VERSION "dbc-export 1 2025.20.8"

NS_ :

BS_:

BU_: ADSP APB APP APS BB BMS CC CP DAS DI DIF DIR EPAS3P EPAS3S EPBL EPBR GTW HVP ICR IDB PCS PM TCU UI UIS VC VCFRONT VCLEFT VCRIGHT VCSEC

BO_ 522 HVP_contactorState: 6 HVP
 SG_ HVP_packContNegativeState : 0|3@1+ (1,0) [1|7] "" Vector__XXX
 SG_ HVP_packContPositiveState : 3|3@1+ (1,0) [1|7] "" Vector__XXX
 SG_ HVP_fcContPositiveAuxOpen : 6|1@1+ (1,0) [0|1] "" Vector__XXX
 SG_ HVP_fcContNegativeAuxOpen : 7|1@1+ (1,0) [0|1] "" Vector__XXX
 SG_ HVP_packContactorSetState : 8|4@1+ (1,0) [1|15] "" Vector__XXX
 SG_ HVP_fcContNegativeState : 12|3@1+ (1,0) [1|7] "" Vector__XXX
 SG_ HVP_fcContPositiveState : 16|3@1+ (1,0) [1|7] "" Vector__XXX
 SG_ HVP_fcContactorSetState : 19|4@1+ (1,0) [1|15] "" Vector__XXX
 SG_ HVP_fcCtrsRequestStatus : 24|2@1+ (1,0) [0|3] "" Vector__XXX
 SG_ HVP_fcCtrsResetRequestRequired : 26|1@1+ (1,0) [0|1] "" Vector__XXX
 SG_ HVP_fcCtrsOpenNowRequested : 27|1@1+ (1,0) [0|1] "" Vector__XXX
 SG_ HVP_fcCtrsOpenRequested : 28|1@1+ (1,0) [0|1] "" Vector__XXX
 SG_ HVP_fcCtrsClosingAllowed : 29|1@1+ (1,0) [0|1] "" Vector__XXX
 SG_ HVP_packCtrsRequestStatus : 30|2@1+ (1,0) [0|3] "" Vector__XXX
 SG_ HVP_packCtrsResetRequestRequired : 32|1@1+ (1,0) [0|1] "" Vector__XXX
 SG_ HVP_packCtrsOpenNowRequested : 33|1@1+ (1,0) [0|1] "" Vector__XXX
 SG_ HVP_packCtrsOpenRequested : 34|1@1+ (1,0) [0|1] "" Vector__XXX
 SG_ HVP_packCtrsClosingAllowed : 35|1@1+ (1,0) [0|1] "" Vector__XXX
 SG_ HVP_dcLinkAllowedToEnergize : 36|1@1+ (1,0) [0|1] "" Vector__XXX
 SG_ HVP_pyroTestInProgress : 37|1@1+ (1,0) [0|1] "" Vector__XXX
 SG_ HVP_hvilDiag : 40|4@1+ (1,0) [0|15] "" Vector__XXX
 SG_ HVP_fcLinkAllowedToEnergize : 44|2@1+ (1,0) [0|3] "" Vector__XXX

BO_ 1962 HVP_debugMessage: 8 HVP
 SG_ HVP_debugMessageMultiplexer M : 0|4@1+ (1,0) [0|15] "" Vector__XXX
 SG_ HVP_gpioPassivePyroDepl m0 : 4|1@1+ (1,0) [0|1] "" Vector__XXX
 SG_ HVP_gpioPyroIsoEn m0 : 5|1@1+ (1,0) [0|1] "" Vector__XXX
 SG_ HVP_gpioCpFaultIn m0 : 6|1@1+ (1,0) [0|1] "" Vector__XXX
 SG_ HVP_gpioPackContPowerEn m0 : 7|1@1+ (1,0) [0|1] "" Vector__XXX
 SG_ HVP_gpioHvCablesOk m0 : 8|1@1+ (1,0) [0|1] "" Vector__XXX
 SG_ HVP_gpioHvpSelfEnable m0 : 9|1@1+ (1,0) [0|1] "" Vector__XXX
 SG_ HVP_gpioLed m0 : 10|1@1+ (1,0) [0|1] "" Vector__XXX
 SG_ HVP_gpioCrashSignal m0 : 11|1@1+ (1,0) [0|1] "" Vector__XXX
 SG_ HVP_gpioShuntDataReady m0 : 12|1@1+ (1,0) [0|1] "" Vector__XXX
 SG_ HVP_gpioFcContPosAux m0 : 13|1@1+ (1,0) [0|1] "" Vector__XXX
 SG_ HVP_gpioFcContNegAux m0 : 14|1@1+ (1,0) [0|1] "" Vector__XXX
 SG_ HVP_gpioBmsEout m0 : 15|1@1+ (1,0) [0|1] "" Vector__XXX
 SG_ HVP_gpioCpFaultOut m0 : 16|1@1+ (1,0) [0|1] "" Vector__XXX
 SG_ HVP_gpioPyroPor m0 : 17|1@1+ (1,0) [0|1] "" Vector__XXX
 SG_ HVP_gpioShuntEn m0 : 18|1@1+ (1,0) [0|1] "" Vector__XXX
 SG_ HVP_gpioHvpVerEn m0 : 19|1@1+ (1,0) [0|1] "" Vector__XXX
 SG_ HVP_gpioFcContFlywheelEnable m0 : 20|1@1+ (1,0) [0|1] "" Vector__XXX
 SG_ HVP_gpioCpLatchEnable m0 : 21|1@1+ (1,0) [0|1] "" Vector__XXX
 SG_ HVP_gpioFcContPowerEnable m0 : 22|1@1+ (1,0) [0|1] "" Vector__XXX
 SG_ HVP_gpioHvilEnable m0 : 23|1@1+ (1,0) [0|1] "" Vector__XXX
 SG_ HVP_gpioPortSelSpiRdy m0 : 24|1@1+ (1,0) [0|1] "" Vector__XXX
 SG_ HVP_gpioPyroUnlock m0 : 25|1@1+ (1,0) [0|1] "" Vector__XXX
 SG_ HVP_hvp1v5Ref m0 : 26|12@1+ (0.1,0) [0|3] "V" Vector__XXX
 SG_ HVP_packCurrentMia m0 : 38|1@1+ (1,0) [0|1] "" Vector__XXX
 SG_ HVP_auxCurrentMia m0 : 39|1@1+ (1,0) [0|1] "" Vector__XXX
 SG_ HVP_currentSenseMia m0 : 40|1@1+ (1,0) [0|1] "" Vector__XXX
 SG_ HVP_shuntThermistorMissing m0 : 42|1@1+ (1,0) [0|1] "" Vector__XXX
 SG_ HVP_shuntThermistorExpected m0 : 43|1@1+ (1,0) [0|1] "" Vector__XXX
 SG_ HVP_shuntThermistorMia m0 : 44|1@1+ (1,0) [0|1] "" Vector__XXX
 SG_ HVP_shuntUnexpectedThermistor m0 : 45|1@1+ (1,0) [0|1] "" Vector__XXX
 SG_ HVP_shuntHwMia m0 : 46|1@1+ (1,0) [0|1] "" Vector__XXX
 SG_ HVP_shuntCurrentIrrational m0 : 47|1@1+ (1,0) [0|1] "" Vector__XXX
 SG_ HVP_shuntAsicTCompActive m0 : 48|1@1+ (1,0) [0|1] "" Vector__XXX
 SG_ HVP_ecuLogUploadRequest m0 : 49|2@1+ (1,0) [0|3] "" Vector__XXX
 SG_ HVP_packContVoltage m2 : 4|12@1+ (0.1,0) [0|30] "V" Vector__XXX
 SG_ HVP_packNegativeV m2 : 16|16@1- (0.1,0) [-550|550] "V" Vector__XXX
 SG_ HVP_packPositiveV m2 : 32|16@1- (0.1,0) [-550|550] "V" Vector__XXX
 SG_ HVP_pyroAnalog m2 : 48|12@1+ (0.1,0) [0|3] "V" Vector__XXX
 SG_ HVP_fcContCoilCurrent m4 : 4|12@1+ (0.1,0) [0|7.5] "A" Vector__XXX
 SG_ HVP_fcContVoltage m4 : 16|12@1+ (0.1,0) [0|30] "V" Vector__XXX
 SG_ HVP_hvilInVoltage m4 : 28|12@1+ (0.1,0) [0|30] "V" Vector__XXX
 SG_ HVP_hvilOutVoltage m4 : 40|12@1+ (0.1,0) [0|30] "V" Vector__XXX
 SG_ HVP_shuntGainInvalidCountDbg m4 : 56|8@1+ (1,0) [0|255] "counts" Vector__XXX
 SG_ HVP_fcLinkPositiveV m5 : 8|16@1- (0.1,0) [-550|550] "V" Vector__XXX
 SG_ HVP_packContCoilCurrent m5 : 24|12@1+ (0.1,0) [0|7.5] "A" Vector__XXX
 SG_ HVP_battery12V m5 : 36|12@1+ (0.1,0) [0|30] "V" Vector__XXX

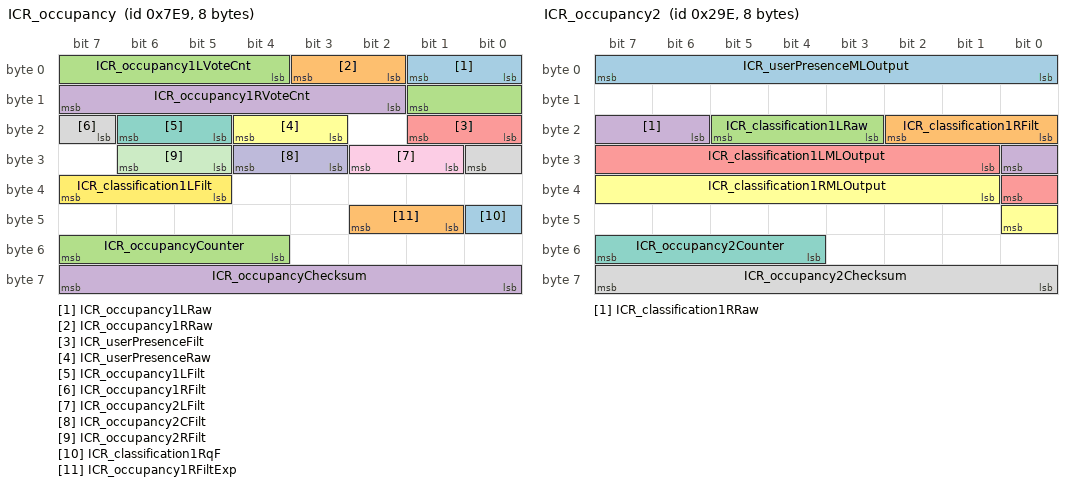
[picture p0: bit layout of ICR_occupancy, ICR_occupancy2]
BO_ 2025 ICR_occupancy: 8 ICR
 SG_ ICR_occupancy1LRaw : 0|2@1+ (1,0) [0|2] "" Vector__XXX
 SG_ ICR_occupancy1RRaw : 2|2@1+ (1,0) [0|2] "" Vector__XXX
 SG_ ICR_occupancy1LVoteCnt : 4|6@1- (1,0) [-32|31] "" Vector__XXX
 SG_ ICR_occupancy1RVoteCnt : 10|6@1- (1,0) [-32|31] "" Vector__XXX
 SG_ ICR_userPresenceFilt : 16|2@1+ (1,0) [0|2] "" Vector__XXX
 SG_ ICR_userPresenceRaw : 19|2@1+ (1,0) [0|2] "" Vector__XXX
 SG_ ICR_occupancy1LFilt : 21|2@1+ (1,0) [0|2] "" Vector__XXX
 SG_ ICR_occupancy1RFilt : 23|2@1+ (1,0) [0|2] "" Vector__XXX
 SG_ ICR_occupancy2LFilt : 25|2@1+ (1,0) [0|2] "" Vector__XXX
 SG_ ICR_occupancy2CFilt : 27|2@1+ (1,0) [0|2] "" Vector__XXX
 SG_ ICR_occupancy2RFilt : 29|2@1+ (1,0) [0|2] "" Vector__XXX
 SG_ ICR_classification1LFilt : 37|3@1+ (1,0) [1|7] "" Vector__XXX
 SG_ ICR_classification1RqF : 40|1@1+ (1,0) [0|1] "" Vector__XXX
 SG_ ICR_occupancy1RFiltExp : 41|2@1+ (1,0) [0|2] "" Vector__XXX
 SG_ ICR_occupancyCounter : 52|4@1+ (1,0) [0|15] "" Vector__XXX
 SG_ ICR_occupancyChecksum : 56|8@1+ (1,0) [0|255] "" Vector__XXX

BO_ 670 ICR_occupancy2: 8 ICR
 SG_ ICR_userPresenceMLOutput : 0|8@1+ (0.004,0) [0|1.016] "points" Vector__XXX
 SG_ ICR_classification1RFilt : 16|3@1+ (1,0) [1|7] "" Vector__XXX
 SG_ ICR_classification1LRaw : 19|3@1+ (1,0) [1|7] "" Vector__XXX
 SG_ ICR_classification1RRaw : 22|3@1+ (1,0) [1|7] "" Vector__XXX
 SG_ ICR_classification1LMLOutput : 25|8@1+ (0.004,0) [0|1.016] "points" Vector__XXX
 SG_ ICR_classification1RMLOutput : 33|8@1+ (0.004,0) [0|1.016] "points" Vector__XXX
 SG_ ICR_occupancy2Counter : 52|4@1+ (1,0) [0|15] "" Vector__XXX
 SG_ ICR_occupancy2Checksum : 56|8@1+ (1,0) [0|255] "" Vector__XXX

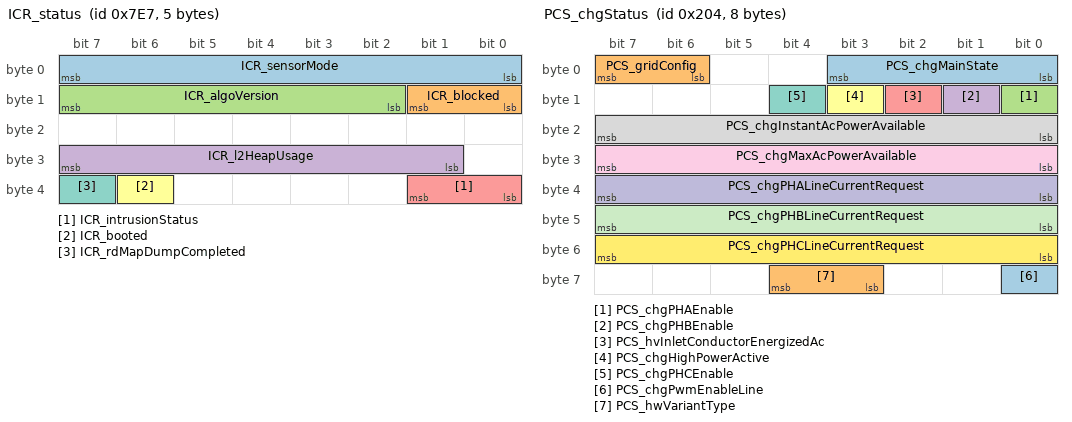
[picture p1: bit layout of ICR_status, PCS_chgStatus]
BO_ 2023 ICR_status: 5 ICR
 SG_ ICR_sensorMode : 0|8@1+ (1,0) [0|255] "" Vector__XXX
 SG_ ICR_blocked : 8|2@1+ (1,0) [1|3] "" Vector__XXX
 SG_ ICR_algoVersion : 10|6@1+ (1,0) [0|63] "" Vector__XXX
 SG_ ICR_l2HeapUsage : 25|7@1+ (1,0) [0|127] "PCT" Vector__XXX
 SG_ ICR_intrusionStatus : 32|2@1+ (1,0) [0|3] "" Vector__XXX
 SG_ ICR_booted : 38|1@1+ (1,0) [0|1] "" Vector__XXX
 SG_ ICR_rdMapDumpCompleted : 39|1@1+ (1,0) [0|1] "" Vector__XXX

BO_ 828 IDB_info: 8 IDB
 SG_ IDB_infoIndex M : 0|8@1+ (1,0) [0|255] "" Vector__XXX
 SG_ IDB_infoPcbaID m11 : 16|8@1+ (1,0) [0|255] "" Vector__XXX
 SG_ IDB_infoAssemblyID m11 : 24|8@1+ (1,0) [0|255] "" Vector__XXX
 SG_ IDB_infoUsageID m11 : 32|16@1+ (1,0) [0|65535] "" Vector__XXX
 SG_ IDB_infoSubUsageID m11 : 48|16@1+ (1,0) [0|65535] "" Vector__XXX

BO_ 516 PCS_chgStatus: 8 PCS
 SG_ PCS_chgMainState : 0|4@1+ (1,0) [0|15] "" Vector__XXX
 SG_ PCS_gridConfig : 6|2@1+ (1,0) [1|3] "" Vector__XXX
 SG_ PCS_chgPHAEnable : 8|1@1+ (1,0) [0|1] "" Vector__XXX
 SG_ PCS_chgPHBEnable : 9|1@1+ (1,0) [0|1] "" Vector__XXX
 SG_ PCS_hvInletConductorEnergizedAc : 10|1@1+ (1,0) [0|1] "" Vector__XXX
 SG_ PCS_chgHighPowerActive : 11|1@1+ (1,0) [0|1] "" Vector__XXX
 SG_ PCS_chgPHCEnable : 12|1@1+ (1,0) [0|1] "" Vector__XXX
 SG_ PCS_chgInstantAcPowerAvailable : 16|8@1+ (0.1,0) [0|20] "kW" Vector__XXX
 SG_ PCS_chgMaxAcPowerAvailable : 24|8@1+ (0.1,0) [0|20] "kW" Vector__XXX
 SG_ PCS_chgPHALineCurrentRequest : 32|8@1+ (0.1,0) [0|20] "A" Vector__XXX
 SG_ PCS_chgPHBLineCurrentRequest : 40|8@1+ (0.1,0) [0|20] "A" Vector__XXX
 SG_ PCS_chgPHCLineCurrentRequest : 48|8@1+ (0.1,0) [0|20] "A" Vector__XXX
 SG_ PCS_chgPwmEnableLine : 56|1@1+ (1,0) [0|1] "" Vector__XXX
 SG_ PCS_hwVariantType : 59|2@1+ (1,0) [0|2] "" Vector__XXX

BO_ 548 PCS_dcdcStatus: 8 PCS
 SG_ PCS_dcdcPrechargeStatus : 0|2@1+ (1,0) [0|3] "" Vector__XXX
 SG_ PCS_dcdcLvSupportStatus : 2|2@1+ (1,0) [0|3] "" Vector__XXX
 SG_ PCS_dcdcHvBusDischargeStatus : 4|2@1+ (1,0) [0|3] "" Vector__XXX
 SG_ PCS_coldSleepAllowed : 8|1@1+ (1,0) [0|1] "" Vector__XXX
 SG_ PCS_dcdcPchgHVBusLowRDetected : 9|1@1+ (1,0) [0|1] "" Vector__XXX
 SG_ PCS_dcdcSubState : 10|5@1+ (1,0) [0|31] "" Vector__XXX
 SG_ PCS_dcdcFaulted : 15|1@1+ (1,0) [0|1] "" Vector__XXX
 SG_ PCS_okToBePowerCycled : 27|1@1+ (1,0) [0|1] "" Vector__XXX
 SG_ PCS_dcdcOutputIsLimited : 28|1@1+ (1,0) [0|1] "" Vector__XXX
 SG_ PCS_dcdcMaxOutputCurrentAllowed : 29|12@1+ (0.1,0) [0|400] "A" Vector__XXX
 SG_ PCS_dcdcPrechargeRtyCnt : 41|3@1+ (1,0) [0|7] "" Vector__XXX
 SG_ PCS_dcdcLvSupportRtyCnt : 44|4@1+ (1,0) [0|15] "" Vector__XXX
 SG_ PCS_dcdcDischargeRtyCnt : 48|4@1+ (1,0) [0|15] "" Vector__XXX
 SG_ PCS_dcdcPwmEnableLine : 52|1@1+ (1,0) [0|1] "" Vector__XXX
 SG_ PCS_dcdcSupportingFixedLvTarget : 53|1@1+ (1,0) [0|1] "" Vector__XXX
 SG_ PCS_ecuLogUploadRequest : 54|2@1+ (1,0) [0|3] "" Vector__XXX
 SG_ PCS_dcdcPrechargeRestartCnt : 56|3@1+ (1,0) [0|7] "" Vector__XXX
 SG_ PCS_dcdcInitialPrechargeSubState : 59|5@1+ (1,0) [0|31] "" Vector__XXX

BO_ 708 PCS_logging: 8 PCS
 SG_ PCS_logMessageSelect M : 0|5@1+ (1,0) [0|31] "" Vector__XXX
 SG_ PCS_chgPhAInputIrms m0 : 5|9@1+ (0.1,0) [0|51.1] "A" Vector__XXX
 SG_ PCS_chgPhAIntBusV m0 : 14|9@1+ (1,0) [0|511] "V" Vector__XXX
 SG_ PCS_chgPhAIntBusVTarget m0 : 23|9@1+ (1,0) [0|511] "V" Vector__XXX
 SG_ PCS_chgPhAOutputI m0 : 32|8@1+ (0.1,0) [0|25.5] "A" Vector__XXX
 SG_ PCS_chgPhAInputCurrentLimitReaso m0 : 40|3@1+ (1,0) [0|7] "" Vector__XXX
 SG_ PCS_chgPhBInputIrms m1 : 5|9@1+ (0.1,0) [0|51.1] "A" Vector__XXX
 SG_ PCS_chgPhBIntBusV m1 : 14|9@1+ (1,0) [0|511] "V" Vector__XXX
 SG_ PCS_chgPhBIntBusVTarget m1 : 23|9@1+ (1,0) [0|511] "V" Vector__XXX
 SG_ PCS_chgPhBOutputI m1 : 32|8@1+ (0.1,0) [0|25.5] "A" Vector__XXX
 SG_ PCS_chgPhBInputCurrentLimitReaso m1 : 40|3@1+ (1,0) [0|7] "" Vector__XXX
 SG_ PCS_chgPhCInputIrms m2 : 5|9@1+ (0.1,0) [0|51.1] "A" Vector__XXX
 SG_ PCS_chgPhCIntBusV m2 : 14|9@1+ (1,0) [0|511] "V" Vector__XXX
 SG_ PCS_chgPhCIntBusVTarget m2 : 23|9@1+ (1,0) [0|511] "V" Vector__XXX
 SG_ PCS_chgPhCOutputI m2 : 32|8@1+ (0.1,0) [0|25.5] "A" Vector__XXX
 SG_ PCS_chgPhCInputCurrentLimitReaso m2 : 40|3@1+ (1,0) [0|7] "" Vector__XXX
 SG_ PCS_chgInputL1NVrms m3 : 5|12@1+ (0.2,0) [0|819] "V" Vector__XXX
 SG_ PCS_chgInputL2NVrms m3 : 17|12@1+ (0.2,0) [0|819] "V" Vector__XXX
 SG_ PCS_chgInputL3NVrms m3 : 29|12@1+ (0.2,0) [0|819] "V" Vector__XXX
 SG_ PCS_chgInputL1L2Vrms m3 : 41|12@1+ (0.2,0) [0|819] "V" Vector__XXX
 SG_ PCS_chgInputNGVrms m3 : 53|9@1+ (1,0) [0|511] "V" Vector__XXX
 SG_ PCS_chgInputFrequencyL1N m4 : 5|12@1+ (0.01,40) [40|80.95] "Hz" Vector__XXX
 SG_ PCS_chgInputFrequencyL2N m4 : 17|12@1+ (0.01,40) [40|80.95] "Hz" Vector__XXX
 SG_ PCS_chgInputFrequencyL3N m4 : 29|12@1+ (0.01,40) [40|80.95] "Hz" Vector__XXX
 SG_ PCS_chgInternalPhaseConfig m4 : 41|4@1+ (1,0) [1|15] "" Vector__XXX
 SG_ PCS_chgPhasesPriority m4 : 45|6@1+ (1,0) [0|63] "" Vector__XXX
 SG_ PCS_chgOutputV m4 : 51|12@1+ (0.146484375,0) [0|599.853515625] "V" Vector__XXX
 SG_ PCS_chgPhAState m5 : 5|4@1+ (1,0) [0|15] "" Vector__XXX
 SG_ PCS_chgPhBState m5 : 9|4@1+ (1,0) [0|15] "" Vector__XXX
 SG_ PCS_chgPhCState m5 : 13|4@1+ (1,0) [0|15] "" Vector__XXX
 SG_ PCS_chgPhALastShutdownReason m5 : 17|5@1+ (1,0) [0|31] "" Vector__XXX
 SG_ PCS_chgPhBLastShutdownReason m5 : 22|5@1+ (1,0) [0|31] "" Vector__XXX
 SG_ PCS_chgPhCLastShutdownReason m5 : 27|5@1+ (1,0) [0|31] "" Vector__XXX
 SG_ PCS_chgPhARetryCount m5 : 32|3@1+ (1,0) [0|7] "" Vector__XXX
 SG_ PCS_chgPhBRetryCount m5 : 35|3@1+ (1,0) [0|7] "" Vector__XXX
 SG_ PCS_chgPhCRetryCount m5 : 38|3@1+ (1,0) [0|7] "" Vector__XXX
 SG_ PCS_chgRetryCount m5 : 41|3@1+ (1,0) [0|7] "" Vector__XXX
 SG_ PCS_chgPhManCurrentToDist m5 : 44|10@1+ (0.1,0) [0|100] "A" Vector__XXX
 SG_ PCS_chgL1NPllLocked m5 : 54|1@1+ (1,0) [0|1] "" Vector__XXX
 SG_ PCS_chgL2NPllLocked m5 : 55|1@1+ (1,0) [0|1] "" Vector__XXX
 SG_ PCS_chgL3NPllLocked m5 : 56|1@1+ (1,0) [0|1] "" Vector__XXX
 SG_ PCS_chgL1L2PllLocked m5 : 57|1@1+ (1,0) [0|1] "" Vector__XXX
 SG_ PCS_chgNgPllLocked m5 : 58|1@1+ (1,0) [0|1] "" Vector__XXX
 SG_ PCS_chgPhManOptimalPhsToUse m5 : 59|2@1+ (1,0) [0|3] "" Vector__XXX
 SG_ PCS_chg5VL1Enable m5 : 61|1@1+ (1,0) [0|1] "" Vector__XXX
 SG_ PCS_dcdcMaxLvOutputCurrent m6 : 8|12@1+ (0.1,0) [0|400] "A" Vector__XXX
 SG_ PCS_dcdcCurrentLimit m6 : 20|12@1+ (0.1,0) [0|400] "A" Vector__XXX
 SG_ PCS_dcdcLvOutputCurrentTempLimit m6 : 32|12@1+ (0.1,0) [0|400] "A" Vector__XXX
 SG_ PCS_dcdcLvOutputCurrentFiltered m6 : 44|12@1+ (0.1,0) [0|400] "A" Vector__XXX
 SG_ PCS_dcdcUnifiedCommand m7 : 5|10@1+ (0.001,0) [0|1] "1" Vector__XXX
 SG_ PCS_dcdcCLAControllerOutput m7 : 16|10@1+ (0.001,0) [0|1] "1" Vector__XXX
 SG_ PCS_dcdcTankVoltage m7 : 26|11@1- (1,0) [-1024|1023] "V" Vector__XXX
 SG_ PCS_dcdcTankVoltageTarget m7 : 37|10@1+ (1,0) [0|1023] "V" Vector__XXX
 SG_ PCS_dcdcClaCurrentFreq m7 : 48|12@1+ (0.09765625,0) [0|399.9] "kHz" Vector__XXX
 SG_ PCS_dcdcTCommMeasured m8 : 5|16@1- (0.001953125,0) [-64|63.998] "us" Vector__XXX
 SG_ PCS_dcdcShortTimeUs m8 : 21|16@1+ (0.00048828125,0) [0|31.9995] "us" Vector__XXX
 SG_ PCS_dcdcHalfPeriodUs m8 : 37|16@1+ (0.00048828125,0) [0|31.9995] "us" Vector__XXX
 SG_ PCS_dcdcLvBusVoltTargetWithOffse m8 : 53|11@1+ (0.01,0) [0|20] "V" Vector__XXX
 SG_ PCS_cpu2BootState m9 : 5|2@1+ (1,0) [0|3] "" Vector__XXX
 SG_ PCS_acChargeSelfTestState m9 : 7|1@1+ (1,0) [0|1] "" Vector__XXX
 SG_ PCS_1V5Min10s m9 : 8|11@1+ (0.001,0) [0|2.047] "V" Vector__XXX
 SG_ PCS_1V5Max10s m9 : 19|11@1+ (0.001,0) [0|2.047] "V" Vector__XXX
 SG_ PCS_1V2Min10s m9 : 32|11@1+ (0.001,0) [0|2.047] "V" Vector__XXX
 SG_ PCS_1V2Max10s m9 : 43|11@1+ (0.001,0) [0|2.047] "V" Vector__XXX
 SG_ PCS_5VNMax10s m9 : 54|10@1+ (0.01,0) [0|10.23] "V" Vector__XXX
 SG_ PCS_chgPhAIntBusVMin10s m10 : 5|9@1+ (1,0) [0|511] "V" Vector__XXX
 SG_ PCS_chgPhAIntBusVMax10s m10 : 14|9@1+ (1,0) [0|511] "V" Vector__XXX
 SG_ PCS_chgPhAPchgVoltDeltaMax10s m10 : 23|8@1+ (0.5,0) [0|127.5] "V" Vector__XXX
 SG_ PCS_chgPhALifetimekWh m10 : 31|24@1+ (0.01,0) [0|167772.15] "kWh" Vector__XXX
 SG_ PCS_chgPhATransientRetryCount m10 : 55|9@1+ (0.1,0) [0|51.1] "-" Vector__XXX
 SG_ PCS_chgPhBIntBusVMin10s m11 : 5|9@1+ (1,0) [0|511] "V" Vector__XXX
 SG_ PCS_chgPhBIntBusVMax10s m11 : 14|9@1+ (1,0) [0|511] "V" Vector__XXX
 SG_ PCS_chgPhBPchgVoltDeltaMax10s m11 : 23|8@1+ (0.5,0) [0|127.5] "V" Vector__XXX
 SG_ PCS_chgPhBLifetimekWh m11 : 31|24@1+ (0.01,0) [0|167772.15] "kWh" Vector__XXX
 SG_ PCS_chgPhBTransientRetryCount m11 : 55|9@1+ (0.1,0) [0|51.1] "-" Vector__XXX
 SG_ PCS_chgPhCIntBusVMin10s m12 : 5|9@1+ (1,0) [0|511] "V" Vector__XXX
 SG_ PCS_chgPhCIntBusVMax10s m12 : 14|9@1+ (1,0) [0|511] "V" Vector__XXX
 SG_ PCS_chgPhCPchgVoltDeltaMax10s m12 : 23|8@1+ (0.5,0) [0|127.5] "V" Vector__XXX
 SG_ PCS_chgPhCLifetimekWh m12 : 31|24@1+ (0.01,0) [0|167772.15] "kWh" Vector__XXX
 SG_ PCS_chgPhCTransientRetryCount m12 : 55|9@1+ (0.1,0) [0|51.1] "-" Vector__XXX
 SG_ PCS_chgPhANoFlowBucket m20 : 5|9@1+ (0.01,0) [0|5.11] "-" Vector__XXX
 SG_ PCS_chgPhBNoFlowBucket m20 : 14|9@1+ (0.01,0) [0|5.11] "-" Vector__XXX
 SG_ PCS_chgPhCNoFlowBucket m20 : 23|9@1+ (0.01,0) [0|5.11] "-" Vector__XXX
 SG_ PCS_chgCurrentSensorOutOfBandUs m20 : 32|10@1+ (0.01,0) [0|10.23] "us" Vector__XXX
 SG_ PCS_chgAcpwHeartbeatState m20 : 42|3@1+ (1,0) [0|7] "" Vector__XXX
 SG_ PCS_chgKwhLostByFreqDroop m20 : 48|8@1+ (0.1,0) [0|25.5] "kWh" Vector__XXX
 SG_ PCS_chgReqKwhLostByFreqDroop m20 : 56|8@1+ (0.1,0) [0|25.5] "kWh" Vector__XXX
 SG_ PCS_dcdcLvSupportLifetimekWh m22 : 8|24@1+ (0.01,0) [0|167772.15] "kWh" Vector__XXX
 SG_ PCS_chgPwmEnableLineErrorCount m22 : 32|10@1+ (1,0) [0|1023] "" Vector__XXX
 SG_ PCS_dcdcPwmEnableLineErrorCount m22 : 42|10@1+ (1,0) [0|1023] "" Vector__XXX
 SG_ PCS_numAlertsSet m22 : 56|7@1+ (1,0) [0|127] "" Vector__XXX
 SG_ PCS_dcdcPchgStartLvBusVolt m24 : 5|10@1+ (0.0390625,0) [0|39.9609375] "V" Vector__XXX
 SG_ PCS_dcdcPchgStartHvBusVolt m24 : 16|12@1+ (0.146484375,0) [0|599.853515625] "V" Vector__XXX
 SG_ PCS_processorDieIdLot m26 : 8|24@1+ (1,0) [0|16777215] "" Vector__XXX
 SG_ PCS_processorDieIdWafer m26 : 32|8@1+ (1,0) [0|255] "" Vector__XXX
 SG_ PCS_processorDieIdX m26 : 40|12@1+ (1,0) [0|4095] "" Vector__XXX
 SG_ PCS_processorDieIdY m26 : 52|12@1+ (1,0) [0|4095] "" Vector__XXX

BO_ 463 PM_systemState: 8 PM
 SG_ PM_hvilSystemStatus : 24|2@1+ (1,0) [0|2] "" Vector__XXX

BO_ 1409 TCU_log: 8 TCU
 SG_ TCU_logMux M : 0|32@1+ (1,0) [0|4294967295] "" Vector__XXX
 SG_ TCU_cpuTemp m0 : 32|32@1+ (1,0) [0|4294967295] "C" Vector__XXX
 SG_ TCU_cpuUsage m1 : 32|32@1+ (1,0) [0|4294967295] "%" Vector__XXX
 SG_ TCU_mdmCoreTemperature m2 : 32|32@1+ (1,0) [0|4294967295] "C" Vector__XXX
 SG_ TCU_availableMemory m3 : 32|32@1+ (1,0) [0|4294967295] "KB" Vector__XXX
 SG_ TCU_pwm m4 : 32|32@1+ (1,0) [0|4294967295] "" Vector__XXX
 SG_ TCU_pwmcap m5 : 32|32@1+ (1,0) [0|4294967295] "" Vector__XXX
 SG_ TCU_totalResumes m6 : 32|32@1+ (1,0) [0|4294967295] "" Vector__XXX
 SG_ TCU_mdmUplinkQueueSize m7 : 32|32@1+ (1,0) [0|4294967295] "bytes" Vector__XXX
 SG_ TCU_mdmRSRP m8 : 32|32@1- (1,0) [-2147483648|2147483647] "dBm" Vector__XXX
 SG_ TCU_mdmSINR m9 : 32|32@1- (1,0) [-2147483648|2147483647] "dBm" Vector__XXX
 SG_ TCU_mdmUplinkAllowedRate m10 : 32|32@1+ (1,0) [0|4294967295] "Kbps" Vector__XXX
 SG_ TCU_mdmServiceState m12 : 32|32@1+ (1,0) [0|4294967295] "" Vector__XXX
 SG_ TCU_mdmIMSStatus m13 : 32|32@1+ (1,0) [0|4294967295] "" Vector__XXX
 SG_ TCU_mdmSIMStatus m14 : 32|32@1+ (1,0) [0|4294967295] "" Vector__XXX
 SG_ TCU_mdmBusyActive m15 : 32|32@1+ (1,0) [0|4294967294] "" Vector__XXX

BO_ 1056 UIS_log: 8 UIS
 SG_ UIS_logMux M : 0|32@1+ (1,0) [0|4294967295] "" Vector__XXX
 SG_ UIS_wifiTemperature m11 : 32|32@1+ (1,0) [0|4294967295] "" Vector__XXX
 SG_ UIS_wifiStackState m12 : 32|32@1+ (1,0) [0|4294967295] "" Vector__XXX
 SG_ UIS_wifiBars m14 : 32|32@1+ (1,0) [0|4294967295] "" Vector__XXX
 SG_ UIS_wifiAutoJoinLowRSSI m15 : 32|32@1+ (1,0) [0|1] "" Vector__XXX
 SG_ UIS_valetMode m26 : 32|32@1+ (1,0) [0|1] "" Vector__XXX
 SG_ UIS_uiQtCarUptime m27 : 32|32@1+ (1,0) [0|4294967295] "" Vector__XXX
 SG_ UIS_uiMeanFPS m29 : 32|32@1+ (1,0) [0|4294967295] "" Vector__XXX
 SG_ UIS_tunerVoltageOperation m34 : 32|32@1+ (1,0) [0|4294967295] "" Vector__XXX
 SG_ UIS_tunerVoltageAntenna2 m36 : 32|32@1+ (1,0) [0|4294967295] "" Vector__XXX
 SG_ UIS_tunerVoltageAntenna1 m37 : 32|32@1+ (1,0) [0|4294967295] "" Vector__XXX
 SG_ UIS_tunerCurrentAntenna2 m42 : 32|32@1+ (1,0) [0|4294967295] "" Vector__XXX
 SG_ UIS_tunerCurrentAntenna1 m43 : 32|32@1+ (1,0) [0|4294967295] "" Vector__XXX
 SG_ UIS_tegraModemManState m56 : 32|32@1+ (1,0) [0|4294967295] "" Vector__XXX
 SG_ UIS_systemWakeTime m57 : 32|32@1+ (1,0) [0|4294967295] "" Vector__XXX
 SG_ UIS_systemUptime m58 : 32|32@1+ (1,0) [0|4294967295] "" Vector__XXX
 SG_ UIS_suspensionGeofence m60 : 32|32@1+ (1,0) [0|1] "" Vector__XXX
 SG_ UIS_superchargePaymentNeeded m61 : 32|32@1+ (1,0) [0|4294967295] "" Vector__XXX
 SG_ UIS_sleepType m70 : 32|32@1+ (1,0) [0|4294967295] "" Vector__XXX
 SG_ UIS_sleepTime m71 : 32|32@1+ (1,0) [0|4294967295] "" Vector__XXX
 SG_ UIS_sleepState m72 : 32|32@1+ (1,0) [0|4294967295] "" Vector__XXX
 SG_ UIS_slackerLoginResult m74 : 32|32@1+ (1,0) [0|4294967295] "" Vector__XXX
 SG_ UIS_sentryState m80 : 32|32@1+ (1,0) [0|4294967295] "" Vector__XXX
 SG_ UIS_sentryNeedsNap m81 : 32|32@1+ (1,0) [0|4294967295] "" Vector__XXX
 SG_ UIS_sentryIncidentCount m82 : 32|32@1+ (1,0) [0|4294967295] "" Vector__XXX
 SG_ UIS_scheduledChargingMode m83 : 32|32@1+ (1,0) [0|4294967295] "" Vector__XXX
 SG_ UIS_scheduleChargeStartTime m84 : 32|32@1+ (1,0) [0|4294967295] "" Vector__XXX
 SG_ UIS_scheduleChargeEndTime m85 : 32|32@1+ (1,0) [0|4294967295] "" Vector__XXX
 SG_ UIS_remoteRequestType m86 : 32|32@1+ (1,0) [0|4294967295] "" Vector__XXX
 SG_ UIS_rearDisplayUserPresent m89 : 32|32@1+ (1,0) [0|1] "" Vector__XXX
 SG_ UIS_rearDisplayState m90 : 32|32@1+ (1,0) [0|4294967295] "" Vector__XXX
 SG_ UIS_powerManagerState m100 : 32|5@1+ (1,0) [0|31] "" Vector__XXX
 SG_ UIS_polytopiax8664MemUsage m101 : 32|32@1+ (1,0) [0|4294967295] "" Vector__XXX
 SG_ UIS_polytopiax8664CPUUsage m102 : 32|32@1+ (1,0) [0|4294967295] "" Vector__XXX
 SG_ UIS_navAudioVolume m132 : 32|32@1+ (1,0) [0|4294967295] "" Vector__XXX
 SG_ UIS_muteNavVolume m133 : 32|32@1+ (1,0) [0|4294967295] "" Vector__XXX
 SG_ UIS_modemECallppAvail m145 : 32|32@1+ (1,0) [0|1] "" Vector__XXX
 SG_ UIS_modemBusyActive m146 : 32|32@1+ (1,0) [0|1] "" Vector__XXX
 SG_ UIS_mirrorGeofenceActive m147 : 32|32@1+ (1,0) [0|1] "" Vector__XXX
 SG_ UIS_mediaPlaybackStatus m150 : 32|32@1+ (1,0) [0|4294967295] "" Vector__XXX
 SG_ UIS_mediaNeedAuthToken m151 : 32|32@1+ (1,0) [0|1] "" Vector__XXX
 SG_ UIS_inSuperchargerGeofence m156 : 32|32@1+ (1,0) [0|1] "" Vector__XXX
 SG_ UIS_homelinkState m158 : 32|32@1+ (1,0) [0|4294967295] "" Vector__XXX
 SG_ UIS_headsetPairResult m163 : 32|32@1+ (1,0) [0|4294967295] "" Vector__XXX
 SG_ UIS_headsetConnectionState m164 : 32|32@1+ (1,0) [0|4294967295] "" Vector__XXX
 SG_ UIS_gpsmanagerMemUsage m178 : 32|32@1+ (1,0) [0|4294967295] "" Vector__XXX
 SG_ UIS_gpsmanagerCPUUsage m179 : 32|32@1+ (1,0) [0|4294967295] "" Vector__XXX
 SG_ UIS_featureSuperchargingEnabled m187 : 32|32@1+ (1,0) [0|4294967295] "" Vector__XXX
 SG_ UIS_dmRearTouchDeviceExists m196 : 32|32@1+ (1,0) [0|4294967295] "" Vector__XXX
 SG_ UIS_dmRearPowerState m197 : 32|32@1+ (1,0) [0|1] "" Vector__XXX
 SG_ UIS_dmRearLinkCheckOk m198 : 32|32@1+ (1,0) [0|1] "" Vector__XXX
 SG_ UIS_dmRearEnabled m199 : 32|32@1+ (1,0) [0|4294967295] "" Vector__XXX
 SG_ UIS_dmRearConnected m200 : 32|32@1+ (1,0) [0|4294967295] "" Vector__XXX
 SG_ UIS_dmRearBacklightDutyCycle m204 : 32|32@1+ (1,0) [0|4294967295] "" Vector__XXX
 SG_ UIS_dmRearBacklightDevExists m205 : 32|32@1+ (1,0) [0|1] "" Vector__XXX
 SG_ UIS_dmIcuPowerState m209 : 32|32@1+ (1,0) [0|1] "" Vector__XXX
 SG_ UIS_dmIcuLinkCheckOk m210 : 32|32@1+ (1,0) [0|1] "" Vector__XXX
 SG_ UIS_dmIcuEnabled m211 : 32|32@1+ (1,0) [0|4294967295] "" Vector__XXX
 SG_ UIS_dmIcuConnected m212 : 32|32@1+ (1,0) [0|4294967295] "" Vector__XXX
 SG_ UIS_dmIcuBacklightDutyCycle m216 : 32|32@1+ (1,0) [0|4294967295] "" Vector__XXX
 SG_ UIS_dmIcuBacklightDevExists m217 : 32|32@1+ (1,0) [0|1] "" Vector__XXX
 SG_ UIS_dmGatewayLinkWedged m222 : 32|32@1+ (1,0) [0|4294967295] "" Vector__XXX
 SG_ UIS_dmCenterTouchDeviceExists m224 : 32|32@1+ (1,0) [0|4294967295] "" Vector__XXX
 SG_ UIS_dmCenterPowerState m227 : 32|32@1+ (1,0) [0|1] "" Vector__XXX
 SG_ UIS_dmCenterOsdDisplayedState m228 : 32|32@1+ (1,0) [0|1] "" Vector__XXX
 SG_ UIS_dmCenterLinkCheckOk m233 : 32|32@1+ (1,0) [0|1] "" Vector__XXX
 SG_ UIS_dmCenterEnabled m234 : 32|32@1+ (1,0) [0|4294967295] "" Vector__XXX
 SG_ UIS_dmCenterConnected m235 : 32|32@1+ (1,0) [0|4294967295] "" Vector__XXX
 SG_ UIS_dmCenterBacklightPowerLevel m236 : 32|32@1+ (1,0) [0|4294967295] "" Vector__XXX
 SG_ UIS_dmCenterBacklightDutyCycle m239 : 32|32@1+ (1,0) [0|4294967295] "" Vector__XXX
 SG_ UIS_dmCenterBacklightDevExists m240 : 32|32@1+ (1,0) [0|1] "" Vector__XXX
 SG_ UIS_dgpuTemperature m245 : 32|32@1+ (1,0) [0|4294967295] "" Vector__XXX
 SG_ UIS_dashcamviewerMemUsage m247 : 32|32@1+ (1,0) [0|4294967295] "" Vector__XXX
 SG_ UIS_dashcamviewerCPUUsage m248 : 32|32@1+ (1,0) [0|4294967295] "" Vector__XXX
 SG_ UIS_dashcamStorageState m254 : 32|32@1+ (1,0) [0|4294967295] "" Vector__XXX
 SG_ UIS_dashcamStorageSentryMB m255 : 32|32@1+ (1,0) [0|4294967295] "" Vector__XXX
 SG_ UIS_dashcamStorageSavedMB m256 : 32|32@1+ (1,0) [0|4294967295] "" Vector__XXX
 SG_ UIS_dashcamStorageRecentMB m257 : 32|32@1+ (1,0) [0|4294967295] "" Vector__XXX
 SG_ UIS_dashcamStorageAvailableMB m258 : 32|32@1+ (1,0) [0|4294967295] "" Vector__XXX
 SG_ UIS_dashcamState m259 : 32|32@1+ (1,0) [0|4294967295] "" Vector__XXX
 SG_ UIS_cpuTemperature m267 : 32|32@1+ (1,0) [0|4294967295] "" Vector__XXX
 SG_ UIS_clusterMemUsage m279 : 32|32@1+ (1,0) [0|4294967295] "" Vector__XXX
 SG_ UIS_clusterDisplayState m284 : 32|32@1+ (1,0) [0|4294967295] "" Vector__XXX
 SG_ UIS_clusterCPUUsage m285 : 32|32@1+ (1,0) [0|4294967295] "" Vector__XXX
 SG_ UIS_chargeOnSolarNoChargeReason m288 : 32|32@1+ (1,0) [0|4294967295] "" Vector__XXX
 SG_ UIS_centerDisplayState m291 : 32|32@1+ (1,0) [0|4294967295] "" Vector__XXX
 SG_ UIS_centerDisplayEvent m292 : 32|32@1+ (1,0) [0|4294967295] "" Vector__XXX
 SG_ UIS_cellularLinkManagerState m297 : 32|32@1+ (1,0) [0|4294967295] "" Vector__XXX
 SG_ UIS_carAssistState m298 : 32|32@1+ (1,0) [0|4294967295] "" Vector__XXX
 SG_ UIS_carAssistSessionCount m299 : 32|32@1+ (1,0) [0|4294967295] "" Vector__XXX
 SG_ UIS_carAssistErrorCode m300 : 32|32@1+ (1,0) [0|4294967295] "" Vector__XXX
 SG_ UIS_cameraRRepeaterStreamMissing m301 : 32|32@1+ (1,0) [0|1] "" Vector__XXX
 SG_ UIS_cameraRRepeaterPopup m303 : 32|32@1+ (1,0) [0|1] "" Vector__XXX
 SG_ UIS_cameraRRepeaterPipeline m304 : 32|32@1+ (1,0) [0|4294967295] "" Vector__XXX
 SG_ UIS_cameraLRepeaterStreamMissing m308 : 32|32@1+ (1,0) [0|1] "" Vector__XXX
 SG_ UIS_cameraLRepeaterPopup m310 : 32|32@1+ (1,0) [0|1] "" Vector__XXX
 SG_ UIS_cameraLRepeaterPipeline m311 : 32|32@1+ (1,0) [0|4294967295] "" Vector__XXX
 SG_ UIS_cameraBackupStreamMissing m320 : 32|32@1+ (1,0) [0|1] "" Vector__XXX
 SG_ UIS_cameraBackupPopup m322 : 32|32@1+ (1,0) [0|1] "" Vector__XXX
 SG_ UIS_cameraBackupPipeline m323 : 32|32@1+ (1,0) [0|4294967295] "" Vector__XXX
 SG_ UIS_cameraBackupFramerate m326 : 32|32@1+ (1,0) [0|4294967295] "" Vector__XXX
 SG_ UIS_boardTemperature m332 : 32|32@1+ (1,0) [0|4294967295] "" Vector__XXX
 SG_ UIS_bluetoothStackState m333 : 32|32@1+ (1,0) [0|4294967295] "" Vector__XXX
 SG_ UIS_bluetoothStackRearState m334 : 32|32@1+ (1,0) [0|4294967295] "" Vector__XXX
 SG_ UIS_bluetoothPairResult m335 : 32|32@1+ (1,0) [0|4294967295] "" Vector__XXX
 SG_ UIS_bluetoothMemUsage m336 : 32|32@1+ (1,0) [0|4294967295] "" Vector__XXX
 SG_ UIS_bluetoothConnectionState m337 : 32|32@1+ (1,0) [0|4294967295] "" Vector__XXX
 SG_ UIS_bluetoothCPUUsage m338 : 32|32@1+ (1,0) [0|4294967295] "" Vector__XXX
 SG_ UIS_bluetoothAutoConnectionState m339 : 32|32@1+ (1,0) [0|4294967295] "" Vector__XXX
 SG_ UIS_backlightUserRequest m344 : 32|32@1+ (1,0) [0|4294967295] "" Vector__XXX
 SG_ UIS_audioVolumeLevel m345 : 32|32@1+ (1,0) [0|4294967295] "" Vector__XXX
 SG_ UIS_audioType m346 : 32|32@1+ (1,0) [0|4294967295] "" Vector__XXX
 SG_ UIS_audioState m347 : 32|32@1+ (1,0) [0|4294967295] "" Vector__XXX
 SG_ UIS_audioSource m348 : 32|32@1+ (1,0) [0|4294967295] "" Vector__XXX
 SG_ UIS_audioPWSGain m349 : 32|32@1+ (1,0) [0|4294967295] "" Vector__XXX
 SG_ UIS_audioMediaPlaying m350 : 32|32@1+ (1,0) [0|4294967295] "" Vector__XXX
 SG_ UIS_audioMediaBrowsing m351 : 32|32@1+ (1,0) [0|4294967295] "" Vector__XXX
 SG_ UIS_audioA2BRediscoveryCount m352 : 32|32@1+ (1,0) [0|4294967295] "" Vector__XXX
 SG_ UIS_activeAppView m354 : 32|32@1+ (1,0) [0|4294967295] "" Vector__XXX

BO_ 979 UI_airbagCutoffStatus: 1 UI
 SG_ UI_airbagCutoffSwState : 0|2@1+ (1,0) [0|3] "" Vector__XXX

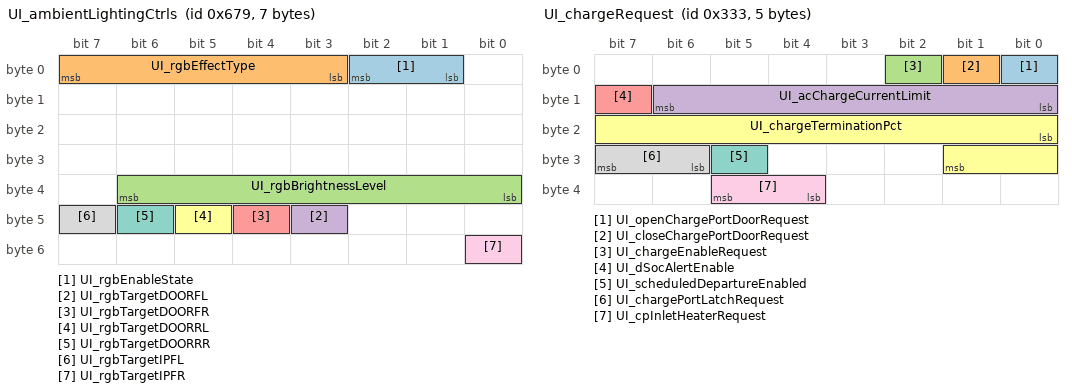
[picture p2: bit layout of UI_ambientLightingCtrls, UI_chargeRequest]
BO_ 1657 UI_ambientLightingCtrls: 7 UI
 SG_ UI_rgbEnableState : 1|2@1+ (1,0) [0|3] "" Vector__XXX
 SG_ UI_rgbEffectType : 3|5@1+ (1,0) [0|31] "" Vector__XXX
 SG_ UI_rgbBrightnessLevel : 32|7@1+ (1,0) [0|100] "%" Vector__XXX
 SG_ UI_rgbTargetDOORFL : 43|1@1+ (1,0) [0|1] "" Vector__XXX
 SG_ UI_rgbTargetDOORFR : 44|1@1+ (1,0) [0|1] "" Vector__XXX
 SG_ UI_rgbTargetDOORRL : 45|1@1+ (1,0) [0|1] "" Vector__XXX
 SG_ UI_rgbTargetDOORRR : 46|1@1+ (1,0) [0|1] "" Vector__XXX
 SG_ UI_rgbTargetIPFL : 47|1@1+ (1,0) [0|1] "" Vector__XXX
 SG_ UI_rgbTargetIPFR : 48|1@1+ (1,0) [0|1] "" Vector__XXX

BO_ 1021 UI_autopilotControl: 8 UI
 SG_ UI_autopilotControlIndex M : 0|3@1+ (1,0) [0|7] "" Vector__XXX
 SG_ UI_hovEnabled m0 : 3|1@1+ (1,0) [0|1] "" Vector__XXX
 SG_ UI_smartSetSpeedOffset m0 : 25|6@1+ (1,-30) [-30|33] "%" Vector__XXX
 SG_ UI_smartSetSpeedOffsetType m0 : 31|1@1+ (1,0) [0|1] "" Vector__XXX
 SG_ UI_fsdStopsControlEnabled m0 : 38|1@1+ (1,0) [0|1] "" Vector__XXX
 SG_ UI_smartSetSpeed m0 : 40|1@1+ (1,0) [0|1] "" Vector__XXX
 SG_ UI_automaticSetSpeedOffset m0 : 41|1@1+ (1,0) [0|1] "" Vector__XXX
 SG_ UI_enableFullSelfDriving m0 : 46|1@1+ (1,0) [0|1] "" Vector__XXX
 SG_ UI_hasFullSelfDriving m0 : 47|1@1+ (1,0) [0|1] "" Vector__XXX
 SG_ UI_autosteerActivation m0 : 48|1@1+ (1,0) [0|1] "" Vector__XXX
 SG_ UI_autopilotDrivingProfile m0 : 49|2@1+ (1,0) [0|3] "" Vector__XXX
 SG_ UI_fsdBetaRequest m0 : 51|1@1+ (1,0) [0|1] "" Vector__XXX
 SG_ UI_fullSelfDrivingSuspended m0 : 52|1@1+ (1,0) [0|1] "" Vector__XXX
 SG_ UI_disableOptionalLaneChanges m0 : 53|1@1+ (1,0) [0|1] "" Vector__XXX
 SG_ UI_selectableCameraRequest m1 : 8|4@1+ (1,0) [0|14] "" Vector__XXX
 SG_ UI_driverMonitorConfirmation m1 : 17|1@1+ (1,0) [0|1] "" Vector__XXX
 SG_ UI_parkAssistUseVision m1 : 18|1@1+ (1,0) [0|1] "" Vector__XXX
 SG_ UI_noStalkConfirmAlertHaptic m1 : 32|1@1+ (1,0) [0|1] "" Vector__XXX
 SG_ UI_noStalkConfirmAlertChime m1 : 37|1@1+ (1,0) [0|1] "" Vector__XXX
 SG_ UI_factorySummonEnable m1 : 39|1@1+ (1,0) [0|1] "" Vector__XXX
 SG_ UI_enableCabinCamera m1 : 43|1@1+ (1,0) [0|1] "" Vector__XXX
 SG_ UI_enableAutopilotStopWarning m1 : 44|1@1+ (1,0) [0|1] "" Vector__XXX
 SG_ UI_enableVisionSpeedControl m1 : 49|1@1+ (1,0) [0|1] "" Vector__XXX
 SG_ UI_enableTeslaAutopark m1 : 51|1@1+ (1,0) [0|1] "" Vector__XXX
 SG_ UI_autoTurnSignalMode m1 : 52|1@1+ (1,0) [0|1] "" Vector__XXX
 SG_ UI_enableCabinAudioRecording m1 : 59|1@1+ (1,0) [0|1] "" Vector__XXX

BO_ 819 UI_chargeRequest: 5 UI
 SG_ UI_openChargePortDoorRequest : 0|1@1+ (1,0) [0|1] "" Vector__XXX
 SG_ UI_closeChargePortDoorRequest : 1|1@1+ (1,0) [0|1] "" Vector__XXX
 SG_ UI_chargeEnableRequest : 2|1@1+ (1,0) [0|1] "" Vector__XXX
 SG_ UI_acChargeCurrentLimit : 8|7@1+ (1,0) [0|126] "A" Vector__XXX
 SG_ UI_dSocAlertEnable : 15|1@1+ (1,0) [0|1] "" Vector__XXX
 SG_ UI_chargeTerminationPct : 16|10@1+ (0.1,0) [5|100] "%" Vector__XXX
 SG_ UI_scheduledDepartureEnabled : 29|1@1+ (1,0) [0|1] "" Vector__XXX
 SG_ UI_chargePortLatchRequest : 30|2@1+ (1,0) [0|3] "" Vector__XXX
 SG_ UI_cpInletHeaterRequest : 36|2@1+ (1,0) [0|3] "" Vector__XXX

BO_ 531 UI_cruiseControl: 2 UI
 SG_ UI_cruiseSpeedCommand : 0|3@1+ (1,0) [0|7] "" Vector__XXX

BO_ 645 UI_driverProfileRecall: 8 UI
 SG_ UI_driverProfileRecallIndex M : 0|3@1+ (1,0) [1|7] "" Vector__XXX
 SG_ UI_driverProfileRecallStop : 3|1@1+ (1,0) [0|1] "" Vector__XXX
 SG_ UI_frontSeatRecallActive m1 : 4|1@1+ (1,0) [0|1] "" Vector__XXX
 SG_ UI_leftMirrorTiltXPosition m3 : 8|8@1+ (0.02,0) [0|5] "V" Vector__XXX
 SG_ UI_leftMirrorTiltYPosition m3 : 16|8@1+ (0.02,0) [0|5] "V" Vector__XXX
 SG_ UI_customMirrorDipPositionsSet m4 : 5|1@1+ (1,0) [0|1] "" Vector__XXX
 SG_ UI_leftMirrorDipXPosition m4 : 8|8@1+ (0.02,0) [0|5] "V" Vector__XXX
 SG_ UI_leftMirrorDipYPosition m4 : 16|8@1+ (0.02,0) [0|5] "V" Vector__XXX
 SG_ UI_modifyMirrorDipRequest m4 : 40|2@1+ (1,0) [0|3] "" Vector__XXX

BO_ 1279 UI_energyConsumptionInfo: 8 UI
 SG_ UI_energyConsumptionInfoIndex M : 0|5@1+ (1,0) [0|31] "" Vector__XXX
 SG_ UI_energyLossTotal_epa m0 : 16|16@1- (1,0) [-32768|32767] "Wh" Vector__XXX
 SG_ UI_energyLossDriving_epa m0 : 32|16@1- (1,0) [-32768|32767] "Wh" Vector__XXX
 SG_ UI_energyLossClimate_epa m0 : 48|16@1- (1,0) [-32768|32767] "Wh" Vector__XXX
 SG_ UI_energyLossBattCond_epa m1 : 16|16@1- (1,0) [-32768|32767] "Wh" Vector__XXX
 SG_ UI_energyLossElevation_epa m1 : 32|16@1- (1,0) [-32768|32767] "Wh" Vector__XXX
 SG_ UI_energyLossAcc_epa m1 : 48|16@1- (1,0) [-32768|32767] "Wh" Vector__XXX
 SG_ UI_energyLossTotalSinceCharge_ep m2 : 16|16@1- (1,0) [-32768|32767] "Wh" Vector__XXX
 SG_ UI_energyLossDrivingSinceCharge_ m2 : 32|16@1- (1,0) [-32768|32767] "Wh" Vector__XXX
 SG_ UI_energyLossClimateSinceCharge_ m2 : 48|16@1- (1,0) [-32768|32767] "Wh" Vector__XXX
 SG_ UI_energyLossBattCondSinceCharge m3 : 16|16@1- (1,0) [-32768|32767] "Wh" Vector__XXX
 SG_ UI_energyLossElevationSinceCharg m3 : 32|16@1- (1,0) [-32768|32767] "Wh" Vector__XXX
 SG_ UI_energyLossAccSinceCharge_epa m3 : 48|16@1- (1,0) [-32768|32767] "Wh" Vector__XXX
 SG_ UI_energyLossTotalSinceTripStart m4 : 16|16@1- (1,0) [-32768|32767] "Wh" Vector__XXX
 SG_ UI_energyLossDrivingSinceTripSta m4 : 32|16@1- (1,0) [-32768|32767] "Wh" Vector__XXX
 SG_ UI_energyLossClimateSinceTripSta m4 : 48|16@1- (1,0) [-32768|32767] "Wh" Vector__XXX
 SG_ UI_energyLossBattCondSinceTripSt m5 : 16|16@1- (1,0) [-32768|32767] "Wh" Vector__XXX
 SG_ UI_energyLossElevationSinceTripS m5 : 32|16@1- (1,0) [-32768|32767] "Wh" Vector__XXX
 SG_ UI_energyLossAccSinceTripStart m5 : 48|16@1- (1,0) [-32768|32767] "Wh" Vector__XXX
 SG_ UI_energyDeltaTotal_epa m6 : 16|16@1- (1,0) [-32768|32767] "Wh" Vector__XXX
 SG_ UI_energyDeltaDriving_epa m6 : 32|16@1- (1,0) [-32768|32767] "Wh" Vector__XXX
 SG_ UI_energyDeltaClimate_epa m6 : 48|16@1- (1,0) [-32768|32767] "Wh" Vector__XXX
 SG_ UI_energyDeltaBattCond_epa m7 : 16|16@1- (1,0) [-32768|32767] "Wh" Vector__XXX
 SG_ UI_energyDeltaElevation_epa m7 : 32|16@1- (1,0) [-32768|32767] "Wh" Vector__XXX
 SG_ UI_energyDeltaAcc_epa m7 : 48|16@1- (1,0) [-32768|32767] "Wh" Vector__XXX
 SG_ UI_uiDeltaOffsetTotal_epa m8 : 16|16@1- (1,0) [-32768|32767] "Wh" Vector__XXX
 SG_ UI_uiDeltaOffsetDriving_epa m8 : 32|16@1- (1,0) [-32768|32767] "Wh" Vector__XXX
 SG_ UI_uiDeltaOffsetClimate_epa m8 : 48|16@1- (1,0) [-32768|32767] "Wh" Vector__XXX
 SG_ UI_uiDeltaOffsetBattCond_epa m9 : 16|16@1- (1,0) [-32768|32767] "Wh" Vector__XXX
 SG_ UI_uiDeltaOffsetElevation_epa m9 : 32|16@1- (1,0) [-32768|32767] "Wh" Vector__XXX
 SG_ UI_uiDeltaOffsetAcc_epa m9 : 48|16@1- (1,0) [-32768|32767] "Wh" Vector__XXX
 SG_ UI_rawToUiEnergyRatio_epa m10 : 8|8@1+ (0.01,0) [0|2.55] "-" Vector__XXX
 SG_ UI_driveDistance_epa m10 : 16|16@1+ (0.01,0) [0|655.35] "miles" Vector__XXX
 SG_ UI_energyDeltaTotalSinceCharge_e m11 : 16|16@1- (1,0) [-32768|32767] "Wh" Vector__XXX
 SG_ UI_energyDeltaDrivingSinceCharge m11 : 32|16@1- (1,0) [-32768|32767] "Wh" Vector__XXX
 SG_ UI_energyDeltaClimateSinceCharge m11 : 48|16@1- (1,0) [-32768|32767] "Wh" Vector__XXX
 SG_ UI_energyDeltaBattCondSinceCharg m12 : 16|16@1- (1,0) [-32768|32767] "Wh" Vector__XXX
 SG_ UI_energyDeltaElevationSinceChar m12 : 32|16@1- (1,0) [-32768|32767] "Wh" Vector__XXX
 SG_ UI_energyDeltaAccSinceCharge_epa m12 : 48|16@1- (1,0) [-32768|32767] "Wh" Vector__XXX
 SG_ UI_uiDeltaOffsetTotalSinceCharge m13 : 16|16@1- (1,0) [-32768|32767] "Wh" Vector__XXX
 SG_ UI_uiDeltaOffsetDrivingSinceChar m13 : 32|16@1- (1,0) [-32768|32767] "Wh" Vector__XXX
 SG_ UI_uiDeltaOffsetClimateSinceChar m13 : 48|16@1- (1,0) [-32768|32767] "Wh" Vector__XXX
 SG_ UI_uiDeltaOffsetBattCondSinceCha m14 : 16|16@1- (1,0) [-32768|32767] "Wh" Vector__XXX
 SG_ UI_uiDeltaOffsetElevationSinceCh m14 : 32|16@1- (1,0) [-32768|32767] "Wh" Vector__XXX
 SG_ UI_uiDeltaOffsetAccSinceCharge_e m14 : 48|16@1- (1,0) [-32768|32767] "Wh" Vector__XXX
 SG_ UI_rawToUiEnergyRatioSinceCharge m15 : 8|8@1+ (0.01,0) [0|2.55] "-" Vector__XXX
 SG_ UI_driveDistanceSinceCharge_epa m15 : 16|16@1+ (0.01,0) [0|655.35] "miles" Vector__XXX
 SG_ UI_energyDeltaTotalSinceTripStar m16 : 16|16@1- (1,0) [-32768|32767] "Wh" Vector__XXX
 SG_ UI_energyDeltaDrivingSinceTripSt m16 : 32|16@1- (1,0) [-32768|32767] "Wh" Vector__XXX
 SG_ UI_energyDeltaClimateSinceTripSt m16 : 48|16@1- (1,0) [-32768|32767] "Wh" Vector__XXX
 SG_ UI_energyDeltaBattCondSinceTripS m17 : 16|16@1- (1,0) [-32768|32767] "Wh" Vector__XXX
 SG_ UI_energyDeltaElevationSinceTrip m17 : 32|16@1- (1,0) [-32768|32767] "Wh" Vector__XXX
 SG_ UI_energyDeltaAccSinceTripStart m17 : 48|16@1- (1,0) [-32768|32767] "Wh" Vector__XXX
 SG_ UI_uiDeltaOffsetTotalSinceTripSt m18 : 16|16@1- (1,0) [-32768|32767] "Wh" Vector__XXX
 SG_ UI_uiDeltaOffsetDrivingSinceTrip m18 : 32|16@1- (1,0) [-32768|32767] "Wh" Vector__XXX
 SG_ UI_uiDeltaOffsetClimateSinceTrip m18 : 48|16@1- (1,0) [-32768|32767] "Wh" Vector__XXX
 SG_ UI_uiDeltaOffsetBattCondSinceTri m19 : 16|16@1- (1,0) [-32768|32767] "Wh" Vector__XXX
 SG_ UI_uiDeltaOffsetElevationSinceTr m19 : 32|16@1- (1,0) [-32768|32767] "Wh" Vector__XXX
 SG_ UI_uiDeltaOffsetAccSinceTripStar m19 : 48|16@1- (1,0) [-32768|32767] "Wh" Vector__XXX
 SG_ UI_rawToUiEnergyRatioSinceTripSt m20 : 8|8@1+ (0.01,0) [0|2.55] "-" Vector__XXX
 SG_ UI_driveDistanceSinceTripStart m20 : 16|16@1+ (0.01,0) [0|655.35] "miles" Vector__XXX
 SG_ UI_trailerMass m21 : 16|16@1+ (1,0) [0|65535] "kg" Vector__XXX

BO_ 1139 UI_ethNm: 8 UI
 SG_ UI_nmKeepAwakeReason : 16|5@1+ (1,0) [1|31] "" Vector__XXX
 SG_ UI_wakeupTime : 32|32@1+ (1,0) [0|4294967295] "" Vector__XXX

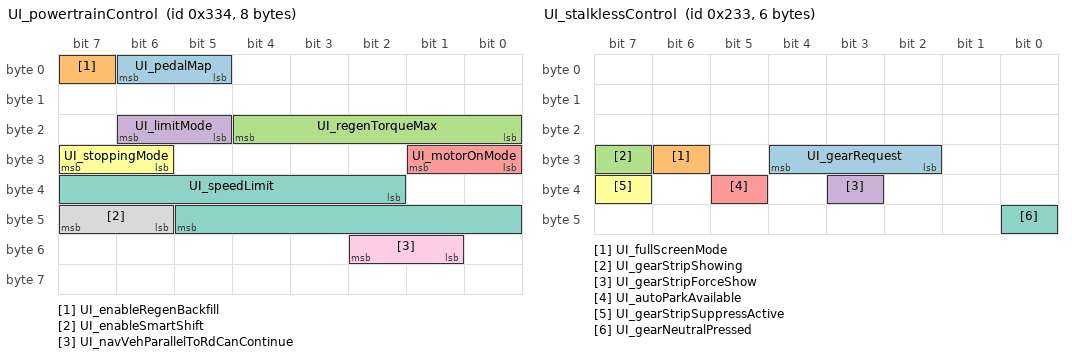
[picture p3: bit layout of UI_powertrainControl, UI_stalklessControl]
BO_ 820 UI_powertrainControl: 8 UI
 SG_ UI_pedalMap : 5|2@1+ (1,0) [0|3] "" Vector__XXX
 SG_ UI_enableRegenBackfill : 7|1@1+ (1,0) [0|1] "" Vector__XXX
 SG_ UI_regenTorqueMax : 16|5@1+ (5,0) [0|100] "%" Vector__XXX
 SG_ UI_limitMode : 21|2@1+ (1,0) [0|3] "" Vector__XXX
 SG_ UI_motorOnMode : 24|2@1+ (1,0) [0|3] "" Vector__XXX
 SG_ UI_stoppingMode : 30|2@1+ (1,0) [0|3] "" Vector__XXX
 SG_ UI_speedLimit : 34|12@1+ (0.1,0) [0|335] "kph" Vector__XXX
 SG_ UI_enableSmartShift : 46|2@1+ (1,0) [0|3] "" Vector__XXX
 SG_ UI_navVehParallelToRdCanContinue : 49|2@1+ (1,0) [1|3] "" Vector__XXX

BO_ 563 UI_stalklessControl: 6 UI
 SG_ UI_gearRequest : 26|3@1+ (1,0) [1|7] "" Vector__XXX
 SG_ UI_fullScreenMode : 30|1@1+ (1,0) [0|1] "" Vector__XXX
 SG_ UI_gearStripShowing : 31|1@1+ (1,0) [0|1] "" Vector__XXX
 SG_ UI_gearStripForceShow : 35|1@1+ (1,0) [0|1] "" Vector__XXX
 SG_ UI_autoParkAvailable : 37|1@1+ (1,0) [0|1] "" Vector__XXX
 SG_ UI_gearStripSuppressActive : 39|1@1+ (1,0) [0|1] "" Vector__XXX
 SG_ UI_gearNeutralPressed : 40|1@1+ (1,0) [0|1] "" Vector__XXX

BO_ 699 UI_stalklessHealthStatus: 2 UI
 SG_ UI_centerDisplayRunning : 0|1@1+ (1,0) [0|1] "" Vector__XXX
 SG_ UI_centerDisplayPowerOn : 4|1@1+ (1,0) [0|1] "" Vector__XXX

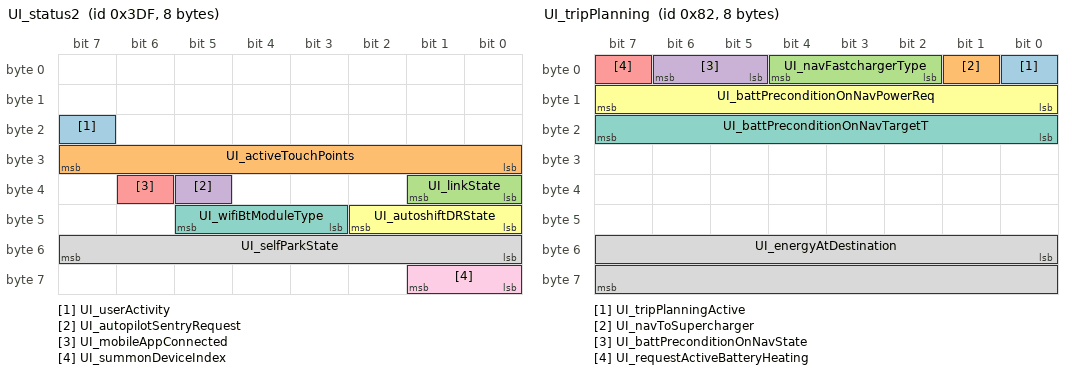
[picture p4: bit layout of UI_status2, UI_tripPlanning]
BO_ 991 UI_status2: 8 UI
 SG_ UI_userActivity : 23|1@1+ (1,0) [0|1] "" Vector__XXX
 SG_ UI_activeTouchPoints : 24|8@1+ (1,0) [0|255] "1" Vector__XXX
 SG_ UI_linkState : 32|2@1+ (1,0) [0|3] "" Vector__XXX
 SG_ UI_autopilotSentryRequest : 37|1@1+ (1,0) [0|1] "" Vector__XXX
 SG_ UI_mobileAppConnected : 38|1@1+ (1,0) [0|1] "" Vector__XXX
 SG_ UI_autoshiftDRState : 40|3@1+ (1,0) [0|7] "" Vector__XXX
 SG_ UI_wifiBtModuleType : 43|3@1+ (1,0) [0|7] "" Vector__XXX
 SG_ UI_selfParkState : 48|8@1+ (1,0) [0|254] "" Vector__XXX
 SG_ UI_summonDeviceIndex : 56|2@1+ (1,0) [0|3] "" Vector__XXX

BO_ 661 UI_systemMonitor: 8 UI
 SG_ UI_systemMonitorIndex M : 0|1@1+ (1,0) [0|1] "" Vector__XXX
 SG_ UI_SystemMemUsage m0 : 8|16@1+ (1,0) [0|65535] "MB" Vector__XXX
 SG_ UI_QtCarMemUsage m0 : 24|16@1+ (1,0) [0|65535] "MB" Vector__XXX
 SG_ UI_QtCarCPUUsage m0 : 40|7@1+ (1,0) [0|127] "%" Vector__XXX
 SG_ UI_SystemCPUUsage m0 : 48|7@1+ (1,0) [0|127] "%" Vector__XXX

BO_ 787 UI_trackModeSettings: 8 UI
 SG_ UI_trackModeRequest : 0|2@1+ (1,0) [0|3] "" Vector__XXX
 SG_ UI_trackDrivePowerAvailability : 27|2@1+ (1,0) [0|3] "" Vector__XXX

BO_ 130 UI_tripPlanning: 8 UI
 SG_ UI_tripPlanningActive : 0|1@1+ (1,0) [0|1] "" Vector__XXX
 SG_ UI_navToSupercharger : 1|1@1+ (1,0) [0|1] "" Vector__XXX
 SG_ UI_navFastchargerType : 2|3@1+ (1,0) [0|7] "" Vector__XXX
 SG_ UI_battPreconditionOnNavState : 5|2@1+ (1,0) [0|3] "" Vector__XXX
 SG_ UI_requestActiveBatteryHeating : 7|1@1+ (1,0) [0|1] "" Vector__XXX
 SG_ UI_battPreconditionOnNavPowerReq : 8|8@1- (125,0) [-16000|15750] "W" Vector__XXX
 SG_ UI_battPreconditionOnNavTargetT : 16|8@1+ (0.25,0) [0|63.5] "degC" Vector__XXX
 SG_ UI_energyAtDestination : 48|16@1- (0.01,0) [-327.67|327.67] "kWh" Vector__XXX

BO_ 139 UI_tripPlanning2: 6 UI
 SG_ UI_maxSpeedToReachDestination : 0|16@1+ (0.01,0) [0|655.34] "m/s" Vector__XXX
 SG_ UI_timeToDestination : 32|16@1+ (1,0) [0|65534] "s" Vector__XXX

BO_ 1173 UI_tripPlanning3: 8 UI
 SG_ UI_predictedEnergy : 0|16@1- (0.01,0) [-327.67|327.67] "kWh" Vector__XXX
 SG_ UI_hindsightEnergy : 32|16@1- (0.01,0) [-327.67|327.67] "kWh" Vector__XXX

BO_ 947 UI_vehicleControl2: 8 UI
 SG_ UI_gloveboxRequest : 0|1@1+ (1,0) [0|1] "" Vector__XXX
 SG_ UI_trunkRequest : 1|1@1+ (1,0) [0|1] "" Vector__XXX
 SG_ UI_PINToDriveEnabled : 6|1@1+ (1,0) [0|1] "" Vector__XXX
 SG_ UI_PINToDrivePassed : 7|1@1+ (1,0) [0|1] "" Vector__XXX
 SG_ UI_disableMirrorAutoDim : 8|1@1+ (1,0) [0|1] "" Vector__XXX
 SG_ UI_lightSwitch : 9|3@1+ (1,0) [0|7] "" Vector__XXX
 SG_ UI_readyToAddKey : 12|1@1+ (1,0) [0|1] "" Vector__XXX
 SG_ UI_alarmTriggerRequest : 13|1@1+ (1,0) [0|1] "" Vector__XXX
 SG_ UI_displayOnForUser : 18|1@1+ (1,0) [0|1] "" Vector__XXX
 SG_ UI_BLEPushNotificationRequest : 20|1@1+ (1,0) [0|1] "" Vector__XXX
 SG_ UI_keepAutopilotAwake : 22|1@1+ (1,0) [0|1] "" Vector__XXX
 SG_ UI_batteryPreconditioningRequest : 23|1@1+ (1,0) [0|1] "" Vector__XXX
 SG_ UI_autopilotPowerStateRequest : 25|2@1+ (1,0) [0|3] "" Vector__XXX
 SG_ UI_autoRollWindowsOnLockEnable : 29|1@1+ (1,0) [0|1] "" Vector__XXX
 SG_ UI_steeringWheelHeatReq : 33|1@1+ (1,0) [0|1] "" Vector__XXX
 SG_ UI_disableHorn : 34|1@1+ (1,0) [0|1] "" Vector__XXX
 SG_ UI_frontLeftSeatFanReq : 37|2@1+ (1,0) [0|3] "" Vector__XXX
 SG_ UI_frontRightSeatAutoClimateReq : 39|1@1+ (1,0) [0|1] "" Vector__XXX
 SG_ UI_frontRightSeatFanReq : 40|2@1+ (1,0) [0|3] "" Vector__XXX
 SG_ UI_frontLeftSeatAutoClimateReq : 56|1@1+ (1,0) [0|1] "" Vector__XXX
 SG_ UI_wiperHeaterReq : 57|1@1+ (1,0) [0|1] "" Vector__XXX
 SG_ UI_silentAlarm : 61|1@1+ (1,0) [0|1] "" Vector__XXX

BO_TX_BU_ 522 : HVP;
BO_TX_BU_ 1962 : HVP;
BO_TX_BU_ 2025 : ICR;
BO_TX_BU_ 670 : ICR;
BO_TX_BU_ 2023 : ICR;
BO_TX_BU_ 828 : IDB;
BO_TX_BU_ 516 : PCS;
BO_TX_BU_ 548 : PCS;
BO_TX_BU_ 708 : PCS;
BO_TX_BU_ 463 : PM;
BO_TX_BU_ 1409 : TCU;
BO_TX_BU_ 1056 : UIS;
BO_TX_BU_ 979 : UI;
BO_TX_BU_ 1657 : UI;
BO_TX_BU_ 1021 : UI;
BO_TX_BU_ 819 : UI;
BO_TX_BU_ 531 : UI;
BO_TX_BU_ 645 : UI;
BO_TX_BU_ 1279 : UI;
BO_TX_BU_ 1139 : UI;
BO_TX_BU_ 820 : UI;
BO_TX_BU_ 563 : UI;
BO_TX_BU_ 699 : UI;
BO_TX_BU_ 991 : UI;
BO_TX_BU_ 661 : UI;
BO_TX_BU_ 787 : UI;
BO_TX_BU_ 130 : UI;
BO_TX_BU_ 139 : UI;
BO_TX_BU_ 1173 : UI;
BO_TX_BU_ 947 : UI;
CM_ BO_ 522 "High-voltage processor (pack contactor and isolation controller) message: contactor state";
CM_ SG_ 522 HVP_packContNegativeState "High-voltage processor (pack contactor and isolation controller): pack cont negative state; raw 0 = signal not available (SNA)";
CM_ SG_ 522 HVP_packContPositiveState "Current state of positive pack contactor; raw 0 = signal not available (SNA)";
CM_ SG_ 522 HVP_fcContPositiveAuxOpen "High-voltage processor (pack contactor and isolation controller): fc cont positive aux open";
CM_ SG_ 522 HVP_fcContNegativeAuxOpen "High-voltage processor (pack contactor and isolation controller): fc cont negative aux open";
CM_ SG_ 522 HVP_packContactorSetState "The current state of the pack contactors; raw 0 = signal not available (SNA)";
CM_ SG_ 522 HVP_fcContNegativeState "Current state of the negative FC contactor; raw 0 = signal not available (SNA)";
CM_ SG_ 522 HVP_fcContPositiveState "Current state of the positive FC contactor; raw 0 = signal not available (SNA)";
CM_ SG_ 522 HVP_fcContactorSetState "The current state of the fast charge contactors; raw 0 = signal not available (SNA)";
CM_ SG_ 522 HVP_fcCtrsRequestStatus "Current status of FC contactor request";
CM_ SG_ 522 HVP_fcCtrsResetRequestRequired "High-voltage processor (pack contactor and isolation controller): fc ctrs reset request required";
CM_ SG_ 522 HVP_fcCtrsOpenNowRequested "Flag indicated immediate-opening request of FC contactors";
CM_ SG_ 522 HVP_fcCtrsOpenRequested "Flag indicating opening request of FC contactors";
CM_ SG_ 522 HVP_fcCtrsClosingAllowed "Flag indicating closure allowance of FC contactors";
CM_ SG_ 522 HVP_packCtrsRequestStatus "Current request status of pack contactors";
CM_ SG_ 522 HVP_packCtrsResetRequestRequired "High-voltage processor (pack contactor and isolation controller): pack ctrs reset request required";
CM_ SG_ 522 HVP_packCtrsOpenNowRequested "Flag indicating immediate-opening request of pack contactors";
CM_ SG_ 522 HVP_packCtrsOpenRequested "Flag indicating opening request of pack contactors";
CM_ SG_ 522 HVP_packCtrsClosingAllowed "Flag indicating closure allowance of pack contactors";
CM_ SG_ 522 HVP_dcLinkAllowedToEnergize "Indicates there should be no HV exposure if the FC link is energized by an internal or external source";
CM_ SG_ 522 HVP_pyroTestInProgress "High-voltage processor (pack contactor and isolation controller): pyro test in progress";
CM_ SG_ 522 HVP_hvilDiag "Diagnostic status of HVIL circuit, including specific FAULT types; raw 14 = signal not available (SNA)";
CM_ SG_ 522 HVP_fcLinkAllowedToEnergize "The type of charge that is allowed to energize the FC link. Indicates that the HVP has disabled the dynamic FC weld check for DC charge, or has enabled the PCS charging hardware for AC charge";
CM_ BO_ 1962 "High-voltage processor (pack contactor and isolation controller) message: debug message";
CM_ SG_ 1962 HVP_debugMessageMultiplexer "High-voltage processor (pack contactor and isolation controller): debug message multiplexer";
CM_ SG_ 1962 HVP_gpioPassivePyroDepl "High-voltage processor (pack contactor and isolation controller): gpio passive pyro depl";
CM_ SG_ 1962 HVP_gpioPyroIsoEn "High-voltage processor (pack contactor and isolation controller): gpio pyro iso en";
CM_ SG_ 1962 HVP_gpioCpFaultIn "High-voltage processor (pack contactor and isolation controller): gpio cp fault in";
CM_ SG_ 1962 HVP_gpioPackContPowerEn "High-voltage processor (pack contactor and isolation controller): gpio pack cont power en";
CM_ SG_ 1962 HVP_gpioHvCablesOk "CPIL fault monitoring signal";
CM_ SG_ 1962 HVP_gpioHvpSelfEnable "High-voltage processor (pack contactor and isolation controller): gpio hvp self enable";
CM_ SG_ 1962 HVP_gpioLed "High-voltage processor (pack contactor and isolation controller): gpio led";
CM_ SG_ 1962 HVP_gpioCrashSignal "Crash signal from RCM";
CM_ SG_ 1962 HVP_gpioShuntDataReady "High-voltage processor (pack contactor and isolation controller): gpio shunt data ready";
CM_ SG_ 1962 HVP_gpioFcContPosAux "Aux contact line from positive FC contactor";
CM_ SG_ 1962 HVP_gpioFcContNegAux "Aux contact line from negative FC contactor";
CM_ SG_ 1962 HVP_gpioBmsEout "High-voltage processor (pack contactor and isolation controller): gpio bms eout";
CM_ SG_ 1962 HVP_gpioCpFaultOut "High-voltage processor (pack contactor and isolation controller): gpio cp fault out";
CM_ SG_ 1962 HVP_gpioPyroPor "High-voltage processor (pack contactor and isolation controller): gpio pyro por";
CM_ SG_ 1962 HVP_gpioShuntEn "High-voltage processor (pack contactor and isolation controller): gpio shunt en";
CM_ SG_ 1962 HVP_gpioHvpVerEn "High-voltage processor (pack contactor and isolation controller): gpio hvp ver en";
CM_ SG_ 1962 HVP_gpioFcContFlywheelEnable "High-voltage processor (pack contactor and isolation controller): gpio fc cont flywheel enable";
CM_ SG_ 1962 HVP_gpioCpLatchEnable "High-voltage processor (pack contactor and isolation controller): gpio cp latch enable";
CM_ SG_ 1962 HVP_gpioFcContPowerEnable "High-voltage processor (pack contactor and isolation controller): gpio fc cont power enable";
CM_ SG_ 1962 HVP_gpioHvilEnable "High-voltage processor (pack contactor and isolation controller): gpio hvil enable";
CM_ SG_ 1962 HVP_gpioPortSelSpiRdy "High-voltage processor (pack contactor and isolation controller): gpio port sel spi rdy";
CM_ SG_ 1962 HVP_gpioPyroUnlock "High-voltage processor (pack contactor and isolation controller): gpio pyro unlock";
CM_ SG_ 1962 HVP_hvp1v5Ref "High-voltage processor (pack contactor and isolation controller): hvp1v5 ref";
CM_ SG_ 1962 HVP_packCurrentMia "High-voltage processor (pack contactor and isolation controller): pack current mia";
CM_ SG_ 1962 HVP_auxCurrentMia "High-voltage processor (pack contactor and isolation controller): aux current mia";
CM_ SG_ 1962 HVP_currentSenseMia "High-voltage processor (pack contactor and isolation controller): current sense mia";
CM_ SG_ 1962 HVP_shuntThermistorMissing "High-voltage processor (pack contactor and isolation controller): shunt thermistor missing";
CM_ SG_ 1962 HVP_shuntThermistorExpected "High-voltage processor (pack contactor and isolation controller): shunt thermistor expected";
CM_ SG_ 1962 HVP_shuntThermistorMia "High-voltage processor (pack contactor and isolation controller): shunt thermistor mia";
CM_ SG_ 1962 HVP_shuntUnexpectedThermistor "High-voltage processor (pack contactor and isolation controller): shunt unexpected thermistor";
CM_ SG_ 1962 HVP_shuntHwMia "High-voltage processor (pack contactor and isolation controller): shunt hw mia";
CM_ SG_ 1962 HVP_shuntCurrentIrrational "High-voltage processor (pack contactor and isolation controller): shunt current irrational";
CM_ SG_ 1962 HVP_shuntAsicTCompActive "High-voltage processor (pack contactor and isolation controller): shunt asic t comp active";
CM_ SG_ 1962 HVP_ecuLogUploadRequest "High-voltage processor (pack contactor and isolation controller): ecu log upload request";
CM_ SG_ 1962 HVP_packContVoltage "High-voltage processor (pack contactor and isolation controller): pack cont voltage";
CM_ SG_ 1962 HVP_packNegativeV "The HVP's common-mode measurement of PACK-HV-SENSE-NEG relative to chassis ground";
CM_ SG_ 1962 HVP_packPositiveV "The HVP's common-mode measurement of PACK-HV-SENSE-POS relative to chassis ground";
CM_ SG_ 1962 HVP_pyroAnalog "High-voltage processor (pack contactor and isolation controller): pyro analog";
CM_ SG_ 1962 HVP_fcContCoilCurrent "High-voltage processor (pack contactor and isolation controller): fc cont coil current";
CM_ SG_ 1962 HVP_fcContVoltage "High-voltage processor (pack contactor and isolation controller): fc cont voltage";
CM_ SG_ 1962 HVP_hvilInVoltage "Measured HVIL input voltage";
CM_ SG_ 1962 HVP_hvilOutVoltage "Measured HVIL output voltage";
CM_ SG_ 1962 HVP_shuntGainInvalidCountDbg "High-voltage processor (pack contactor and isolation controller): shunt gain invalid count dbg";
CM_ SG_ 1962 HVP_fcLinkPositiveV "High-voltage processor (pack contactor and isolation controller): fc link positive v";
CM_ SG_ 1962 HVP_packContCoilCurrent "High-voltage processor (pack contactor and isolation controller): pack cont coil current";
CM_ SG_ 1962 HVP_battery12V "Monitored voltage sense of 12V battery";
CM_ BO_ 2025 "ICR ECU message: occupancy";
CM_ SG_ 2025 ICR_occupancy1LRaw "(Non-Functional Interface) Occupancy detection status of First Row left seat; raw 3 = signal not available (SNA)";
CM_ SG_ 2025 ICR_occupancy1RRaw "(Non-Functional Interface) Occupancy detection status of First Row right seat; raw 3 = signal not available (SNA)";
CM_ SG_ 2025 ICR_occupancy1LVoteCnt "ICR ECU: occupancy1 l vote cnt";
CM_ SG_ 2025 ICR_occupancy1RVoteCnt "ICR ECU: occupancy1 r vote cnt";
CM_ SG_ 2025 ICR_userPresenceFilt "Detection status of User Presence Detection feature; raw 3 = signal not available (SNA)";
CM_ SG_ 2025 ICR_userPresenceRaw "ICR ECU: user presence raw; raw 3 = signal not available (SNA)";
CM_ SG_ 2025 ICR_occupancy1LFilt "(Non-Functional Interface) Occupancy detection status of First Row left seat; raw 3 = signal not available (SNA)";
CM_ SG_ 2025 ICR_occupancy1RFilt "(Non-Functional Interface) Occupancy detection status of First Row right seat; raw 3 = signal not available (SNA)";
CM_ SG_ 2025 ICR_occupancy2LFilt "ICR ECU: occupancy2 l filt; raw 3 = signal not available (SNA)";
CM_ SG_ 2025 ICR_occupancy2CFilt "ICR ECU: occupancy2 c filt; raw 3 = signal not available (SNA)";
CM_ SG_ 2025 ICR_occupancy2RFilt "ICR ECU: occupancy2 r filt; raw 3 = signal not available (SNA)";
CM_ SG_ 2025 ICR_classification1LFilt "ICR ECU: classification1 l filt; raw 0 = signal not available (SNA)";
CM_ SG_ 2025 ICR_classification1RqF "ICR ECU: classification1 rq f";
CM_ SG_ 2025 ICR_occupancy1RFiltExp "ICR ECU: occupancy1 r filt exp; raw 3 = signal not available (SNA)";
CM_ SG_ 2025 ICR_occupancyCounter "ICR ECU: occupancy counter";
CM_ SG_ 2025 ICR_occupancyChecksum "ICR ECU: occupancy checksum";
CM_ BO_ 670 "ICR ECU message: occupancy2";
CM_ SG_ 670 ICR_userPresenceMLOutput "ICR ECU: user presence ML output; raw 255 = signal not available (SNA)";
CM_ SG_ 670 ICR_classification1RFilt "Occupant classification status of First Row Right seat; raw 0 = signal not available (SNA)";
CM_ SG_ 670 ICR_classification1LRaw "ICR ECU: classification1 l raw; raw 0 = signal not available (SNA)";
CM_ SG_ 670 ICR_classification1RRaw "ICR ECU: classification1 r raw; raw 0 = signal not available (SNA)";
CM_ SG_ 670 ICR_classification1LMLOutput "ICR ECU: classification1 LML output; raw 255 = signal not available (SNA)";
CM_ SG_ 670 ICR_classification1RMLOutput "ICR ECU: classification1 RML output; raw 255 = signal not available (SNA)";
CM_ SG_ 670 ICR_occupancy2Counter "ICR ECU: occupancy2 counter";
CM_ SG_ 670 ICR_occupancy2Checksum "ICR ECU: occupancy2 checksum";
CM_ BO_ 2023 "ICR ECU message: status";
CM_ SG_ 2023 ICR_sensorMode "ICR ECU: sensor mode";
CM_ SG_ 2023 ICR_blocked "Indicates if sensor is blocked or not; raw 0 = signal not available (SNA)";
CM_ SG_ 2023 ICR_algoVersion "ICR ECU: algo version";
CM_ SG_ 2023 ICR_l2HeapUsage "ICR ECU: l2 heap usage";
CM_ SG_ 2023 ICR_intrusionStatus "ICR ECU: intrusion status";
CM_ SG_ 2023 ICR_booted "Indicates if ICR has rebooted";
CM_ SG_ 2023 ICR_rdMapDumpCompleted "ICR ECU: rd map dump completed";
CM_ BO_ 828 "IDB ECU message: info";
CM_ SG_ 828 IDB_infoIndex "IDB ECU: info index";
CM_ SG_ 828 IDB_infoPcbaID "IDB ECU: info pcba ID";
CM_ SG_ 828 IDB_infoAssemblyID "IDB ECU: info assembly ID";
CM_ SG_ 828 IDB_infoUsageID "IDB ECU: info usage ID";
CM_ SG_ 828 IDB_infoSubUsageID "IDB ECU: info sub usage ID";
CM_ BO_ 516 "Power conversion system (on-board charger and DC-DC converter) message: chg status";
CM_ SG_ 516 PCS_chgMainState "Power conversion system (on-board charger and DC-DC converter): chg main state";
CM_ SG_ 516 PCS_gridConfig "AC charger sensed grid configuration; raw 0 = signal not available (SNA)";
CM_ SG_ 516 PCS_chgPHAEnable "Indicates whether AC charger phase A is enabled";
CM_ SG_ 516 PCS_chgPHBEnable "Indicates whether AC charger phase B is enabled";
CM_ SG_ 516 PCS_hvInletConductorEnergizedAc "Power conversion system (on-board charger and DC-DC converter): hv inlet conductor energized ac";
CM_ SG_ 516 PCS_chgHighPowerActive "Power conversion system (on-board charger and DC-DC converter): chg high power active";
CM_ SG_ 516 PCS_chgPHCEnable "Indicates whether AC charger phase C is enabled";
CM_ SG_ 516 PCS_chgInstantAcPowerAvailable "Instantaneous power capability of the AC charger";
CM_ SG_ 516 PCS_chgMaxAcPowerAvailable "Maximum power capability of the AC charger; raw 255 = signal not available (SNA)";
CM_ SG_ 516 PCS_chgPHALineCurrentRequest "AC charger phase A input current command";
CM_ SG_ 516 PCS_chgPHBLineCurrentRequest "AC charger phase B input current command";
CM_ SG_ 516 PCS_chgPHCLineCurrentRequest "AC charger phase B input current command";
CM_ SG_ 516 PCS_chgPwmEnableLine "Sensed state of the charger PWM enable hardline";
CM_ SG_ 516 PCS_hwVariantType "Hardware variant of AC charger; raw 3 = signal not available (SNA)";
CM_ BO_ 548 "Power conversion system (on-board charger and DC-DC converter) message: dcdc status";
CM_ SG_ 548 PCS_dcdcPrechargeStatus "Status of DCDC HV bus precharge";
CM_ SG_ 548 PCS_dcdcLvSupportStatus "Status of DCDC LV support";
CM_ SG_ 548 PCS_dcdcHvBusDischargeStatus "Power conversion system (on-board charger and DC-DC converter): dcdc hv bus discharge status";
CM_ SG_ 548 PCS_coldSleepAllowed "Power conversion system (on-board charger and DC-DC converter): cold sleep allowed";
CM_ SG_ 548 PCS_dcdcPchgHVBusLowRDetected "Power conversion system (on-board charger and DC-DC converter): dcdc pchg HV bus low r detected";
CM_ SG_ 548 PCS_dcdcSubState "Substate of DCDC state machine";
CM_ SG_ 548 PCS_dcdcFaulted "Whether the DCDC is in faulted state";
CM_ SG_ 548 PCS_okToBePowerCycled "Power conversion system (on-board charger and DC-DC converter): ok to be power cycled";
CM_ SG_ 548 PCS_dcdcOutputIsLimited "Whether the DCDC's output is current limiting";
CM_ SG_ 548 PCS_dcdcMaxOutputCurrentAllowed "Maximum LV output current capability of DCDC based on operating point";
CM_ SG_ 548 PCS_dcdcPrechargeRtyCnt "Power conversion system (on-board charger and DC-DC converter): dcdc precharge rty cnt";
CM_ SG_ 548 PCS_dcdcLvSupportRtyCnt "Power conversion system (on-board charger and DC-DC converter): dcdc lv support rty cnt";
CM_ SG_ 548 PCS_dcdcDischargeRtyCnt "Power conversion system (on-board charger and DC-DC converter): dcdc discharge rty cnt";
CM_ SG_ 548 PCS_dcdcPwmEnableLine "Sensed state of the DCDC PWM enable hardline";
CM_ SG_ 548 PCS_dcdcSupportingFixedLvTarget "Whether DCDC is running LV support at a fixed voltage target";
CM_ SG_ 548 PCS_ecuLogUploadRequest "Power conversion system (on-board charger and DC-DC converter): ecu log upload request";
CM_ SG_ 548 PCS_dcdcPrechargeRestartCnt "Power conversion system (on-board charger and DC-DC converter): dcdc precharge restart cnt";
CM_ SG_ 548 PCS_dcdcInitialPrechargeSubState "Power conversion system (on-board charger and DC-DC converter): dcdc initial precharge sub state";
CM_ BO_ 708 "Power conversion system (on-board charger and DC-DC converter) message: logging";
CM_ SG_ 708 PCS_logMessageSelect "Power conversion system (on-board charger and DC-DC converter): log message select";
CM_ SG_ 708 PCS_chgPhAInputIrms "AC charger phase A's sensed RMS input current";
CM_ SG_ 708 PCS_chgPhAIntBusV "AC charger phase A's sensed intermediate bus voltage";
CM_ SG_ 708 PCS_chgPhAIntBusVTarget "AC charger phase A's intermediate bus voltage target";
CM_ SG_ 708 PCS_chgPhAOutputI "AC charger phase A sensed output current";
CM_ SG_ 708 PCS_chgPhAInputCurrentLimitReaso "Provides the reason behind the input AC charging current limit for phase A";
CM_ SG_ 708 PCS_chgPhBInputIrms "AC charger phase B's sensed RMS input current";
CM_ SG_ 708 PCS_chgPhBIntBusV "AC charger phase B's sensed intermediate bus voltage";
CM_ SG_ 708 PCS_chgPhBIntBusVTarget "AC charger phase B's intermediate bus voltage target";
CM_ SG_ 708 PCS_chgPhBOutputI "AC charger phase B sensed output current";
CM_ SG_ 708 PCS_chgPhBInputCurrentLimitReaso "Provides the reason behind the input AC charging current limit for phase B";
CM_ SG_ 708 PCS_chgPhCInputIrms "AC charger phase C's sensed RMS input current";
CM_ SG_ 708 PCS_chgPhCIntBusV "AC charger phase C's sensed intermediate bus voltage";
CM_ SG_ 708 PCS_chgPhCIntBusVTarget "AC charger phase C's intermediate bus voltage target";
CM_ SG_ 708 PCS_chgPhCOutputI "AC charger phase C sensed output current";
CM_ SG_ 708 PCS_chgPhCInputCurrentLimitReaso "Provides the reason behind the input AC charging current limit for phase C";
CM_ SG_ 708 PCS_chgInputL1NVrms "AC charger's sensed AC RMS voltage of L1-N voltage source";
CM_ SG_ 708 PCS_chgInputL2NVrms "AC charger's sensed AC RMS voltage of L2-N voltage source";
CM_ SG_ 708 PCS_chgInputL3NVrms "AC charger's sensed AC RMS voltage of L3-N voltage source";
CM_ SG_ 708 PCS_chgInputL1L2Vrms "AC charger's sensed input frequency of L2-N voltage source";
CM_ SG_ 708 PCS_chgInputNGVrms "AC charger's sensed AC RMS voltage of N-G voltage source";
CM_ SG_ 708 PCS_chgInputFrequencyL1N "AC charger's sensed input frequency of L1-N voltage source";
CM_ SG_ 708 PCS_chgInputFrequencyL2N "AC charger's sensed input frequency of L2-N voltage source";
CM_ SG_ 708 PCS_chgInputFrequencyL3N "AC charger's sensed input frequency of L3-N voltage source";
CM_ SG_ 708 PCS_chgInternalPhaseConfig "Internal phase configuration of the AC charger (three phase vs. single phase); raw 0 = signal not available (SNA)";
CM_ SG_ 708 PCS_chgPhasesPriority "AC charger phase manager's priority logic for enabling phases in single phase PCS variant";
CM_ SG_ 708 PCS_chgOutputV "Sensed output voltage of AC charger";
CM_ SG_ 708 PCS_chgPhAState "State of AC charger phase A";
CM_ SG_ 708 PCS_chgPhBState "State of AC charger phase B";
CM_ SG_ 708 PCS_chgPhCState "State of AC charger phase C";
CM_ SG_ 708 PCS_chgPhALastShutdownReason "Last reason for shutting down AC charger phase A";
CM_ SG_ 708 PCS_chgPhBLastShutdownReason "Last reason for shutting down AC charger phase B";
CM_ SG_ 708 PCS_chgPhCLastShutdownReason "Last reason for shutting down AC charger phase C";
CM_ SG_ 708 PCS_chgPhARetryCount "AC charger phase A number of retries used during the current charge session";
CM_ SG_ 708 PCS_chgPhBRetryCount "AC charger phase B number of retries used during the current charge session";
CM_ SG_ 708 PCS_chgPhCRetryCount "AC charger phase C number of retries used during the current charge session";
CM_ SG_ 708 PCS_chgRetryCount "AC charger number of system level retries used during the current charge session";
CM_ SG_ 708 PCS_chgPhManCurrentToDist "Power conversion system (on-board charger and DC-DC converter): chg ph man current to dist";
CM_ SG_ 708 PCS_chgL1NPllLocked "Power conversion system (on-board charger and DC-DC converter): chg L1 n pll locked";
CM_ SG_ 708 PCS_chgL2NPllLocked "Power conversion system (on-board charger and DC-DC converter): chg L2 n pll locked";
CM_ SG_ 708 PCS_chgL3NPllLocked "Power conversion system (on-board charger and DC-DC converter): chg L3 n pll locked";
CM_ SG_ 708 PCS_chgL1L2PllLocked "Power conversion system (on-board charger and DC-DC converter): chg L1 L2 pll locked";
CM_ SG_ 708 PCS_chgNgPllLocked "Power conversion system (on-board charger and DC-DC converter): chg ng pll locked";
CM_ SG_ 708 PCS_chgPhManOptimalPhsToUse "Power conversion system (on-board charger and DC-DC converter): chg ph man optimal phs to use";
CM_ SG_ 708 PCS_chg5VL1Enable "Power conversion system (on-board charger and DC-DC converter): chg5 VL1 enable";
CM_ SG_ 708 PCS_dcdcMaxLvOutputCurrent "Overall maxmum LV output current capability of DCDC";
CM_ SG_ 708 PCS_dcdcCurrentLimit "Power conversion system (on-board charger and DC-DC converter): dcdc current limit";
CM_ SG_ 708 PCS_dcdcLvOutputCurrentTempLimit "Maximum LV output current capability of DCDC based on thermals";
CM_ SG_ 708 PCS_dcdcLvOutputCurrentFiltered "DCDC's filtered LV output current";
CM_ SG_ 708 PCS_dcdcUnifiedCommand "Power conversion system (on-board charger and DC-DC converter): dcdc unified command";
CM_ SG_ 708 PCS_dcdcCLAControllerOutput "Power conversion system (on-board charger and DC-DC converter): dcdc CLA controller output";
CM_ SG_ 708 PCS_dcdcTankVoltage "Power conversion system (on-board charger and DC-DC converter): dcdc tank voltage; raw 1024 = signal not available (SNA)";
CM_ SG_ 708 PCS_dcdcTankVoltageTarget "Power conversion system (on-board charger and DC-DC converter): dcdc tank voltage target";
CM_ SG_ 708 PCS_dcdcClaCurrentFreq "Power conversion system (on-board charger and DC-DC converter): dcdc cla current freq";
CM_ SG_ 708 PCS_dcdcTCommMeasured "Power conversion system (on-board charger and DC-DC converter): dcdc t comm measured";
CM_ SG_ 708 PCS_dcdcShortTimeUs "Power conversion system (on-board charger and DC-DC converter): dcdc short time us";
CM_ SG_ 708 PCS_dcdcHalfPeriodUs "Power conversion system (on-board charger and DC-DC converter): dcdc half period us";
CM_ SG_ 708 PCS_dcdcLvBusVoltTargetWithOffse "LV support Voltage target with Feed-forward offset";
CM_ SG_ 708 PCS_cpu2BootState "Power conversion system (on-board charger and DC-DC converter): cpu2 boot state";
CM_ SG_ 708 PCS_acChargeSelfTestState "Power conversion system (on-board charger and DC-DC converter): ac charge self test state";
CM_ SG_ 708 PCS_1V5Min10s "Power conversion system (on-board charger and DC-DC converter): 1 V5 min10s";
CM_ SG_ 708 PCS_1V5Max10s "Power conversion system (on-board charger and DC-DC converter): 1 V5 max10s";
CM_ SG_ 708 PCS_1V2Min10s "Power conversion system (on-board charger and DC-DC converter): 1 V2 min10s";
CM_ SG_ 708 PCS_1V2Max10s "Power conversion system (on-board charger and DC-DC converter): 1 V2 max10s";
CM_ SG_ 708 PCS_5VNMax10s "Power conversion system (on-board charger and DC-DC converter): 5 VN max10s";
CM_ SG_ 708 PCS_chgPhAIntBusVMin10s "AC charger phase A's minimum sensed intermediate bus voltage over the last ten seconds";
CM_ SG_ 708 PCS_chgPhAIntBusVMax10s "AC charger phase A's maximum sensed intermediate bus voltage over the last ten seconds";
CM_ SG_ 708 PCS_chgPhAPchgVoltDeltaMax10s "AC charger phase A maximum sensed voltage delta between line and intermediate bus in the last 10 seconds during SCR precharge";
CM_ SG_ 708 PCS_chgPhALifetimekWh "Lifetime total energy throughput of AC charger phase A";
CM_ SG_ 708 PCS_chgPhATransientRetryCount "AC charger phase A number of transient retries used during the current charge session";
CM_ SG_ 708 PCS_chgPhBIntBusVMin10s "AC charger phase B's minimum sensed intermediate bus voltage over the last ten seconds";
CM_ SG_ 708 PCS_chgPhBIntBusVMax10s "AC charger phase B's maximum sensed intermediate bus voltage over the last ten seconds";
CM_ SG_ 708 PCS_chgPhBPchgVoltDeltaMax10s "AC charger phase B maximum sensed voltage delta between line and intermediate bus in the last 10 seconds during SCR precharge";
CM_ SG_ 708 PCS_chgPhBLifetimekWh "Lifetime total energy throughput of AC charger phase B";
CM_ SG_ 708 PCS_chgPhBTransientRetryCount "AC charger phase B number of transient retries used during the current charge session";
CM_ SG_ 708 PCS_chgPhCIntBusVMin10s "AC charger phase C's minimum sensed intermediate bus voltage over the last ten seconds";
CM_ SG_ 708 PCS_chgPhCIntBusVMax10s "AC charger phase C's maximum sensed intermediate bus voltage over the last ten seconds";
CM_ SG_ 708 PCS_chgPhCPchgVoltDeltaMax10s "AC charger phase C maximum sensed voltage delta between line and intermediate bus in the last 10 seconds during SCR precharge";
CM_ SG_ 708 PCS_chgPhCLifetimekWh "Lifetime total energy throughput of AC charger phase C";
CM_ SG_ 708 PCS_chgPhCTransientRetryCount "AC charger phase C number of transient retries used during the current charge session";
CM_ SG_ 708 PCS_chgPhANoFlowBucket "Power conversion system (on-board charger and DC-DC converter): chg ph a no flow bucket";
CM_ SG_ 708 PCS_chgPhBNoFlowBucket "Power conversion system (on-board charger and DC-DC converter): chg ph b no flow bucket";
CM_ SG_ 708 PCS_chgPhCNoFlowBucket "Power conversion system (on-board charger and DC-DC converter): chg ph c no flow bucket";
CM_ SG_ 708 PCS_chgCurrentSensorOutOfBandUs "Power conversion system (on-board charger and DC-DC converter): chg current sensor out of band us";
CM_ SG_ 708 PCS_chgAcpwHeartbeatState "A signal to indicate if PCS detects the heartbeat signature from AC Power Wall";
CM_ SG_ 708 PCS_chgKwhLostByFreqDroop "Power conversion system (on-board charger and DC-DC converter): chg kwh lost by freq droop";
CM_ SG_ 708 PCS_chgReqKwhLostByFreqDroop "Power conversion system (on-board charger and DC-DC converter): chg req kwh lost by freq droop";
CM_ SG_ 708 PCS_dcdcLvSupportLifetimekWh "Lifetime energy throughput of DCDC LV support mode";
CM_ SG_ 708 PCS_chgPwmEnableLineErrorCount "Power conversion system (on-board charger and DC-DC converter): chg pwm enable line error count";
CM_ SG_ 708 PCS_dcdcPwmEnableLineErrorCount "Number of deassertions detected for DCDC PWM enable line";
CM_ SG_ 708 PCS_numAlertsSet "Power conversion system (on-board charger and DC-DC converter): num alerts set";
CM_ SG_ 708 PCS_dcdcPchgStartLvBusVolt "Sensed LV bus votlage when beginning DCDC precharge";
CM_ SG_ 708 PCS_dcdcPchgStartHvBusVolt "Sensed HV bus votlage when beginning DCDC precharge";
CM_ SG_ 708 PCS_processorDieIdLot "Power conversion system (on-board charger and DC-DC converter): processor die id lot";
CM_ SG_ 708 PCS_processorDieIdWafer "Power conversion system (on-board charger and DC-DC converter): processor die id wafer";
CM_ SG_ 708 PCS_processorDieIdX "Power conversion system (on-board charger and DC-DC converter): processor die id x";
CM_ SG_ 708 PCS_processorDieIdY "Power conversion system (on-board charger and DC-DC converter): processor die id y";
CM_ BO_ 463 "PM ECU message: system state";
CM_ SG_ 463 PM_hvilSystemStatus "HVIL system status; raw 3 = signal not available (SNA)";
CM_ BO_ 1409 "TCU ECU message: log";
CM_ SG_ 1409 TCU_logMux "TCU ECU: log mux";
CM_ SG_ 1409 TCU_cpuTemp "Indicates the current temperature reported by the Central Processing Unit (CPU) in the modem application processor";
CM_ SG_ 1409 TCU_cpuUsage "Indicates the current CPU usage in percentage reported by the modem application processor";
CM_ SG_ 1409 TCU_mdmCoreTemperature "Indicates the current Communication Processor (CP) temperature reported by the modem CP.";
CM_ SG_ 1409 TCU_availableMemory "Indicates the currently available Random Access Memory in the modem application processor";
CM_ SG_ 1409 TCU_pwm "Indicates the active Pulse Width Modulation (PWM) duty cycle applied to the modem fan.";
CM_ SG_ 1409 TCU_pwmcap "Indicates the active Pulse Width Modulation (PWM) duty cycle restriciton applied to the modem fan.";
CM_ SG_ 1409 TCU_totalResumes "Indicates the total amount of times the modem has been resumed";
CM_ SG_ 1409 TCU_mdmUplinkQueueSize "TCU ECU: mdm uplink queue size";
CM_ SG_ 1409 TCU_mdmRSRP "TCU ECU: mdm RSRP";
CM_ SG_ 1409 TCU_mdmSINR "TCU ECU: mdm SINR";
CM_ SG_ 1409 TCU_mdmUplinkAllowedRate "TCU ECU: mdm uplink allowed rate";
CM_ SG_ 1409 TCU_mdmServiceState "TCU ECU: mdm service state";
CM_ SG_ 1409 TCU_mdmIMSStatus "Indicates the current IP Multimedia System (IMS) registration state.";
CM_ SG_ 1409 TCU_mdmSIMStatus "TCU ECU: mdm SIM status";
CM_ SG_ 1409 TCU_mdmBusyActive "Reports whether the modem busy service is active on the modem application processor; raw 4294967295 = signal not available (SNA)";
CM_ BO_ 1056 "UIS ECU message: log";
CM_ SG_ 1056 UIS_logMux "UIS ECU: log mux";
CM_ SG_ 1056 UIS_wifiTemperature "Current temperature reported for wifi";
CM_ SG_ 1056 UIS_wifiStackState "WiFi stack state description";
CM_ SG_ 1056 UIS_wifiBars "WiFi bars for connected network";
CM_ SG_ 1056 UIS_wifiAutoJoinLowRSSI "Indicates an attempt to auto-join a known network with low Received Signal Strength Indicator (RSSI).";
CM_ SG_ 1056 UIS_valetMode "UI Valet Mode state";
CM_ SG_ 1056 UIS_uiQtCarUptime "Touchscreen UI software uptime";
CM_ SG_ 1056 UIS_uiMeanFPS "UI mean frames per second over a 60s period";
CM_ SG_ 1056 UIS_tunerVoltageOperation "Radio tuner operating voltage (mV)";
CM_ SG_ 1056 UIS_tunerVoltageAntenna2 "Radio tuner voltage (mV) for antenna 2";
CM_ SG_ 1056 UIS_tunerVoltageAntenna1 "Radio tuner voltage (mV) for antenna 1";
CM_ SG_ 1056 UIS_tunerCurrentAntenna2 "Radio tuner current (mA) for antenna 2";
CM_ SG_ 1056 UIS_tunerCurrentAntenna1 "Radio tuner current (mA) for antenna 1";
CM_ SG_ 1056 UIS_tegraModemManState "Tegra Cellular Modem Manager state";
CM_ SG_ 1056 UIS_systemWakeTime "Length of time since wake or boot if UI has not slept (seconds)";
CM_ SG_ 1056 UIS_systemUptime "Reports the system uptime duration.";
CM_ SG_ 1056 UIS_suspensionGeofence "Status of suspension geofence add or remove";
CM_ SG_ 1056 UIS_superchargePaymentNeeded "Reports that Supercharging payment is needed.";
CM_ SG_ 1056 UIS_sleepType "Reports the system sleep type.";
CM_ SG_ 1056 UIS_sleepTime "Reports the system sleep duration.";
CM_ SG_ 1056 UIS_sleepState "Reports the system sleep state.";
CM_ SG_ 1056 UIS_slackerLoginResult "Reports Slacker Media login events";
CM_ SG_ 1056 UIS_sentryState "Sentry Mode state";
CM_ SG_ 1056 UIS_sentryNeedsNap "Sentry Mode sleep indicator, max uptime reached";
CM_ SG_ 1056 UIS_sentryIncidentCount "Sentry Mode incident count, initializes to 0";
CM_ SG_ 1056 UIS_scheduledChargingMode "Scheduled charging mode";
CM_ SG_ 1056 UIS_scheduleChargeStartTime "Reports the scheduled charging start date time in MMDDHHMM format.";
CM_ SG_ 1056 UIS_scheduleChargeEndTime "Reports the scheduled charging end date time in MMDDHHMM format.";
CM_ SG_ 1056 UIS_remoteRequestType "Reports the signed remote request type sent to vehicle, excluding closures and start requests.";
CM_ SG_ 1056 UIS_rearDisplayUserPresent "Indicates if a user is present in the rear seat based on seat occupancy and rear display usage";
CM_ SG_ 1056 UIS_rearDisplayState "Reports the rear display state.";
CM_ SG_ 1056 UIS_powerManagerState "UI power manager state signal; raw 18 = signal not available (SNA)";
CM_ SG_ 1056 UIS_polytopiax8664MemUsage "polytopiax8664's Resident Memory usage in MB";
CM_ SG_ 1056 UIS_polytopiax8664CPUUsage "polytopiax8664's CPU usage in CPU usage %";
CM_ SG_ 1056 UIS_navAudioVolume "Navigation audio volume level";
CM_ SG_ 1056 UIS_muteNavVolume "Mute state of the navigation audio";
CM_ SG_ 1056 UIS_modemECallppAvail "Reports whether eCall++ is enabled and is running on Telematics Control Unit (TCU).";
CM_ SG_ 1056 UIS_modemBusyActive "Reports whether the modem busy logic is requested to be active on the modem application processor.";
CM_ SG_ 1056 UIS_mirrorGeofenceActive "Folding mirror geofence active status";
CM_ SG_ 1056 UIS_mediaPlaybackStatus "Media Current Playback Status";
CM_ SG_ 1056 UIS_mediaNeedAuthToken "Indicates whether the media system needs a new authentication token.";
CM_ SG_ 1056 UIS_inSuperchargerGeofence "Vehicle inside Supercharger Geofence";
CM_ SG_ 1056 UIS_homelinkState "State of Homelink sate machine";
CM_ SG_ 1056 UIS_headsetPairResult "Bluetooth headset pairing result";
CM_ SG_ 1056 UIS_headsetConnectionState "Bluetooth headset connection state";
CM_ SG_ 1056 UIS_gpsmanagerMemUsage "gpsManager's Resident Memory usage in MB";
CM_ SG_ 1056 UIS_gpsmanagerCPUUsage "gpsManager's CPU usage in CPU usage %";
CM_ SG_ 1056 UIS_featureSuperchargingEnabled "Reports the Supercharging enabled feature status.";
CM_ SG_ 1056 UIS_dmRearTouchDeviceExists "Reports status of rear display power state.";
CM_ SG_ 1056 UIS_dmRearPowerState "Logs rear display power state status";
CM_ SG_ 1056 UIS_dmRearLinkCheckOk "Logs whether rear display-hardware-init was successful";
CM_ SG_ 1056 UIS_dmRearEnabled "Rear display is enabled";
CM_ SG_ 1056 UIS_dmRearConnected "Rear display is connected";
CM_ SG_ 1056 UIS_dmRearBacklightDutyCycle "Logs rear backlight duty cycle status";
CM_ SG_ 1056 UIS_dmRearBacklightDevExists "Logs whether rear backlight device exists and was successfully detected";
CM_ SG_ 1056 UIS_dmIcuPowerState "Logs cluster display power state status";
CM_ SG_ 1056 UIS_dmIcuLinkCheckOk "Logs whether cluster display-hardware-init was successful";
CM_ SG_ 1056 UIS_dmIcuEnabled "Cluster display is enabled";
CM_ SG_ 1056 UIS_dmIcuConnected "Cluster display is connected";
CM_ SG_ 1056 UIS_dmIcuBacklightDutyCycle "Logs cluster backlight duty cycle status";
CM_ SG_ 1056 UIS_dmIcuBacklightDevExists "Logs whether cluster backlight device exists and was successfully detected";
CM_ SG_ 1056 UIS_dmGatewayLinkWedged "Indicates whether the center display gateway link is stuck.";
CM_ SG_ 1056 UIS_dmCenterTouchDeviceExists "Detects whether the center display touch input device is present.";
CM_ SG_ 1056 UIS_dmCenterPowerState "Logs center display power state status";
CM_ SG_ 1056 UIS_dmCenterOsdDisplayedState "Reports the center display On-Screen Display (OSD) shown state.";
CM_ SG_ 1056 UIS_dmCenterLinkCheckOk "Logs whether center display-hardware-init was successful";
CM_ SG_ 1056 UIS_dmCenterEnabled "Center display is enabled";
CM_ SG_ 1056 UIS_dmCenterConnected "Center display is connected";
CM_ SG_ 1056 UIS_dmCenterBacklightPowerLevel "Logs backlight power level for center display";
CM_ SG_ 1056 UIS_dmCenterBacklightDutyCycle "Logs center backlight duty cycle status";
CM_ SG_ 1056 UIS_dmCenterBacklightDevExists "Logs whether center backlight device exists and was successfully detected";
CM_ SG_ 1056 UIS_dgpuTemperature "Current temperature reported for dgpu";
CM_ SG_ 1056 UIS_dashcamviewerMemUsage "dashcamViewer's Resident Memory usage in MB";
CM_ SG_ 1056 UIS_dashcamviewerCPUUsage "dashcamViewer's CPU usage in CPU usage %";
CM_ SG_ 1056 UIS_dashcamStorageState "Internal state of the dashcam storage";
CM_ SG_ 1056 UIS_dashcamStorageSentryMB "Dashcam USB storage used by Sentry Clips in MB";
CM_ SG_ 1056 UIS_dashcamStorageSavedMB "Dashcam USB storage used by Saved Clips in MB";
CM_ SG_ 1056 UIS_dashcamStorageRecentMB "Dashcam USB storage used by Recent Clips in MB";
CM_ SG_ 1056 UIS_dashcamStorageAvailableMB "Dashcam USB storage that is Available in MB";
CM_ SG_ 1056 UIS_dashcamState "Internal state for the dashcam state machine";
CM_ SG_ 1056 UIS_cpuTemperature "Current temperature reported for cpu";
CM_ SG_ 1056 UIS_clusterMemUsage "cluster's Resident Memory usage in MB";
CM_ SG_ 1056 UIS_clusterDisplayState "Reports the instrument cluster display state.";
CM_ SG_ 1056 UIS_clusterCPUUsage "cluster's CPU usage in CPU usage %";
CM_ SG_ 1056 UIS_chargeOnSolarNoChargeReason "Reason car is not charging on solar";
CM_ SG_ 1056 UIS_centerDisplayState "Reports the center display state.";
CM_ SG_ 1056 UIS_centerDisplayEvent "Reports the events that cause center display state transitions.";
CM_ SG_ 1056 UIS_cellularLinkManagerState "CellLink Manager state";
CM_ SG_ 1056 UIS_carAssistState "Car Assist State";
CM_ SG_ 1056 UIS_carAssistSessionCount "Car Assist Session Count";
CM_ SG_ 1056 UIS_carAssistErrorCode "Car Assist Error Code";
CM_ SG_ 1056 UIS_cameraRRepeaterStreamMissing "Signal representing if left repeater camera stream is active within videod";
CM_ SG_ 1056 UIS_cameraRRepeaterPopup "Right repeater camera popup state";
CM_ SG_ 1056 UIS_cameraRRepeaterPipeline "Right repeater videod pipeline state";
CM_ SG_ 1056 UIS_cameraLRepeaterStreamMissing "Signal representing if left repeater camera stream is active within videod";
CM_ SG_ 1056 UIS_cameraLRepeaterPopup "Left repeater camera popup state";
CM_ SG_ 1056 UIS_cameraLRepeaterPipeline "Left repeater videod pipeline state";
CM_ SG_ 1056 UIS_cameraBackupStreamMissing "Signal representing if backup camera stream is active within videod";
CM_ SG_ 1056 UIS_cameraBackupPopup "Reports the backup camera popup state.";
CM_ SG_ 1056 UIS_cameraBackupPipeline "Reports the backup camera video pipeline state.";
CM_ SG_ 1056 UIS_cameraBackupFramerate "Reports the backup camera framerate.";
CM_ SG_ 1056 UIS_boardTemperature "Current temperature reported for board";
CM_ SG_ 1056 UIS_bluetoothStackState "Bluetooth stack state";
CM_ SG_ 1056 UIS_bluetoothStackRearState "Bluetooth rear stack state";
CM_ SG_ 1056 UIS_bluetoothPairResult "Bluetooth pairing result";
CM_ SG_ 1056 UIS_bluetoothMemUsage "Reports the Bluetooth process resident memory usage in megabytes.";
CM_ SG_ 1056 UIS_bluetoothConnectionState "Reports the Bluetooth connection state.";
CM_ SG_ 1056 UIS_bluetoothCPUUsage "Reports the Bluetooth process Central Processing Unit (CPU) usage percentage.";
CM_ SG_ 1056 UIS_bluetoothAutoConnectionState "Reports the Bluetooth auto-connection state.";
CM_ SG_ 1056 UIS_backlightUserRequest "Reports the Graphical User Interface (GUI) backlight user request value.";
CM_ SG_ 1056 UIS_audioVolumeLevel "User facing volume level";
CM_ SG_ 1056 UIS_audioType "Shows which audio amplifier type is currently configured";
CM_ SG_ 1056 UIS_audioState "Shows the state of the audio system";
CM_ SG_ 1056 UIS_audioSource "Shows which internal audio source is currently active";
CM_ SG_ 1056 UIS_audioPWSGain "Reports the pedestrian warning system volume in decibels.";
CM_ SG_ 1056 UIS_audioMediaPlaying "Shows which media source is currently being played";
CM_ SG_ 1056 UIS_audioMediaBrowsing "Shows which media source is currently being viewed";
CM_ SG_ 1056 UIS_audioA2BRediscoveryCount "Shows the count of a2b rediscoveries that have occurred";
CM_ SG_ 1056 UIS_activeAppView "Shows the currently displayed app";
CM_ BO_ 979 "Touchscreen user interface computer message: airbag cutoff status";
CM_ SG_ 979 UI_airbagCutoffSwState "Reports the front passenger airbag cutoff switch request; raw 2 = signal not available (SNA)";
CM_ BO_ 1657 "Touchscreen user interface computer message: ambient lighting ctrls";
CM_ SG_ 1657 UI_rgbEnableState "Request to enable RGB lights";
CM_ SG_ 1657 UI_rgbEffectType "Reports the RGB light effect type.";
CM_ SG_ 1657 UI_rgbBrightnessLevel "Reports the requested RGB brightness level; raw 127 = signal not available (SNA)";
CM_ SG_ 1657 UI_rgbTargetDOORFL "Target RGB control for front left door";
CM_ SG_ 1657 UI_rgbTargetDOORFR "Target RGB control for the front right door";
CM_ SG_ 1657 UI_rgbTargetDOORRL "Target RGB control for rear left door";
CM_ SG_ 1657 UI_rgbTargetDOORRR "Target RGB control for the rear right door";
CM_ SG_ 1657 UI_rgbTargetIPFL "Reports control for RGB lighting for the front left instrument panel.";
CM_ SG_ 1657 UI_rgbTargetIPFR "Reports control for RGB lighting for the front right instrument panel.";
CM_ BO_ 1021 "Touchscreen user interface computer message: autopilot control";
CM_ SG_ 1021 UI_autopilotControlIndex "Touchscreen user interface computer: autopilot control index";
CM_ SG_ 1021 UI_hovEnabled "UI HOV routes enabled";
CM_ SG_ 1021 UI_smartSetSpeedOffset "TACC will apply this offset over the speed limit";
CM_ SG_ 1021 UI_smartSetSpeedOffsetType "Offset applied will be a percentage or fixed value based on this setting";
CM_ SG_ 1021 UI_fsdStopsControlEnabled "Indicates if autopilot control for traffic lights and stops signs has been enabled by the driver";
CM_ SG_ 1021 UI_smartSetSpeed "TACC will use speed limit + offset as user set speed when enabled";
CM_ SG_ 1021 UI_automaticSetSpeedOffset "Maximum set speed offset would be determined automatically when this option is enabled";
CM_ SG_ 1021 UI_enableFullSelfDriving "Indicates if the driver has enabled FSD behaviors";
CM_ SG_ 1021 UI_hasFullSelfDriving "Indicates if the vehicle hardware, software, and dependencies allow FSD";
CM_ SG_ 1021 UI_autosteerActivation "User-selected autosteer activation method";
CM_ SG_ 1021 UI_autopilotDrivingProfile "Driving profile for autopilot control";
CM_ SG_ 1021 UI_fsdBetaRequest "User accepted disclaimer and requested FSD (Supervised) builds";
CM_ SG_ 1021 UI_fullSelfDrivingSuspended "Full self driving is suspended";
CM_ SG_ 1021 UI_disableOptionalLaneChanges "Disable optional lane changes while FSD is controlling";
CM_ SG_ 1021 UI_selectableCameraRequest "Infotainment selectable camera state request from AP signal; raw 15 = signal not available (SNA)";
CM_ SG_ 1021 UI_driverMonitorConfirmation "Driver attentiveness confirmation";
CM_ SG_ 1021 UI_parkAssistUseVision "Reports if the vehicle should use vision park assist.";
CM_ SG_ 1021 UI_noStalkConfirmAlertHaptic "Detects if alert haptic feedback should trigger.";
CM_ SG_ 1021 UI_noStalkConfirmAlertChime "Detects if alert chime should trigger.";
CM_ SG_ 1021 UI_factorySummonEnable "Controls Factory Summon.";
CM_ SG_ 1021 UI_enableCabinCamera "Indicates if autopilot can enable cabin camera";
CM_ SG_ 1021 UI_enableAutopilotStopWarning "Enables the Autopilot active red light warning function.";
CM_ SG_ 1021 UI_enableVisionSpeedControl "Indicates if autopilot can enable vision speed control";
CM_ SG_ 1021 UI_enableTeslaAutopark "Indicates if autopilot can enable Telsa Autopark control";
CM_ SG_ 1021 UI_autoTurnSignalMode "Turn signal activation mode";
CM_ SG_ 1021 UI_enableCabinAudioRecording "Indicates if autopilot can record cabin audio";
CM_ BO_ 819 "Touchscreen user interface computer message: charge request";
CM_ SG_ 819 UI_openChargePortDoorRequest "Request to open charge port.";
CM_ SG_ 819 UI_closeChargePortDoorRequest "Request to close charge port.";
CM_ SG_ 819 UI_chargeEnableRequest "Charging request initiated";
CM_ SG_ 819 UI_acChargeCurrentLimit "UI charging line current request; raw 127 = signal not available (SNA)";
CM_ SG_ 819 UI_dSocAlertEnable "Set when the BMS_a117_SW_Delta_SOC_Weak_Short alert for the BMS should have a functional response";
CM_ SG_ 819 UI_chargeTerminationPct "Charge Termination Limit Percent";
CM_ SG_ 819 UI_scheduledDepartureEnabled "Reports scheduled departure feature enablement.";
CM_ SG_ 819 UI_chargePortLatchRequest "Request to engage or disengage the latch.";
CM_ SG_ 819 UI_cpInletHeaterRequest "Enable charge port inlet heater";
CM_ BO_ 531 "Touchscreen user interface computer message: cruise control";
CM_ SG_ 531 UI_cruiseSpeedCommand "User command to change the cruise set speed.";
CM_ BO_ 645 "Touchscreen user interface computer message: driver profile recall";
CM_ SG_ 645 UI_driverProfileRecallIndex "Touchscreen user interface computer: driver profile recall index; raw 0 = signal not available (SNA)";
CM_ SG_ 645 UI_driverProfileRecallStop "notifies controller to stop profile recall action";
CM_ SG_ 645 UI_frontSeatRecallActive "signals when driver seat presets are being recalled";
CM_ SG_ 645 UI_leftMirrorTiltXPosition "signal from ui to command mirror X tilt position";
CM_ SG_ 645 UI_leftMirrorTiltYPosition "signal from ui to command mirror Y tilt position";
CM_ SG_ 645 UI_customMirrorDipPositionsSet "Reports whether custom mirror dip positions are set.";
CM_ SG_ 645 UI_leftMirrorDipXPosition "signal from ui to command left mirror X dip position";
CM_ SG_ 645 UI_leftMirrorDipYPosition "signal from ui to command mirror Y dip position";
CM_ SG_ 645 UI_modifyMirrorDipRequest "Reports that a user is trying to modify the mirrors in the dipped position.";
CM_ BO_ 1279 "Touchscreen user interface computer message: energy consumption info";
CM_ SG_ 1279 UI_energyConsumptionInfoIndex "Touchscreen user interface computer: energy consumption info index";
CM_ SG_ 1279 UI_energyLossTotal_epa "Energy amount for a given bucket for an energy consumption baseline (raw/real energy consumed)";
CM_ SG_ 1279 UI_energyLossDriving_epa "Energy amount for a given bucket for an energy consumption baseline (raw/real energy consumed)";
CM_ SG_ 1279 UI_energyLossClimate_epa "Energy amount for a given bucket for an energy consumption baseline (raw/real energy consumed)";
CM_ SG_ 1279 UI_energyLossBattCond_epa "Energy amount for a given bucket for an energy consumption baseline (raw/real energy consumed)";
CM_ SG_ 1279 UI_energyLossElevation_epa "Energy amount for a given bucket for an energy consumption baseline (raw/real energy consumed)";
CM_ SG_ 1279 UI_energyLossAcc_epa "Energy amount for a given bucket for an energy consumption baseline (raw/real energy consumed)";
CM_ SG_ 1279 UI_energyLossTotalSinceCharge_ep "Energy amount for a given bucket for an energy consumption baseline (raw/real energy consumed)";
CM_ SG_ 1279 UI_energyLossDrivingSinceCharge_ "Energy amount for a given bucket for an energy consumption baseline (raw/real energy consumed)";
CM_ SG_ 1279 UI_energyLossClimateSinceCharge_ "Energy amount for a given bucket for an energy consumption baseline (raw/real energy consumed)";
CM_ SG_ 1279 UI_energyLossBattCondSinceCharge "Energy amount for a given bucket for an energy consumption baseline (raw/real energy consumed)";
CM_ SG_ 1279 UI_energyLossElevationSinceCharg "Energy amount for a given bucket for an energy consumption baseline (raw/real energy consumed)";
CM_ SG_ 1279 UI_energyLossAccSinceCharge_epa "Energy amount for a given bucket for an energy consumption baseline (raw/real energy consumed)";
CM_ SG_ 1279 UI_energyLossTotalSinceTripStart "Energy amount for a given bucket for an energy consumption baseline (raw/real energy consumed)";
CM_ SG_ 1279 UI_energyLossDrivingSinceTripSta "Energy amount for a given bucket for an energy consumption baseline (raw/real energy consumed)";
CM_ SG_ 1279 UI_energyLossClimateSinceTripSta "Energy amount for a given bucket for an energy consumption baseline (raw/real energy consumed)";
CM_ SG_ 1279 UI_energyLossBattCondSinceTripSt "Energy amount for a given bucket for an energy consumption baseline (raw/real energy consumed)";
CM_ SG_ 1279 UI_energyLossElevationSinceTripS "Energy amount for a given bucket for an energy consumption baseline (raw/real energy consumed)";
CM_ SG_ 1279 UI_energyLossAccSinceTripStart "Energy amount for a given bucket for an energy consumption baseline (raw/real energy consumed)";
CM_ SG_ 1279 UI_energyDeltaTotal_epa "Energy amount for a given bucket for an energy consumption baseline (raw/real energy consumed)";
CM_ SG_ 1279 UI_energyDeltaDriving_epa "Energy amount for a given bucket for an energy consumption baseline (raw/real energy consumed)";
CM_ SG_ 1279 UI_energyDeltaClimate_epa "Energy amount for a given bucket for an energy consumption baseline (raw/real energy consumed)";
CM_ SG_ 1279 UI_energyDeltaBattCond_epa "Energy amount for a given bucket for an energy consumption baseline (raw/real energy consumed)";
CM_ SG_ 1279 UI_energyDeltaElevation_epa "Energy amount for a given bucket for an energy consumption baseline (raw/real energy consumed)";
CM_ SG_ 1279 UI_energyDeltaAcc_epa "Energy amount for a given bucket for an energy consumption baseline (raw/real energy consumed)";
CM_ SG_ 1279 UI_uiDeltaOffsetTotal_epa "Energy amount for a given bucket for an energy consumption baseline (raw/real energy consumed)";
CM_ SG_ 1279 UI_uiDeltaOffsetDriving_epa "Energy amount for a given bucket for an energy consumption baseline (raw/real energy consumed)";
CM_ SG_ 1279 UI_uiDeltaOffsetClimate_epa "Energy amount for a given bucket for an energy consumption baseline (raw/real energy consumed)";
CM_ SG_ 1279 UI_uiDeltaOffsetBattCond_epa "Energy amount for a given bucket for an energy consumption baseline (raw/real energy consumed)";
CM_ SG_ 1279 UI_uiDeltaOffsetElevation_epa "Energy amount for a given bucket for an energy consumption baseline (raw/real energy consumed)";
CM_ SG_ 1279 UI_uiDeltaOffsetAcc_epa "Energy amount for a given bucket for an energy consumption baseline (raw/real energy consumed)";
CM_ SG_ 1279 UI_rawToUiEnergyRatio_epa "Ratio used for conversion between UI and raw energy domains";
CM_ SG_ 1279 UI_driveDistance_epa "Distance driven for an energy consumption baseline";
CM_ SG_ 1279 UI_energyDeltaTotalSinceCharge_e "Energy amount for a given bucket for an energy consumption baseline (raw/real energy consumed)";
CM_ SG_ 1279 UI_energyDeltaDrivingSinceCharge "Energy amount for a given bucket for an energy consumption baseline (raw/real energy consumed)";
CM_ SG_ 1279 UI_energyDeltaClimateSinceCharge "Energy amount for a given bucket for an energy consumption baseline (raw/real energy consumed)";
CM_ SG_ 1279 UI_energyDeltaBattCondSinceCharg "Energy amount for a given bucket for an energy consumption baseline (raw/real energy consumed)";
CM_ SG_ 1279 UI_energyDeltaElevationSinceChar "Energy amount for a given bucket for an energy consumption baseline (raw/real energy consumed)";
CM_ SG_ 1279 UI_energyDeltaAccSinceCharge_epa "Energy amount for a given bucket for an energy consumption baseline (raw/real energy consumed)";
CM_ SG_ 1279 UI_uiDeltaOffsetTotalSinceCharge "Energy amount for a given bucket for an energy consumption baseline (raw/real energy consumed)";
CM_ SG_ 1279 UI_uiDeltaOffsetDrivingSinceChar "Energy amount for a given bucket for an energy consumption baseline (raw/real energy consumed)";
CM_ SG_ 1279 UI_uiDeltaOffsetClimateSinceChar "Energy amount for a given bucket for an energy consumption baseline (raw/real energy consumed)";
CM_ SG_ 1279 UI_uiDeltaOffsetBattCondSinceCha "Energy amount for a given bucket for an energy consumption baseline (raw/real energy consumed)";
CM_ SG_ 1279 UI_uiDeltaOffsetElevationSinceCh "Energy amount for a given bucket for an energy consumption baseline (raw/real energy consumed)";
CM_ SG_ 1279 UI_uiDeltaOffsetAccSinceCharge_e "Energy amount for a given bucket for an energy consumption baseline (raw/real energy consumed)";
CM_ SG_ 1279 UI_rawToUiEnergyRatioSinceCharge "Ratio used for conversion between UI and raw energy domains";
CM_ SG_ 1279 UI_driveDistanceSinceCharge_epa "Distance driven for an energy consumption baseline";
CM_ SG_ 1279 UI_energyDeltaTotalSinceTripStar "Energy amount for a given bucket for an energy consumption baseline (raw/real energy consumed)";
CM_ SG_ 1279 UI_energyDeltaDrivingSinceTripSt "Energy amount for a given bucket for an energy consumption baseline (raw/real energy consumed)";
CM_ SG_ 1279 UI_energyDeltaClimateSinceTripSt "Energy amount for a given bucket for an energy consumption baseline (raw/real energy consumed)";
CM_ SG_ 1279 UI_energyDeltaBattCondSinceTripS "Energy amount for a given bucket for an energy consumption baseline (raw/real energy consumed)";
CM_ SG_ 1279 UI_energyDeltaElevationSinceTrip "Energy amount for a given bucket for an energy consumption baseline (raw/real energy consumed)";
CM_ SG_ 1279 UI_energyDeltaAccSinceTripStart "Energy amount for a given bucket for an energy consumption baseline (raw/real energy consumed)";
CM_ SG_ 1279 UI_uiDeltaOffsetTotalSinceTripSt "Energy amount for a given bucket for an energy consumption baseline (raw/real energy consumed)";
CM_ SG_ 1279 UI_uiDeltaOffsetDrivingSinceTrip "Energy amount for a given bucket for an energy consumption baseline (raw/real energy consumed)";
CM_ SG_ 1279 UI_uiDeltaOffsetClimateSinceTrip "Energy amount for a given bucket for an energy consumption baseline (raw/real energy consumed)";
CM_ SG_ 1279 UI_uiDeltaOffsetBattCondSinceTri "Energy amount for a given bucket for an energy consumption baseline (raw/real energy consumed)";
CM_ SG_ 1279 UI_uiDeltaOffsetElevationSinceTr "Energy amount for a given bucket for an energy consumption baseline (raw/real energy consumed)";
CM_ SG_ 1279 UI_uiDeltaOffsetAccSinceTripStar "Energy amount for a given bucket for an energy consumption baseline (raw/real energy consumed)";
CM_ SG_ 1279 UI_rawToUiEnergyRatioSinceTripSt "Ratio used for conversion between UI and raw energy domains";
CM_ SG_ 1279 UI_driveDistanceSinceTripStart "Distance driven for an energy consumption baseline";
CM_ SG_ 1279 UI_trailerMass "Trailer mass from user input";
CM_ BO_ 1139 "Touchscreen user interface computer message: eth nm";
CM_ SG_ 1139 UI_nmKeepAwakeReason "reason UI is being kept awake; raw 0 = signal not available (SNA)";
CM_ SG_ 1139 UI_wakeupTime "Unix epoch time at which vehicle should wake for scheduled charge or update.";
CM_ BO_ 820 "Touchscreen user interface computer message: powertrain control";
CM_ SG_ 820 UI_pedalMap "Switch between various platform specific pedal maps";
CM_ SG_ 820 UI_enableRegenBackfill "Indicates if regenerative braking backfill has been enabled by the driver";
CM_ SG_ 820 UI_regenTorqueMax "Maximum regen torque from UI - reports different value when in track mode";
CM_ SG_ 820 UI_limitMode "Commands limited drive inverter capabilities based on special vehicle modes";
CM_ SG_ 820 UI_motorOnMode "Request from the UI to selectively enable or disable a drive unit (dev-only)";
CM_ SG_ 820 UI_stoppingMode "Low-speed behavior when no pedal is pressed (stopping/rolling/creeping)";
CM_ SG_ 820 UI_speedLimit "Maximum allowed speed enforced at vehicle level; raw 511 = signal not available (SNA)";
CM_ SG_ 820 UI_enableSmartShift "Stalkless convenience feature that allows unparking with only a firm press of brake pedal";
CM_ SG_ 820 UI_navVehParallelToRdCanContinue "Whether the vehicle is parallel parked on a public road; raw 0 = signal not available (SNA)";
CM_ BO_ 563 "Touchscreen user interface computer message: stalkless control";
CM_ SG_ 563 UI_gearRequest "UI gear request from UI; raw 0 = signal not available (SNA)";
CM_ SG_ 563 UI_fullScreenMode "Aggregates all situations with which the UI is using the entire screen so stalkless gear controls are not present";
CM_ SG_ 563 UI_gearStripShowing "UI communicating to GTW that the gear strip is visible on the screen as part of a handshake";
CM_ SG_ 563 UI_gearStripForceShow "UI request to GTW to show the gear strip";
CM_ SG_ 563 UI_autoParkAvailable "UI communicating to GTW that the autpark functionality is available";
CM_ SG_ 563 UI_gearStripSuppressActive "UI communicating to GTW that the gear strip should not be shown";
CM_ SG_ 563 UI_gearNeutralPressed "Neutral button is being pressed";
CM_ BO_ 699 "Touchscreen user interface computer message: stalkless health status";
CM_ SG_ 699 UI_centerDisplayRunning "is center display running";
CM_ SG_ 699 UI_centerDisplayPowerOn "center display power on";
CM_ BO_ 991 "Touchscreen user interface computer message: status2";
CM_ SG_ 991 UI_userActivity "Indicates user interaction with the center display";
CM_ SG_ 991 UI_activeTouchPoints "Quantity of active touch points on the Center Display";
CM_ SG_ 991 UI_linkState "Connectivity link state";
CM_ SG_ 991 UI_autopilotSentryRequest "whether AP sentry mode should be enabled";
CM_ SG_ 991 UI_mobileAppConnected "Reports if Web Real-Time Communication (WebRTC) connection is connected while summon screen is open on the mobile app.";
CM_ SG_ 991 UI_autoshiftDRState "Reports the User Interface (UI) autoshift Drive/Reverse state.";
CM_ SG_ 991 UI_wifiBtModuleType "Reports the type of Wi-Fi and Bluetooth (BT) module.";
CM_ SG_ 991 UI_selfParkState "Reports the auto park state changes; raw 255 = signal not available (SNA)";
CM_ SG_ 991 UI_summonDeviceIndex "Reports which device is being used to control summon.";
CM_ BO_ 661 "Touchscreen user interface computer message: system monitor";
CM_ SG_ 661 UI_systemMonitorIndex "Touchscreen user interface computer: system monitor index";
CM_ SG_ 661 UI_SystemMemUsage "Monitors system memory usage";
CM_ SG_ 661 UI_QtCarMemUsage "Monitors memory usage of the primary User Interface application";
CM_ SG_ 661 UI_QtCarCPUUsage "Monitors CPU usage of the primary User Interface application";
CM_ SG_ 661 UI_SystemCPUUsage "Monitors system CPU usage";
CM_ BO_ 787 "Touchscreen user interface computer message: track mode settings";
CM_ SG_ 787 UI_trackModeRequest "User selected track mode";
CM_ SG_ 787 UI_trackDrivePowerAvailability "Reports power deployment strategy for Track Mode. Ranges from endurance limit to maximum power.";
CM_ BO_ 130 "Touchscreen user interface computer message: trip planning";
CM_ SG_ 130 UI_tripPlanningActive "Indicates that there is active route in navigation with a valid energy at destination prediction.";
CM_ SG_ 130 UI_navToSupercharger "Navigation destination is a supercharger";
CM_ SG_ 130 UI_navFastchargerType "when navigation is turned on, this enum identifies the type of fastcharger the car is navigating to based on the rated power from sc_locations";
CM_ SG_ 130 UI_battPreconditionOnNavState "Indicates to battery and thermal systems whether the battery should be actively heated, passively heated, actively cooled, or passively cooled";
CM_ SG_ 130 UI_requestActiveBatteryHeating "Flag to request BMS enable active battery heating";
CM_ SG_ 130 UI_battPreconditionOnNavPowerReq "The preconditioning power that Trip Planner is requesting from the thermal system to use for battery preconditioning (cooling or heating); raw 127 = signal not available (SNA)";
CM_ SG_ 130 UI_battPreconditionOnNavTargetT "The pack temperature that Trip Planner is targeting upon arriving to a fast charger; raw 255 = signal not available (SNA)";
CM_ SG_ 130 UI_energyAtDestination "expected energy at destination in kWh for current navigation route; raw 32768 = signal not available (SNA)";
CM_ BO_ 139 "Touchscreen user interface computer message: trip planning2";
CM_ SG_ 139 UI_maxSpeedToReachDestination "maximum speed to reach destination without significant risk of running out of energy; raw 65535 = signal not available (SNA)";
CM_ SG_ 139 UI_timeToDestination "remaining time to reach destination; raw 65535 = signal not available (SNA)";
CM_ BO_ 1173 "Touchscreen user interface computer message: trip planning3";
CM_ SG_ 1173 UI_predictedEnergy "initially predicted energy in kWh for current location along navigation route; raw 32768 = signal not available (SNA)";
CM_ SG_ 1173 UI_hindsightEnergy "hindsight energy, the model predicted energy based on measured speed and acceleration for the current location along navigation route; raw 32768 = signal not available (SNA)";
CM_ BO_ 947 "Touchscreen user interface computer message: vehicle control2";
CM_ SG_ 947 UI_gloveboxRequest "UI request to open the glovebox";
CM_ SG_ 947 UI_trunkRequest "Rear trunk request";
CM_ SG_ 947 UI_PINToDriveEnabled "UI customer level request to pin to drive enabled.";
CM_ SG_ 947 UI_PINToDrivePassed "UI customer level request to enable drive with pin passed.";
CM_ SG_ 947 UI_disableMirrorAutoDim "Request to disable side and rear-view mirror auto dim";
CM_ SG_ 947 UI_lightSwitch "Headlight mode; raw 4 = signal not available (SNA)";
CM_ SG_ 947 UI_readyToAddKey "Ready to add key";
CM_ SG_ 947 UI_alarmTriggerRequest "Alarm activation request from UI";
CM_ SG_ 947 UI_displayOnForUser "User is present";
CM_ SG_ 947 UI_BLEPushNotificationRequest "Reports that the User Interface (UI) wants to talk to a phone and Vehicle Controller Security (VCSEC) should let all connected phones know.";
CM_ SG_ 947 UI_keepAutopilotAwake "Reports the request for Vehicle Controller (VC) to keep autopilot awake.";
CM_ SG_ 947 UI_batteryPreconditioningRequest "Requests battery preconditioning.";
CM_ SG_ 947 UI_autopilotPowerStateRequest "Requests different power states from autopilot ECU depending on feature usage.";
CM_ SG_ 947 UI_autoRollWindowsOnLockEnable "UI customer level request to enable auto-roll windows on lock";
CM_ SG_ 947 UI_steeringWheelHeatReq "Request to enable steering wheel heater";
CM_ SG_ 947 UI_disableHorn "Request to disable horn";
CM_ SG_ 947 UI_frontLeftSeatFanReq "Request for front left seat ventilation";
CM_ SG_ 947 UI_frontRightSeatAutoClimateReq "UI setting to enable auto seat heating and cooling for front right seat";
CM_ SG_ 947 UI_frontRightSeatFanReq "Request for front left seat ventilation";
CM_ SG_ 947 UI_frontLeftSeatAutoClimateReq "UI setting to enable auto seat heating and cooling for front left seat";
CM_ SG_ 947 UI_wiperHeaterReq "UI request to enable the wiper heater";
CM_ SG_ 947 UI_silentAlarm "Signal indicating alarms should be silenced";
BA_DEF_ BO_ "GenMsgCycleTime" INT 0 3600000;
BA_DEF_ BO_ "GenMsgSendType" ENUM "Cyclic","NotUsed","NotUsed","NotUsed","NotUsed","NotUsed","NotUsed","IfActive","NoMsgSendType","NotUsed";
BA_DEF_ BO_ "VFrameFormat" ENUM "StandardCAN","ExtendedCAN","reserved","J1939PG","reserved","reserved","reserved","reserved","reserved","reserved","reserved","reserved","reserved","reserved","StandardCAN_FD","ExtendedCAN_FD";
BA_DEF_ BO_ "CANFD_BRS" ENUM "0","1";
BA_DEF_ SG_ "GenSigSNA" STRING;
BA_DEF_ SG_ "SystemSignalLongSymbol" STRING;
BA_DEF_ SG_ "Confidence" ENUM "validated","plausible","layout-only","contradicted";
BA_DEF_DEF_ "GenMsgCycleTime" 0;
BA_DEF_DEF_ "GenMsgSendType" "NoMsgSendType";
BA_DEF_DEF_ "VFrameFormat" "StandardCAN";
BA_DEF_DEF_ "CANFD_BRS" "1";
BA_DEF_DEF_ "GenSigSNA" "";
BA_DEF_DEF_ "SystemSignalLongSymbol" "";
BA_DEF_DEF_ "Confidence" "layout-only";
BA_ "GenMsgCycleTime" BO_ 522 1000;
BA_ "GenMsgSendType" BO_ 522 0;
BA_ "GenMsgCycleTime" BO_ 1962 1000;
BA_ "GenMsgSendType" BO_ 1962 0;
BA_ "GenMsgCycleTime" BO_ 2025 100;
BA_ "GenMsgSendType" BO_ 2025 0;
BA_ "GenMsgCycleTime" BO_ 670 100;
BA_ "GenMsgSendType" BO_ 670 0;
BA_ "GenMsgCycleTime" BO_ 2023 100;
BA_ "GenMsgSendType" BO_ 2023 0;
BA_ "GenMsgCycleTime" BO_ 828 10000;
BA_ "GenMsgSendType" BO_ 828 0;
BA_ "GenMsgCycleTime" BO_ 516 100;
BA_ "GenMsgSendType" BO_ 516 0;
BA_ "GenMsgCycleTime" BO_ 548 100;
BA_ "GenMsgSendType" BO_ 548 0;
BA_ "GenMsgCycleTime" BO_ 708 1000;
BA_ "GenMsgSendType" BO_ 708 0;
BA_ "GenMsgCycleTime" BO_ 463 10;
BA_ "GenMsgSendType" BO_ 463 0;
BA_ "GenMsgCycleTime" BO_ 1409 1000;
BA_ "GenMsgSendType" BO_ 1409 0;
BA_ "GenMsgCycleTime" BO_ 979 500;
BA_ "GenMsgSendType" BO_ 979 0;
BA_ "GenMsgCycleTime" BO_ 1657 500;
BA_ "GenMsgSendType" BO_ 1657 0;
BA_ "GenMsgCycleTime" BO_ 1021 500;
BA_ "GenMsgSendType" BO_ 1021 0;
BA_ "GenMsgCycleTime" BO_ 819 500;
BA_ "GenMsgSendType" BO_ 819 0;
BA_ "GenMsgCycleTime" BO_ 531 500;
BA_ "GenMsgSendType" BO_ 531 0;
BA_ "GenMsgCycleTime" BO_ 645 500;
BA_ "GenMsgSendType" BO_ 645 0;
BA_ "GenMsgCycleTime" BO_ 1279 1000;
BA_ "GenMsgSendType" BO_ 1279 0;
BA_ "GenMsgCycleTime" BO_ 1139 500;
BA_ "GenMsgSendType" BO_ 1139 0;
BA_ "GenMsgCycleTime" BO_ 820 500;
BA_ "GenMsgSendType" BO_ 820 0;
BA_ "GenMsgCycleTime" BO_ 563 500;
BA_ "GenMsgSendType" BO_ 563 0;
BA_ "GenMsgCycleTime" BO_ 699 500;
BA_ "GenMsgSendType" BO_ 699 0;
BA_ "GenMsgCycleTime" BO_ 991 500;
BA_ "GenMsgSendType" BO_ 991 0;
BA_ "GenMsgCycleTime" BO_ 661 15000;
BA_ "GenMsgSendType" BO_ 661 0;
BA_ "GenMsgCycleTime" BO_ 787 500;
BA_ "GenMsgSendType" BO_ 787 0;
BA_ "GenMsgCycleTime" BO_ 130 1000;
BA_ "GenMsgSendType" BO_ 130 0;
BA_ "GenMsgCycleTime" BO_ 139 1000;
BA_ "GenMsgSendType" BO_ 139 0;
BA_ "GenMsgCycleTime" BO_ 1173 1000;
BA_ "GenMsgSendType" BO_ 1173 0;
BA_ "GenMsgCycleTime" BO_ 947 500;
BA_ "GenMsgSendType" BO_ 947 0;
BA_ "Confidence" SG_ 522 HVP_packContNegativeState 0;
BA_ "GenSigSNA" SG_ 522 HVP_packContNegativeState "0";
BA_ "Confidence" SG_ 522 HVP_packContPositiveState 0;
BA_ "GenSigSNA" SG_ 522 HVP_packContPositiveState "0";
BA_ "Confidence" SG_ 522 HVP_fcContPositiveAuxOpen 0;
BA_ "Confidence" SG_ 522 HVP_fcContNegativeAuxOpen 0;
BA_ "Confidence" SG_ 522 HVP_packContactorSetState 0;
BA_ "GenSigSNA" SG_ 522 HVP_packContactorSetState "0";
BA_ "Confidence" SG_ 522 HVP_fcContNegativeState 0;
BA_ "GenSigSNA" SG_ 522 HVP_fcContNegativeState "0";
BA_ "Confidence" SG_ 522 HVP_fcContPositiveState 0;
BA_ "GenSigSNA" SG_ 522 HVP_fcContPositiveState "0";
BA_ "Confidence" SG_ 522 HVP_fcContactorSetState 0;
BA_ "GenSigSNA" SG_ 522 HVP_fcContactorSetState "0";
BA_ "Confidence" SG_ 522 HVP_fcCtrsRequestStatus 0;
BA_ "Confidence" SG_ 522 HVP_fcCtrsResetRequestRequired 0;
BA_ "Confidence" SG_ 522 HVP_fcCtrsOpenNowRequested 0;
BA_ "Confidence" SG_ 522 HVP_fcCtrsOpenRequested 0;
BA_ "Confidence" SG_ 522 HVP_fcCtrsClosingAllowed 0;
BA_ "Confidence" SG_ 522 HVP_packCtrsRequestStatus 0;
BA_ "Confidence" SG_ 522 HVP_packCtrsResetRequestRequired 0;
BA_ "Confidence" SG_ 522 HVP_packCtrsOpenNowRequested 0;
BA_ "Confidence" SG_ 522 HVP_packCtrsOpenRequested 0;
BA_ "Confidence" SG_ 522 HVP_packCtrsClosingAllowed 0;
BA_ "Confidence" SG_ 522 HVP_dcLinkAllowedToEnergize 0;
BA_ "Confidence" SG_ 522 HVP_pyroTestInProgress 0;
BA_ "Confidence" SG_ 522 HVP_hvilDiag 0;
BA_ "GenSigSNA" SG_ 522 HVP_hvilDiag "14";
BA_ "Confidence" SG_ 522 HVP_fcLinkAllowedToEnergize 0;
BA_ "Confidence" SG_ 1962 HVP_debugMessageMultiplexer 1;
BA_ "Confidence" SG_ 1962 HVP_gpioPassivePyroDepl 0;
BA_ "Confidence" SG_ 1962 HVP_gpioPyroIsoEn 0;
BA_ "Confidence" SG_ 1962 HVP_gpioCpFaultIn 0;
BA_ "Confidence" SG_ 1962 HVP_gpioPackContPowerEn 0;
BA_ "Confidence" SG_ 1962 HVP_gpioHvCablesOk 0;
BA_ "Confidence" SG_ 1962 HVP_gpioHvpSelfEnable 0;
BA_ "Confidence" SG_ 1962 HVP_gpioLed 0;
BA_ "Confidence" SG_ 1962 HVP_gpioCrashSignal 0;
BA_ "Confidence" SG_ 1962 HVP_gpioShuntDataReady 0;
BA_ "Confidence" SG_ 1962 HVP_gpioFcContPosAux 0;
BA_ "Confidence" SG_ 1962 HVP_gpioFcContNegAux 0;
BA_ "Confidence" SG_ 1962 HVP_gpioBmsEout 0;
BA_ "Confidence" SG_ 1962 HVP_gpioCpFaultOut 0;
BA_ "Confidence" SG_ 1962 HVP_gpioPyroPor 0;
BA_ "Confidence" SG_ 1962 HVP_gpioShuntEn 0;
BA_ "Confidence" SG_ 1962 HVP_gpioHvpVerEn 0;
BA_ "Confidence" SG_ 1962 HVP_gpioFcContFlywheelEnable 0;
BA_ "Confidence" SG_ 1962 HVP_gpioCpLatchEnable 0;
BA_ "Confidence" SG_ 1962 HVP_gpioFcContPowerEnable 0;
BA_ "Confidence" SG_ 1962 HVP_gpioHvilEnable 0;
BA_ "Confidence" SG_ 1962 HVP_gpioPortSelSpiRdy 0;
BA_ "Confidence" SG_ 1962 HVP_gpioPyroUnlock 0;
BA_ "Confidence" SG_ 1962 HVP_hvp1v5Ref 0;
BA_ "Confidence" SG_ 1962 HVP_packCurrentMia 0;
BA_ "Confidence" SG_ 1962 HVP_auxCurrentMia 0;
BA_ "Confidence" SG_ 1962 HVP_currentSenseMia 0;
BA_ "Confidence" SG_ 1962 HVP_shuntThermistorMissing 0;
BA_ "Confidence" SG_ 1962 HVP_shuntThermistorExpected 0;
BA_ "Confidence" SG_ 1962 HVP_shuntThermistorMia 0;
BA_ "Confidence" SG_ 1962 HVP_shuntUnexpectedThermistor 0;
BA_ "Confidence" SG_ 1962 HVP_shuntHwMia 0;
BA_ "Confidence" SG_ 1962 HVP_shuntCurrentIrrational 0;
BA_ "Confidence" SG_ 1962 HVP_shuntAsicTCompActive 0;
BA_ "Confidence" SG_ 1962 HVP_ecuLogUploadRequest 1;
BA_ "Confidence" SG_ 1962 HVP_packContVoltage 0;
BA_ "Confidence" SG_ 1962 HVP_packNegativeV 0;
BA_ "Confidence" SG_ 1962 HVP_packPositiveV 0;
BA_ "Confidence" SG_ 1962 HVP_pyroAnalog 0;
BA_ "Confidence" SG_ 1962 HVP_fcContCoilCurrent 0;
BA_ "Confidence" SG_ 1962 HVP_fcContVoltage 0;
BA_ "Confidence" SG_ 1962 HVP_hvilInVoltage 0;
BA_ "Confidence" SG_ 1962 HVP_hvilOutVoltage 0;
BA_ "Confidence" SG_ 1962 HVP_shuntGainInvalidCountDbg 0;
BA_ "Confidence" SG_ 1962 HVP_fcLinkPositiveV 1;
BA_ "Confidence" SG_ 1962 HVP_packContCoilCurrent 0;
BA_ "Confidence" SG_ 1962 HVP_battery12V 0;
BA_ "Confidence" SG_ 2025 ICR_occupancy1LRaw 0;
BA_ "GenSigSNA" SG_ 2025 ICR_occupancy1LRaw "3";
BA_ "Confidence" SG_ 2025 ICR_occupancy1RRaw 0;
BA_ "GenSigSNA" SG_ 2025 ICR_occupancy1RRaw "3";
BA_ "Confidence" SG_ 2025 ICR_occupancy1LVoteCnt 0;
BA_ "Confidence" SG_ 2025 ICR_occupancy1RVoteCnt 0;
BA_ "Confidence" SG_ 2025 ICR_userPresenceFilt 1;
BA_ "GenSigSNA" SG_ 2025 ICR_userPresenceFilt "3";
BA_ "Confidence" SG_ 2025 ICR_userPresenceRaw 1;
BA_ "GenSigSNA" SG_ 2025 ICR_userPresenceRaw "3";
BA_ "Confidence" SG_ 2025 ICR_occupancy1LFilt 1;
BA_ "GenSigSNA" SG_ 2025 ICR_occupancy1LFilt "3";
BA_ "Confidence" SG_ 2025 ICR_occupancy1RFilt 1;
BA_ "GenSigSNA" SG_ 2025 ICR_occupancy1RFilt "3";
BA_ "Confidence" SG_ 2025 ICR_occupancy2LFilt 1;
BA_ "GenSigSNA" SG_ 2025 ICR_occupancy2LFilt "3";
BA_ "Confidence" SG_ 2025 ICR_occupancy2CFilt 1;
BA_ "GenSigSNA" SG_ 2025 ICR_occupancy2CFilt "3";
BA_ "Confidence" SG_ 2025 ICR_occupancy2RFilt 1;
BA_ "GenSigSNA" SG_ 2025 ICR_occupancy2RFilt "3";
BA_ "Confidence" SG_ 2025 ICR_classification1LFilt 1;
BA_ "GenSigSNA" SG_ 2025 ICR_classification1LFilt "0";
BA_ "Confidence" SG_ 2025 ICR_classification1RqF 1;
BA_ "Confidence" SG_ 2025 ICR_occupancy1RFiltExp 1;
BA_ "GenSigSNA" SG_ 2025 ICR_occupancy1RFiltExp "3";
BA_ "Confidence" SG_ 670 ICR_userPresenceMLOutput 1;
BA_ "GenSigSNA" SG_ 670 ICR_userPresenceMLOutput "255";
BA_ "Confidence" SG_ 670 ICR_classification1RFilt 1;
BA_ "GenSigSNA" SG_ 670 ICR_classification1RFilt "0";
BA_ "Confidence" SG_ 670 ICR_classification1LRaw 1;
BA_ "GenSigSNA" SG_ 670 ICR_classification1LRaw "0";
BA_ "Confidence" SG_ 670 ICR_classification1RRaw 1;
BA_ "GenSigSNA" SG_ 670 ICR_classification1RRaw "0";
BA_ "Confidence" SG_ 670 ICR_classification1LMLOutput 1;
BA_ "GenSigSNA" SG_ 670 ICR_classification1LMLOutput "255";
BA_ "Confidence" SG_ 670 ICR_classification1RMLOutput 1;
BA_ "GenSigSNA" SG_ 670 ICR_classification1RMLOutput "255";
BA_ "Confidence" SG_ 670 ICR_occupancy2Checksum 0;
BA_ "Confidence" SG_ 2023 ICR_sensorMode 1;
BA_ "Confidence" SG_ 2023 ICR_blocked 1;
BA_ "GenSigSNA" SG_ 2023 ICR_blocked "0";
BA_ "Confidence" SG_ 2023 ICR_algoVersion 1;
BA_ "Confidence" SG_ 2023 ICR_l2HeapUsage 1;
BA_ "Confidence" SG_ 2023 ICR_intrusionStatus 1;
BA_ "Confidence" SG_ 2023 ICR_booted 1;
BA_ "Confidence" SG_ 828 IDB_infoIndex 1;
BA_ "Confidence" SG_ 828 IDB_infoPcbaID 0;
BA_ "Confidence" SG_ 828 IDB_infoAssemblyID 0;
BA_ "Confidence" SG_ 828 IDB_infoUsageID 0;
BA_ "Confidence" SG_ 828 IDB_infoSubUsageID 0;
BA_ "Confidence" SG_ 516 PCS_chgMainState 0;
BA_ "Confidence" SG_ 516 PCS_gridConfig 0;
BA_ "GenSigSNA" SG_ 516 PCS_gridConfig "0";
BA_ "Confidence" SG_ 516 PCS_chgPHAEnable 0;
BA_ "Confidence" SG_ 516 PCS_chgPHBEnable 0;
BA_ "Confidence" SG_ 516 PCS_hvInletConductorEnergizedAc 0;
BA_ "Confidence" SG_ 516 PCS_chgHighPowerActive 0;
BA_ "Confidence" SG_ 516 PCS_chgPHCEnable 0;
BA_ "Confidence" SG_ 516 PCS_chgInstantAcPowerAvailable 0;
BA_ "Confidence" SG_ 516 PCS_chgMaxAcPowerAvailable 0;
BA_ "GenSigSNA" SG_ 516 PCS_chgMaxAcPowerAvailable "255";
BA_ "Confidence" SG_ 516 PCS_chgPHALineCurrentRequest 0;
BA_ "Confidence" SG_ 516 PCS_chgPHBLineCurrentRequest 0;
BA_ "Confidence" SG_ 516 PCS_chgPHCLineCurrentRequest 0;
BA_ "Confidence" SG_ 516 PCS_chgPwmEnableLine 0;
BA_ "Confidence" SG_ 516 PCS_hwVariantType 0;
BA_ "GenSigSNA" SG_ 516 PCS_hwVariantType "3";
BA_ "Confidence" SG_ 548 PCS_dcdcPrechargeStatus 0;
BA_ "Confidence" SG_ 548 PCS_dcdcLvSupportStatus 0;
BA_ "Confidence" SG_ 548 PCS_dcdcHvBusDischargeStatus 0;
BA_ "Confidence" SG_ 548 PCS_coldSleepAllowed 0;
BA_ "Confidence" SG_ 548 PCS_dcdcPchgHVBusLowRDetected 0;
BA_ "Confidence" SG_ 548 PCS_dcdcSubState 0;
BA_ "Confidence" SG_ 548 PCS_dcdcFaulted 0;
BA_ "Confidence" SG_ 548 PCS_okToBePowerCycled 0;
BA_ "Confidence" SG_ 548 PCS_dcdcOutputIsLimited 0;
BA_ "Confidence" SG_ 548 PCS_dcdcMaxOutputCurrentAllowed 0;
BA_ "Confidence" SG_ 548 PCS_dcdcPrechargeRtyCnt 0;
BA_ "Confidence" SG_ 548 PCS_dcdcLvSupportRtyCnt 0;
BA_ "Confidence" SG_ 548 PCS_dcdcDischargeRtyCnt 0;
BA_ "Confidence" SG_ 548 PCS_dcdcPwmEnableLine 0;
BA_ "Confidence" SG_ 548 PCS_dcdcSupportingFixedLvTarget 0;
BA_ "Confidence" SG_ 548 PCS_ecuLogUploadRequest 0;
BA_ "Confidence" SG_ 548 PCS_dcdcPrechargeRestartCnt 0;
BA_ "Confidence" SG_ 548 PCS_dcdcInitialPrechargeSubState 0;
BA_ "Confidence" SG_ 708 PCS_logMessageSelect 1;
BA_ "Confidence" SG_ 708 PCS_chgPhAInputIrms 0;
BA_ "Confidence" SG_ 708 PCS_chgPhAIntBusV 0;
BA_ "Confidence" SG_ 708 PCS_chgPhAIntBusVTarget 0;
BA_ "Confidence" SG_ 708 PCS_chgPhAOutputI 0;
BA_ "Confidence" SG_ 708 PCS_chgPhAInputCurrentLimitReaso 0;
BA_ "SystemSignalLongSymbol" SG_ 708 PCS_chgPhAInputCurrentLimitReaso "PCS_chgPhAInputCurrentLimitReason";
BA_ "Confidence" SG_ 708 PCS_chgPhBInputIrms 0;
BA_ "Confidence" SG_ 708 PCS_chgPhBIntBusV 0;
BA_ "Confidence" SG_ 708 PCS_chgPhBIntBusVTarget 0;
BA_ "Confidence" SG_ 708 PCS_chgPhBOutputI 0;
BA_ "Confidence" SG_ 708 PCS_chgPhBInputCurrentLimitReaso 0;
BA_ "SystemSignalLongSymbol" SG_ 708 PCS_chgPhBInputCurrentLimitReaso "PCS_chgPhBInputCurrentLimitReason";
BA_ "Confidence" SG_ 708 PCS_chgPhCInputIrms 0;
BA_ "Confidence" SG_ 708 PCS_chgPhCIntBusV 0;
BA_ "Confidence" SG_ 708 PCS_chgPhCIntBusVTarget 0;
BA_ "Confidence" SG_ 708 PCS_chgPhCOutputI 0;
BA_ "Confidence" SG_ 708 PCS_chgPhCInputCurrentLimitReaso 0;
BA_ "SystemSignalLongSymbol" SG_ 708 PCS_chgPhCInputCurrentLimitReaso "PCS_chgPhCInputCurrentLimitReason";
BA_ "Confidence" SG_ 708 PCS_chgInputL1NVrms 0;
BA_ "Confidence" SG_ 708 PCS_chgInputL2NVrms 0;
BA_ "Confidence" SG_ 708 PCS_chgInputL3NVrms 0;
BA_ "Confidence" SG_ 708 PCS_chgInputL1L2Vrms 0;
BA_ "Confidence" SG_ 708 PCS_chgInputNGVrms 0;
BA_ "Confidence" SG_ 708 PCS_chgInputFrequencyL1N 0;
BA_ "Confidence" SG_ 708 PCS_chgInputFrequencyL2N 0;
BA_ "Confidence" SG_ 708 PCS_chgInputFrequencyL3N 0;
BA_ "Confidence" SG_ 708 PCS_chgInternalPhaseConfig 0;
BA_ "GenSigSNA" SG_ 708 PCS_chgInternalPhaseConfig "0";
BA_ "Confidence" SG_ 708 PCS_chgPhasesPriority 0;
BA_ "Confidence" SG_ 708 PCS_chgOutputV 0;
BA_ "Confidence" SG_ 708 PCS_chgPhAState 0;
BA_ "Confidence" SG_ 708 PCS_chgPhBState 0;
BA_ "Confidence" SG_ 708 PCS_chgPhCState 0;
BA_ "Confidence" SG_ 708 PCS_chgPhALastShutdownReason 0;
BA_ "Confidence" SG_ 708 PCS_chgPhBLastShutdownReason 0;
BA_ "Confidence" SG_ 708 PCS_chgPhCLastShutdownReason 0;
BA_ "Confidence" SG_ 708 PCS_chgPhARetryCount 0;
BA_ "Confidence" SG_ 708 PCS_chgPhBRetryCount 0;
BA_ "Confidence" SG_ 708 PCS_chgPhCRetryCount 0;
BA_ "Confidence" SG_ 708 PCS_chgRetryCount 0;
BA_ "Confidence" SG_ 708 PCS_chgPhManCurrentToDist 0;
BA_ "Confidence" SG_ 708 PCS_chgL1NPllLocked 0;
BA_ "Confidence" SG_ 708 PCS_chgL2NPllLocked 0;
BA_ "Confidence" SG_ 708 PCS_chgL3NPllLocked 0;
BA_ "Confidence" SG_ 708 PCS_chgL1L2PllLocked 0;
BA_ "Confidence" SG_ 708 PCS_chgNgPllLocked 0;
BA_ "Confidence" SG_ 708 PCS_chgPhManOptimalPhsToUse 0;
BA_ "Confidence" SG_ 708 PCS_chg5VL1Enable 0;
BA_ "Confidence" SG_ 708 PCS_dcdcMaxLvOutputCurrent 0;
BA_ "Confidence" SG_ 708 PCS_dcdcCurrentLimit 0;
BA_ "Confidence" SG_ 708 PCS_dcdcLvOutputCurrentTempLimit 0;
BA_ "Confidence" SG_ 708 PCS_dcdcLvOutputCurrentFiltered 0;
BA_ "Confidence" SG_ 708 PCS_dcdcUnifiedCommand 0;
BA_ "Confidence" SG_ 708 PCS_dcdcCLAControllerOutput 0;
BA_ "Confidence" SG_ 708 PCS_dcdcTankVoltage 0;
BA_ "GenSigSNA" SG_ 708 PCS_dcdcTankVoltage "1024";
BA_ "Confidence" SG_ 708 PCS_dcdcTankVoltageTarget 0;
BA_ "Confidence" SG_ 708 PCS_dcdcClaCurrentFreq 0;
BA_ "Confidence" SG_ 708 PCS_dcdcTCommMeasured 0;
BA_ "Confidence" SG_ 708 PCS_dcdcShortTimeUs 0;
BA_ "Confidence" SG_ 708 PCS_dcdcHalfPeriodUs 0;
BA_ "Confidence" SG_ 708 PCS_dcdcLvBusVoltTargetWithOffse 0;
BA_ "SystemSignalLongSymbol" SG_ 708 PCS_dcdcLvBusVoltTargetWithOffse "PCS_dcdcLvBusVoltTargetWithOffset";
BA_ "Confidence" SG_ 708 PCS_cpu2BootState 0;
BA_ "Confidence" SG_ 708 PCS_acChargeSelfTestState 0;
BA_ "Confidence" SG_ 708 PCS_1V5Min10s 0;
BA_ "Confidence" SG_ 708 PCS_1V5Max10s 0;
BA_ "Confidence" SG_ 708 PCS_1V2Min10s 0;
BA_ "Confidence" SG_ 708 PCS_1V2Max10s 0;
BA_ "Confidence" SG_ 708 PCS_5VNMax10s 0;
BA_ "Confidence" SG_ 708 PCS_chgPhAIntBusVMin10s 0;
BA_ "Confidence" SG_ 708 PCS_chgPhAIntBusVMax10s 0;
BA_ "Confidence" SG_ 708 PCS_chgPhAPchgVoltDeltaMax10s 0;
BA_ "Confidence" SG_ 708 PCS_chgPhALifetimekWh 0;
BA_ "Confidence" SG_ 708 PCS_chgPhATransientRetryCount 0;
BA_ "Confidence" SG_ 708 PCS_chgPhBIntBusVMin10s 0;
BA_ "Confidence" SG_ 708 PCS_chgPhBIntBusVMax10s 0;
BA_ "Confidence" SG_ 708 PCS_chgPhBPchgVoltDeltaMax10s 0;
BA_ "Confidence" SG_ 708 PCS_chgPhBLifetimekWh 0;
BA_ "Confidence" SG_ 708 PCS_chgPhBTransientRetryCount 0;
BA_ "Confidence" SG_ 708 PCS_chgPhCIntBusVMin10s 0;
BA_ "Confidence" SG_ 708 PCS_chgPhCIntBusVMax10s 0;
BA_ "Confidence" SG_ 708 PCS_chgPhCPchgVoltDeltaMax10s 0;
BA_ "Confidence" SG_ 708 PCS_chgPhCLifetimekWh 0;
BA_ "Confidence" SG_ 708 PCS_chgPhCTransientRetryCount 0;
BA_ "Confidence" SG_ 708 PCS_chgPhANoFlowBucket 0;
BA_ "Confidence" SG_ 708 PCS_chgPhBNoFlowBucket 0;
BA_ "Confidence" SG_ 708 PCS_chgPhCNoFlowBucket 0;
BA_ "Confidence" SG_ 708 PCS_chgCurrentSensorOutOfBandUs 0;
BA_ "Confidence" SG_ 708 PCS_chgAcpwHeartbeatState 0;
BA_ "Confidence" SG_ 708 PCS_chgKwhLostByFreqDroop 0;
BA_ "Confidence" SG_ 708 PCS_chgReqKwhLostByFreqDroop 0;
BA_ "Confidence" SG_ 708 PCS_dcdcLvSupportLifetimekWh 0;
BA_ "Confidence" SG_ 708 PCS_chgPwmEnableLineErrorCount 0;
BA_ "Confidence" SG_ 708 PCS_dcdcPwmEnableLineErrorCount 0;
BA_ "Confidence" SG_ 708 PCS_numAlertsSet 0;
BA_ "Confidence" SG_ 708 PCS_dcdcPchgStartLvBusVolt 0;
BA_ "Confidence" SG_ 708 PCS_dcdcPchgStartHvBusVolt 0;
BA_ "Confidence" SG_ 708 PCS_processorDieIdLot 0;
BA_ "Confidence" SG_ 708 PCS_processorDieIdWafer 0;
BA_ "Confidence" SG_ 708 PCS_processorDieIdX 0;
BA_ "Confidence" SG_ 708 PCS_processorDieIdY 0;
BA_ "Confidence" SG_ 463 PM_hvilSystemStatus 1;
BA_ "GenSigSNA" SG_ 463 PM_hvilSystemStatus "3";
BA_ "Confidence" SG_ 1409 TCU_logMux 1;
BA_ "Confidence" SG_ 1409 TCU_cpuTemp 0;
BA_ "Confidence" SG_ 1409 TCU_cpuUsage 0;
BA_ "Confidence" SG_ 1409 TCU_mdmCoreTemperature 0;
BA_ "Confidence" SG_ 1409 TCU_availableMemory 0;
BA_ "Confidence" SG_ 1409 TCU_pwm 0;
BA_ "Confidence" SG_ 1409 TCU_pwmcap 0;
BA_ "Confidence" SG_ 1409 TCU_totalResumes 0;
BA_ "Confidence" SG_ 1409 TCU_mdmUplinkQueueSize 0;
BA_ "Confidence" SG_ 1409 TCU_mdmRSRP 0;
BA_ "Confidence" SG_ 1409 TCU_mdmSINR 0;
BA_ "Confidence" SG_ 1409 TCU_mdmUplinkAllowedRate 0;
BA_ "Confidence" SG_ 1409 TCU_mdmServiceState 0;
BA_ "Confidence" SG_ 1409 TCU_mdmIMSStatus 0;
BA_ "Confidence" SG_ 1409 TCU_mdmSIMStatus 0;
BA_ "Confidence" SG_ 1409 TCU_mdmBusyActive 0;
BA_ "GenSigSNA" SG_ 1409 TCU_mdmBusyActive "4294967295";
BA_ "Confidence" SG_ 1056 UIS_logMux 1;
BA_ "Confidence" SG_ 1056 UIS_wifiTemperature 0;
BA_ "Confidence" SG_ 1056 UIS_wifiStackState 0;
BA_ "Confidence" SG_ 1056 UIS_wifiBars 0;
BA_ "Confidence" SG_ 1056 UIS_wifiAutoJoinLowRSSI 0;
BA_ "Confidence" SG_ 1056 UIS_valetMode 0;
BA_ "Confidence" SG_ 1056 UIS_uiQtCarUptime 0;
BA_ "Confidence" SG_ 1056 UIS_uiMeanFPS 0;
BA_ "Confidence" SG_ 1056 UIS_tunerVoltageOperation 0;
BA_ "Confidence" SG_ 1056 UIS_tunerVoltageAntenna2 0;
BA_ "Confidence" SG_ 1056 UIS_tunerVoltageAntenna1 0;
BA_ "Confidence" SG_ 1056 UIS_tunerCurrentAntenna2 0;
BA_ "Confidence" SG_ 1056 UIS_tunerCurrentAntenna1 0;
BA_ "Confidence" SG_ 1056 UIS_tegraModemManState 0;
BA_ "Confidence" SG_ 1056 UIS_systemWakeTime 0;
BA_ "Confidence" SG_ 1056 UIS_systemUptime 0;
BA_ "Confidence" SG_ 1056 UIS_suspensionGeofence 0;
BA_ "Confidence" SG_ 1056 UIS_superchargePaymentNeeded 0;
BA_ "Confidence" SG_ 1056 UIS_sleepType 0;
BA_ "Confidence" SG_ 1056 UIS_sleepTime 0;
BA_ "Confidence" SG_ 1056 UIS_sleepState 0;
BA_ "Confidence" SG_ 1056 UIS_slackerLoginResult 0;
BA_ "Confidence" SG_ 1056 UIS_sentryState 0;
BA_ "Confidence" SG_ 1056 UIS_sentryNeedsNap 0;
BA_ "Confidence" SG_ 1056 UIS_sentryIncidentCount 0;
BA_ "Confidence" SG_ 1056 UIS_scheduledChargingMode 0;
BA_ "Confidence" SG_ 1056 UIS_scheduleChargeStartTime 0;
BA_ "Confidence" SG_ 1056 UIS_scheduleChargeEndTime 0;
BA_ "Confidence" SG_ 1056 UIS_remoteRequestType 0;
BA_ "Confidence" SG_ 1056 UIS_rearDisplayUserPresent 0;
BA_ "Confidence" SG_ 1056 UIS_rearDisplayState 0;
BA_ "Confidence" SG_ 1056 UIS_powerManagerState 0;
BA_ "GenSigSNA" SG_ 1056 UIS_powerManagerState "18";
BA_ "Confidence" SG_ 1056 UIS_polytopiax8664MemUsage 0;
BA_ "Confidence" SG_ 1056 UIS_polytopiax8664CPUUsage 0;
BA_ "Confidence" SG_ 1056 UIS_navAudioVolume 0;
BA_ "Confidence" SG_ 1056 UIS_muteNavVolume 0;
BA_ "Confidence" SG_ 1056 UIS_modemECallppAvail 0;
BA_ "Confidence" SG_ 1056 UIS_modemBusyActive 0;
BA_ "Confidence" SG_ 1056 UIS_mirrorGeofenceActive 0;
BA_ "Confidence" SG_ 1056 UIS_mediaPlaybackStatus 0;
BA_ "Confidence" SG_ 1056 UIS_mediaNeedAuthToken 0;
BA_ "Confidence" SG_ 1056 UIS_inSuperchargerGeofence 0;
BA_ "Confidence" SG_ 1056 UIS_homelinkState 0;
BA_ "Confidence" SG_ 1056 UIS_headsetPairResult 0;
BA_ "Confidence" SG_ 1056 UIS_headsetConnectionState 0;
BA_ "Confidence" SG_ 1056 UIS_gpsmanagerMemUsage 0;
BA_ "Confidence" SG_ 1056 UIS_gpsmanagerCPUUsage 0;
BA_ "Confidence" SG_ 1056 UIS_featureSuperchargingEnabled 0;
BA_ "Confidence" SG_ 1056 UIS_dmRearTouchDeviceExists 0;
BA_ "Confidence" SG_ 1056 UIS_dmRearPowerState 0;
BA_ "Confidence" SG_ 1056 UIS_dmRearLinkCheckOk 0;
BA_ "Confidence" SG_ 1056 UIS_dmRearEnabled 0;
BA_ "Confidence" SG_ 1056 UIS_dmRearConnected 0;
BA_ "Confidence" SG_ 1056 UIS_dmRearBacklightDutyCycle 0;
BA_ "Confidence" SG_ 1056 UIS_dmRearBacklightDevExists 0;
BA_ "Confidence" SG_ 1056 UIS_dmIcuPowerState 0;
BA_ "Confidence" SG_ 1056 UIS_dmIcuLinkCheckOk 0;
BA_ "Confidence" SG_ 1056 UIS_dmIcuEnabled 0;
BA_ "Confidence" SG_ 1056 UIS_dmIcuConnected 0;
BA_ "Confidence" SG_ 1056 UIS_dmIcuBacklightDutyCycle 0;
BA_ "Confidence" SG_ 1056 UIS_dmIcuBacklightDevExists 0;
BA_ "Confidence" SG_ 1056 UIS_dmGatewayLinkWedged 0;
BA_ "Confidence" SG_ 1056 UIS_dmCenterTouchDeviceExists 0;
BA_ "Confidence" SG_ 1056 UIS_dmCenterPowerState 0;
BA_ "Confidence" SG_ 1056 UIS_dmCenterOsdDisplayedState 0;
BA_ "Confidence" SG_ 1056 UIS_dmCenterLinkCheckOk 0;
BA_ "Confidence" SG_ 1056 UIS_dmCenterEnabled 0;
BA_ "Confidence" SG_ 1056 UIS_dmCenterConnected 0;
BA_ "Confidence" SG_ 1056 UIS_dmCenterBacklightPowerLevel 0;
BA_ "Confidence" SG_ 1056 UIS_dmCenterBacklightDutyCycle 0;
BA_ "Confidence" SG_ 1056 UIS_dmCenterBacklightDevExists 0;
BA_ "Confidence" SG_ 1056 UIS_dgpuTemperature 0;
BA_ "Confidence" SG_ 1056 UIS_dashcamviewerMemUsage 0;
BA_ "Confidence" SG_ 1056 UIS_dashcamviewerCPUUsage 0;
BA_ "Confidence" SG_ 1056 UIS_dashcamStorageState 0;
BA_ "Confidence" SG_ 1056 UIS_dashcamStorageSentryMB 0;
BA_ "Confidence" SG_ 1056 UIS_dashcamStorageSavedMB 0;
BA_ "Confidence" SG_ 1056 UIS_dashcamStorageRecentMB 0;
BA_ "Confidence" SG_ 1056 UIS_dashcamStorageAvailableMB 0;
BA_ "Confidence" SG_ 1056 UIS_dashcamState 0;
BA_ "Confidence" SG_ 1056 UIS_cpuTemperature 0;
BA_ "Confidence" SG_ 1056 UIS_clusterMemUsage 0;
BA_ "Confidence" SG_ 1056 UIS_clusterDisplayState 0;
BA_ "Confidence" SG_ 1056 UIS_clusterCPUUsage 0;
BA_ "Confidence" SG_ 1056 UIS_chargeOnSolarNoChargeReason 0;
BA_ "Confidence" SG_ 1056 UIS_centerDisplayState 0;
BA_ "Confidence" SG_ 1056 UIS_centerDisplayEvent 0;
BA_ "Confidence" SG_ 1056 UIS_cellularLinkManagerState 0;
BA_ "Confidence" SG_ 1056 UIS_carAssistState 0;
BA_ "Confidence" SG_ 1056 UIS_carAssistSessionCount 0;
BA_ "Confidence" SG_ 1056 UIS_carAssistErrorCode 0;
BA_ "Confidence" SG_ 1056 UIS_cameraRRepeaterStreamMissing 0;
BA_ "Confidence" SG_ 1056 UIS_cameraRRepeaterPopup 0;
BA_ "Confidence" SG_ 1056 UIS_cameraRRepeaterPipeline 0;
BA_ "Confidence" SG_ 1056 UIS_cameraLRepeaterStreamMissing 0;
BA_ "Confidence" SG_ 1056 UIS_cameraLRepeaterPopup 0;
BA_ "Confidence" SG_ 1056 UIS_cameraLRepeaterPipeline 0;
BA_ "Confidence" SG_ 1056 UIS_cameraBackupStreamMissing 0;
BA_ "Confidence" SG_ 1056 UIS_cameraBackupPopup 0;
BA_ "Confidence" SG_ 1056 UIS_cameraBackupPipeline 0;
BA_ "Confidence" SG_ 1056 UIS_cameraBackupFramerate 0;
BA_ "Confidence" SG_ 1056 UIS_boardTemperature 0;
BA_ "Confidence" SG_ 1056 UIS_bluetoothStackState 0;
BA_ "Confidence" SG_ 1056 UIS_bluetoothStackRearState 0;
BA_ "Confidence" SG_ 1056 UIS_bluetoothPairResult 0;
BA_ "Confidence" SG_ 1056 UIS_bluetoothMemUsage 0;
BA_ "Confidence" SG_ 1056 UIS_bluetoothConnectionState 0;
BA_ "Confidence" SG_ 1056 UIS_bluetoothCPUUsage 0;
BA_ "Confidence" SG_ 1056 UIS_bluetoothAutoConnectionState 0;
BA_ "Confidence" SG_ 1056 UIS_backlightUserRequest 0;
BA_ "Confidence" SG_ 1056 UIS_audioVolumeLevel 0;
BA_ "Confidence" SG_ 1056 UIS_audioType 0;
BA_ "Confidence" SG_ 1056 UIS_audioState 0;
BA_ "Confidence" SG_ 1056 UIS_audioSource 0;
BA_ "Confidence" SG_ 1056 UIS_audioPWSGain 0;
BA_ "Confidence" SG_ 1056 UIS_audioMediaPlaying 0;
BA_ "Confidence" SG_ 1056 UIS_audioMediaBrowsing 0;
BA_ "Confidence" SG_ 1056 UIS_audioA2BRediscoveryCount 0;
BA_ "Confidence" SG_ 1056 UIS_activeAppView 0;
BA_ "Confidence" SG_ 979 UI_airbagCutoffSwState 0;
BA_ "GenSigSNA" SG_ 979 UI_airbagCutoffSwState "2";
BA_ "Confidence" SG_ 1657 UI_rgbEnableState 0;
BA_ "Confidence" SG_ 1657 UI_rgbEffectType 0;
BA_ "Confidence" SG_ 1657 UI_rgbBrightnessLevel 0;
BA_ "GenSigSNA" SG_ 1657 UI_rgbBrightnessLevel "127";
BA_ "Confidence" SG_ 1657 UI_rgbTargetDOORFL 0;
BA_ "Confidence" SG_ 1657 UI_rgbTargetDOORFR 0;
BA_ "Confidence" SG_ 1657 UI_rgbTargetDOORRL 0;
BA_ "Confidence" SG_ 1657 UI_rgbTargetDOORRR 0;
BA_ "Confidence" SG_ 1657 UI_rgbTargetIPFL 0;
BA_ "Confidence" SG_ 1657 UI_rgbTargetIPFR 0;
BA_ "Confidence" SG_ 1021 UI_autopilotControlIndex 1;
BA_ "Confidence" SG_ 1021 UI_hovEnabled 0;
BA_ "Confidence" SG_ 1021 UI_smartSetSpeedOffset 0;
BA_ "Confidence" SG_ 1021 UI_smartSetSpeedOffsetType 0;
BA_ "Confidence" SG_ 1021 UI_fsdStopsControlEnabled 0;
BA_ "Confidence" SG_ 1021 UI_smartSetSpeed 0;
BA_ "Confidence" SG_ 1021 UI_automaticSetSpeedOffset 0;
BA_ "Confidence" SG_ 1021 UI_enableFullSelfDriving 0;
BA_ "Confidence" SG_ 1021 UI_hasFullSelfDriving 0;
BA_ "Confidence" SG_ 1021 UI_autosteerActivation 0;
BA_ "Confidence" SG_ 1021 UI_autopilotDrivingProfile 1;
BA_ "Confidence" SG_ 1021 UI_fsdBetaRequest 0;
BA_ "Confidence" SG_ 1021 UI_fullSelfDrivingSuspended 0;
BA_ "Confidence" SG_ 1021 UI_disableOptionalLaneChanges 0;
BA_ "Confidence" SG_ 1021 UI_selectableCameraRequest 0;
BA_ "GenSigSNA" SG_ 1021 UI_selectableCameraRequest "15";
BA_ "Confidence" SG_ 1021 UI_driverMonitorConfirmation 0;
BA_ "Confidence" SG_ 1021 UI_parkAssistUseVision 0;
BA_ "Confidence" SG_ 1021 UI_noStalkConfirmAlertHaptic 0;
BA_ "Confidence" SG_ 1021 UI_noStalkConfirmAlertChime 0;
BA_ "Confidence" SG_ 1021 UI_factorySummonEnable 0;
BA_ "Confidence" SG_ 1021 UI_enableCabinCamera 0;
BA_ "Confidence" SG_ 1021 UI_enableAutopilotStopWarning 0;
BA_ "Confidence" SG_ 1021 UI_enableVisionSpeedControl 0;
BA_ "Confidence" SG_ 1021 UI_enableTeslaAutopark 0;
BA_ "Confidence" SG_ 1021 UI_autoTurnSignalMode 0;
BA_ "Confidence" SG_ 1021 UI_enableCabinAudioRecording 0;
BA_ "Confidence" SG_ 819 UI_openChargePortDoorRequest 0;
BA_ "Confidence" SG_ 819 UI_closeChargePortDoorRequest 0;
BA_ "Confidence" SG_ 819 UI_chargeEnableRequest 0;
BA_ "Confidence" SG_ 819 UI_acChargeCurrentLimit 0;
BA_ "GenSigSNA" SG_ 819 UI_acChargeCurrentLimit "127";
BA_ "Confidence" SG_ 819 UI_dSocAlertEnable 1;
BA_ "Confidence" SG_ 819 UI_chargeTerminationPct 0;
BA_ "Confidence" SG_ 819 UI_scheduledDepartureEnabled 0;
BA_ "Confidence" SG_ 819 UI_chargePortLatchRequest 0;
BA_ "Confidence" SG_ 819 UI_cpInletHeaterRequest 0;
BA_ "Confidence" SG_ 531 UI_cruiseSpeedCommand 0;
BA_ "Confidence" SG_ 645 UI_driverProfileRecallIndex 1;
BA_ "GenSigSNA" SG_ 645 UI_driverProfileRecallIndex "0";
BA_ "Confidence" SG_ 645 UI_driverProfileRecallStop 0;
BA_ "Confidence" SG_ 645 UI_frontSeatRecallActive 0;
BA_ "Confidence" SG_ 645 UI_leftMirrorTiltXPosition 0;
BA_ "Confidence" SG_ 645 UI_leftMirrorTiltYPosition 0;
BA_ "Confidence" SG_ 645 UI_customMirrorDipPositionsSet 0;
BA_ "Confidence" SG_ 645 UI_leftMirrorDipXPosition 0;
BA_ "Confidence" SG_ 645 UI_leftMirrorDipYPosition 0;
BA_ "Confidence" SG_ 645 UI_modifyMirrorDipRequest 0;
BA_ "Confidence" SG_ 1279 UI_energyConsumptionInfoIndex 1;
BA_ "Confidence" SG_ 1279 UI_energyLossTotal_epa 0;
BA_ "Confidence" SG_ 1279 UI_energyLossDriving_epa 0;
BA_ "Confidence" SG_ 1279 UI_energyLossClimate_epa 0;
BA_ "Confidence" SG_ 1279 UI_energyLossBattCond_epa 0;
BA_ "Confidence" SG_ 1279 UI_energyLossElevation_epa 0;
BA_ "Confidence" SG_ 1279 UI_energyLossAcc_epa 0;
BA_ "Confidence" SG_ 1279 UI_energyLossTotalSinceCharge_ep 0;
BA_ "SystemSignalLongSymbol" SG_ 1279 UI_energyLossTotalSinceCharge_ep "UI_energyLossTotalSinceCharge_epa";
BA_ "Confidence" SG_ 1279 UI_energyLossDrivingSinceCharge_ 0;
BA_ "SystemSignalLongSymbol" SG_ 1279 UI_energyLossDrivingSinceCharge_ "UI_energyLossDrivingSinceCharge_epa";
BA_ "Confidence" SG_ 1279 UI_energyLossClimateSinceCharge_ 0;
BA_ "SystemSignalLongSymbol" SG_ 1279 UI_energyLossClimateSinceCharge_ "UI_energyLossClimateSinceCharge_epa";
BA_ "Confidence" SG_ 1279 UI_energyLossBattCondSinceCharge 0;
BA_ "SystemSignalLongSymbol" SG_ 1279 UI_energyLossBattCondSinceCharge "UI_energyLossBattCondSinceCharge_epa";
BA_ "Confidence" SG_ 1279 UI_energyLossElevationSinceCharg 0;
BA_ "SystemSignalLongSymbol" SG_ 1279 UI_energyLossElevationSinceCharg "UI_energyLossElevationSinceCharge_epa";
BA_ "Confidence" SG_ 1279 UI_energyLossAccSinceCharge_epa 0;
BA_ "Confidence" SG_ 1279 UI_energyLossTotalSinceTripStart 0;
BA_ "Confidence" SG_ 1279 UI_energyLossDrivingSinceTripSta 0;
BA_ "SystemSignalLongSymbol" SG_ 1279 UI_energyLossDrivingSinceTripSta "UI_energyLossDrivingSinceTripStart";
BA_ "Confidence" SG_ 1279 UI_energyLossClimateSinceTripSta 0;
BA_ "SystemSignalLongSymbol" SG_ 1279 UI_energyLossClimateSinceTripSta "UI_energyLossClimateSinceTripStart";
BA_ "Confidence" SG_ 1279 UI_energyLossBattCondSinceTripSt 0;
BA_ "SystemSignalLongSymbol" SG_ 1279 UI_energyLossBattCondSinceTripSt "UI_energyLossBattCondSinceTripStart";
BA_ "Confidence" SG_ 1279 UI_energyLossElevationSinceTripS 0;
BA_ "SystemSignalLongSymbol" SG_ 1279 UI_energyLossElevationSinceTripS "UI_energyLossElevationSinceTripStart";
BA_ "Confidence" SG_ 1279 UI_energyLossAccSinceTripStart 0;
BA_ "Confidence" SG_ 1279 UI_energyDeltaTotal_epa 0;
BA_ "Confidence" SG_ 1279 UI_energyDeltaDriving_epa 0;
BA_ "Confidence" SG_ 1279 UI_energyDeltaClimate_epa 0;
BA_ "Confidence" SG_ 1279 UI_energyDeltaBattCond_epa 0;
BA_ "Confidence" SG_ 1279 UI_energyDeltaElevation_epa 0;
BA_ "Confidence" SG_ 1279 UI_energyDeltaAcc_epa 0;
BA_ "Confidence" SG_ 1279 UI_uiDeltaOffsetTotal_epa 0;
BA_ "Confidence" SG_ 1279 UI_uiDeltaOffsetDriving_epa 0;
BA_ "Confidence" SG_ 1279 UI_uiDeltaOffsetClimate_epa 0;
BA_ "Confidence" SG_ 1279 UI_uiDeltaOffsetBattCond_epa 0;
BA_ "Confidence" SG_ 1279 UI_uiDeltaOffsetElevation_epa 0;
BA_ "Confidence" SG_ 1279 UI_uiDeltaOffsetAcc_epa 0;
BA_ "Confidence" SG_ 1279 UI_rawToUiEnergyRatio_epa 0;
BA_ "Confidence" SG_ 1279 UI_driveDistance_epa 0;
BA_ "Confidence" SG_ 1279 UI_energyDeltaTotalSinceCharge_e 0;
BA_ "SystemSignalLongSymbol" SG_ 1279 UI_energyDeltaTotalSinceCharge_e "UI_energyDeltaTotalSinceCharge_epa";
BA_ "Confidence" SG_ 1279 UI_energyDeltaDrivingSinceCharge 0;
BA_ "SystemSignalLongSymbol" SG_ 1279 UI_energyDeltaDrivingSinceCharge "UI_energyDeltaDrivingSinceCharge_epa";
BA_ "Confidence" SG_ 1279 UI_energyDeltaClimateSinceCharge 0;
BA_ "SystemSignalLongSymbol" SG_ 1279 UI_energyDeltaClimateSinceCharge "UI_energyDeltaClimateSinceCharge_epa";
BA_ "Confidence" SG_ 1279 UI_energyDeltaBattCondSinceCharg 0;
BA_ "SystemSignalLongSymbol" SG_ 1279 UI_energyDeltaBattCondSinceCharg "UI_energyDeltaBattCondSinceCharge_epa";
BA_ "Confidence" SG_ 1279 UI_energyDeltaElevationSinceChar 0;
BA_ "SystemSignalLongSymbol" SG_ 1279 UI_energyDeltaElevationSinceChar "UI_energyDeltaElevationSinceCharge_epa";
BA_ "Confidence" SG_ 1279 UI_energyDeltaAccSinceCharge_epa 0;
BA_ "Confidence" SG_ 1279 UI_uiDeltaOffsetTotalSinceCharge 0;
BA_ "SystemSignalLongSymbol" SG_ 1279 UI_uiDeltaOffsetTotalSinceCharge "UI_uiDeltaOffsetTotalSinceCharge_epa";
BA_ "Confidence" SG_ 1279 UI_uiDeltaOffsetDrivingSinceChar 0;
BA_ "SystemSignalLongSymbol" SG_ 1279 UI_uiDeltaOffsetDrivingSinceChar "UI_uiDeltaOffsetDrivingSinceCharge_epa";
BA_ "Confidence" SG_ 1279 UI_uiDeltaOffsetClimateSinceChar 0;
BA_ "SystemSignalLongSymbol" SG_ 1279 UI_uiDeltaOffsetClimateSinceChar "UI_uiDeltaOffsetClimateSinceCharge_epa";
BA_ "Confidence" SG_ 1279 UI_uiDeltaOffsetBattCondSinceCha 0;
BA_ "SystemSignalLongSymbol" SG_ 1279 UI_uiDeltaOffsetBattCondSinceCha "UI_uiDeltaOffsetBattCondSinceCharge_epa";
BA_ "Confidence" SG_ 1279 UI_uiDeltaOffsetElevationSinceCh 0;
BA_ "SystemSignalLongSymbol" SG_ 1279 UI_uiDeltaOffsetElevationSinceCh "UI_uiDeltaOffsetElevationSinceCharge_epa";
BA_ "Confidence" SG_ 1279 UI_uiDeltaOffsetAccSinceCharge_e 0;
BA_ "SystemSignalLongSymbol" SG_ 1279 UI_uiDeltaOffsetAccSinceCharge_e "UI_uiDeltaOffsetAccSinceCharge_epa";
BA_ "Confidence" SG_ 1279 UI_rawToUiEnergyRatioSinceCharge 0;
BA_ "SystemSignalLongSymbol" SG_ 1279 UI_rawToUiEnergyRatioSinceCharge "UI_rawToUiEnergyRatioSinceCharge_epa";
BA_ "Confidence" SG_ 1279 UI_driveDistanceSinceCharge_epa 0;
BA_ "Confidence" SG_ 1279 UI_energyDeltaTotalSinceTripStar 0;
BA_ "SystemSignalLongSymbol" SG_ 1279 UI_energyDeltaTotalSinceTripStar "UI_energyDeltaTotalSinceTripStart";
BA_ "Confidence" SG_ 1279 UI_energyDeltaDrivingSinceTripSt 0;
BA_ "SystemSignalLongSymbol" SG_ 1279 UI_energyDeltaDrivingSinceTripSt "UI_energyDeltaDrivingSinceTripStart";
BA_ "Confidence" SG_ 1279 UI_energyDeltaClimateSinceTripSt 0;
BA_ "SystemSignalLongSymbol" SG_ 1279 UI_energyDeltaClimateSinceTripSt "UI_energyDeltaClimateSinceTripStart";
BA_ "Confidence" SG_ 1279 UI_energyDeltaBattCondSinceTripS 0;
BA_ "SystemSignalLongSymbol" SG_ 1279 UI_energyDeltaBattCondSinceTripS "UI_energyDeltaBattCondSinceTripStart";
BA_ "Confidence" SG_ 1279 UI_energyDeltaElevationSinceTrip 0;
BA_ "SystemSignalLongSymbol" SG_ 1279 UI_energyDeltaElevationSinceTrip "UI_energyDeltaElevationSinceTripStart";
BA_ "Confidence" SG_ 1279 UI_energyDeltaAccSinceTripStart 0;
BA_ "Confidence" SG_ 1279 UI_uiDeltaOffsetTotalSinceTripSt 0;
BA_ "SystemSignalLongSymbol" SG_ 1279 UI_uiDeltaOffsetTotalSinceTripSt "UI_uiDeltaOffsetTotalSinceTripStart";
BA_ "Confidence" SG_ 1279 UI_uiDeltaOffsetDrivingSinceTrip 0;
BA_ "SystemSignalLongSymbol" SG_ 1279 UI_uiDeltaOffsetDrivingSinceTrip "UI_uiDeltaOffsetDrivingSinceTripStart";
BA_ "Confidence" SG_ 1279 UI_uiDeltaOffsetClimateSinceTrip 0;
BA_ "SystemSignalLongSymbol" SG_ 1279 UI_uiDeltaOffsetClimateSinceTrip "UI_uiDeltaOffsetClimateSinceTripStart";
BA_ "Confidence" SG_ 1279 UI_uiDeltaOffsetBattCondSinceTri 0;
BA_ "SystemSignalLongSymbol" SG_ 1279 UI_uiDeltaOffsetBattCondSinceTri "UI_uiDeltaOffsetBattCondSinceTripStart";
BA_ "Confidence" SG_ 1279 UI_uiDeltaOffsetElevationSinceTr 0;
BA_ "SystemSignalLongSymbol" SG_ 1279 UI_uiDeltaOffsetElevationSinceTr "UI_uiDeltaOffsetElevationSinceTripStart";
BA_ "Confidence" SG_ 1279 UI_uiDeltaOffsetAccSinceTripStar 0;
BA_ "SystemSignalLongSymbol" SG_ 1279 UI_uiDeltaOffsetAccSinceTripStar "UI_uiDeltaOffsetAccSinceTripStart";
BA_ "Confidence" SG_ 1279 UI_rawToUiEnergyRatioSinceTripSt 0;
BA_ "SystemSignalLongSymbol" SG_ 1279 UI_rawToUiEnergyRatioSinceTripSt "UI_rawToUiEnergyRatioSinceTripStart";
BA_ "Confidence" SG_ 1279 UI_driveDistanceSinceTripStart 0;
BA_ "Confidence" SG_ 1279 UI_trailerMass 0;
BA_ "Confidence" SG_ 1139 UI_nmKeepAwakeReason 1;
BA_ "GenSigSNA" SG_ 1139 UI_nmKeepAwakeReason "0";
BA_ "Confidence" SG_ 1139 UI_wakeupTime 0;
BA_ "Confidence" SG_ 820 UI_pedalMap 0;
BA_ "Confidence" SG_ 820 UI_enableRegenBackfill 0;
BA_ "Confidence" SG_ 820 UI_regenTorqueMax 0;
BA_ "Confidence" SG_ 820 UI_limitMode 0;
BA_ "Confidence" SG_ 820 UI_motorOnMode 0;
BA_ "Confidence" SG_ 820 UI_stoppingMode 1;
BA_ "Confidence" SG_ 820 UI_speedLimit 1;
BA_ "GenSigSNA" SG_ 820 UI_speedLimit "511";
BA_ "Confidence" SG_ 820 UI_enableSmartShift 1;
BA_ "Confidence" SG_ 820 UI_navVehParallelToRdCanContinue 1;
BA_ "GenSigSNA" SG_ 820 UI_navVehParallelToRdCanContinue "0";
BA_ "Confidence" SG_ 563 UI_gearRequest 0;
BA_ "GenSigSNA" SG_ 563 UI_gearRequest "0";
BA_ "Confidence" SG_ 563 UI_fullScreenMode 1;
BA_ "Confidence" SG_ 563 UI_gearStripShowing 1;
BA_ "Confidence" SG_ 563 UI_gearStripForceShow 1;
BA_ "Confidence" SG_ 563 UI_autoParkAvailable 1;
BA_ "Confidence" SG_ 563 UI_gearStripSuppressActive 1;
BA_ "Confidence" SG_ 563 UI_gearNeutralPressed 1;
BA_ "Confidence" SG_ 699 UI_centerDisplayRunning 0;
BA_ "Confidence" SG_ 699 UI_centerDisplayPowerOn 0;
BA_ "Confidence" SG_ 991 UI_userActivity 0;
BA_ "Confidence" SG_ 991 UI_activeTouchPoints 0;
BA_ "Confidence" SG_ 991 UI_linkState 0;
BA_ "Confidence" SG_ 991 UI_autopilotSentryRequest 0;
BA_ "Confidence" SG_ 991 UI_mobileAppConnected 0;
BA_ "Confidence" SG_ 991 UI_autoshiftDRState 0;
BA_ "Confidence" SG_ 991 UI_wifiBtModuleType 0;
BA_ "Confidence" SG_ 991 UI_selfParkState 0;
BA_ "GenSigSNA" SG_ 991 UI_selfParkState "255";
BA_ "Confidence" SG_ 991 UI_summonDeviceIndex 0;
BA_ "Confidence" SG_ 661 UI_systemMonitorIndex 1;
BA_ "Confidence" SG_ 661 UI_SystemMemUsage 0;
BA_ "Confidence" SG_ 661 UI_QtCarMemUsage 0;
BA_ "Confidence" SG_ 661 UI_QtCarCPUUsage 0;
BA_ "Confidence" SG_ 661 UI_SystemCPUUsage 0;
BA_ "Confidence" SG_ 787 UI_trackModeRequest 0;
BA_ "Confidence" SG_ 787 UI_trackDrivePowerAvailability 0;
BA_ "Confidence" SG_ 130 UI_tripPlanningActive 0;
BA_ "Confidence" SG_ 130 UI_navToSupercharger 0;
BA_ "Confidence" SG_ 130 UI_navFastchargerType 0;
BA_ "Confidence" SG_ 130 UI_battPreconditionOnNavState 0;
BA_ "Confidence" SG_ 130 UI_requestActiveBatteryHeating 0;
BA_ "Confidence" SG_ 130 UI_battPreconditionOnNavPowerReq 0;
BA_ "GenSigSNA" SG_ 130 UI_battPreconditionOnNavPowerReq "127";
BA_ "Confidence" SG_ 130 UI_battPreconditionOnNavTargetT 0;
BA_ "GenSigSNA" SG_ 130 UI_battPreconditionOnNavTargetT "255";
BA_ "Confidence" SG_ 130 UI_energyAtDestination 0;
BA_ "GenSigSNA" SG_ 130 UI_energyAtDestination "32768";
BA_ "Confidence" SG_ 139 UI_maxSpeedToReachDestination 0;
BA_ "GenSigSNA" SG_ 139 UI_maxSpeedToReachDestination "65535";
BA_ "Confidence" SG_ 139 UI_timeToDestination 0;
BA_ "GenSigSNA" SG_ 139 UI_timeToDestination "65535";
BA_ "Confidence" SG_ 1173 UI_predictedEnergy 0;
BA_ "GenSigSNA" SG_ 1173 UI_predictedEnergy "32768";
BA_ "Confidence" SG_ 1173 UI_hindsightEnergy 0;
BA_ "GenSigSNA" SG_ 1173 UI_hindsightEnergy "32768";
BA_ "Confidence" SG_ 947 UI_gloveboxRequest 0;
BA_ "Confidence" SG_ 947 UI_trunkRequest 0;
BA_ "Confidence" SG_ 947 UI_PINToDriveEnabled 0;
BA_ "Confidence" SG_ 947 UI_PINToDrivePassed 0;
BA_ "Confidence" SG_ 947 UI_disableMirrorAutoDim 0;
BA_ "Confidence" SG_ 947 UI_lightSwitch 0;
BA_ "GenSigSNA" SG_ 947 UI_lightSwitch "4";
BA_ "Confidence" SG_ 947 UI_readyToAddKey 0;
BA_ "Confidence" SG_ 947 UI_alarmTriggerRequest 0;
BA_ "Confidence" SG_ 947 UI_displayOnForUser 0;
BA_ "Confidence" SG_ 947 UI_BLEPushNotificationRequest 0;
BA_ "Confidence" SG_ 947 UI_keepAutopilotAwake 0;
BA_ "Confidence" SG_ 947 UI_batteryPreconditioningRequest 0;
BA_ "Confidence" SG_ 947 UI_autopilotPowerStateRequest 0;
BA_ "Confidence" SG_ 947 UI_autoRollWindowsOnLockEnable 0;
BA_ "Confidence" SG_ 947 UI_steeringWheelHeatReq 0;
BA_ "Confidence" SG_ 947 UI_disableHorn 0;
BA_ "Confidence" SG_ 947 UI_frontLeftSeatFanReq 0;
BA_ "Confidence" SG_ 947 UI_frontRightSeatAutoClimateReq 0;
BA_ "Confidence" SG_ 947 UI_frontRightSeatFanReq 0;
BA_ "Confidence" SG_ 947 UI_frontLeftSeatAutoClimateReq 0;
BA_ "Confidence" SG_ 947 UI_wiperHeaterReq 0;
BA_ "Confidence" SG_ 947 UI_silentAlarm 0;
VAL_ 522 HVP_packContNegativeState 7 "CONTACTOR_STATE_WELDED" 6 "CONTACTOR_STATE_ECONOMIZED" 5 "CONTACTOR_STATE_OPENING" 4 "CONTACTOR_STATE_PULLED_IN" 3 "CONTACTOR_STATE_BLOCKED" 2 "CONTACTOR_STATE_PRECHARGE" 1 "CONTACTOR_STATE_OPEN" 0 "CONTACTOR_STATE_SNA" ;
VAL_ 522 HVP_packContPositiveState 7 "CONTACTOR_STATE_WELDED" 6 "CONTACTOR_STATE_ECONOMIZED" 5 "CONTACTOR_STATE_OPENING" 4 "CONTACTOR_STATE_PULLED_IN" 3 "CONTACTOR_STATE_BLOCKED" 2 "CONTACTOR_STATE_PRECHARGE" 1 "CONTACTOR_STATE_OPEN" 0 "CONTACTOR_STATE_SNA" ;
VAL_ 522 HVP_packContactorSetState 9 "CONTACTOR_SET_STATE_NEGATIVE_CLOSED" 8 "CONTACTOR_SET_STATE_POSITIVE_CLOSED" 7 "CONTACTOR_SET_STATE_WELDED" 6 "CONTACTOR_SET_STATE_PARTIAL_WELD" 5 "CONTACTOR_SET_STATE_CLOSED" 4 "CONTACTOR_SET_STATE_OPENING" 3 "CONTACTOR_SET_STATE_BLOCKED" 2 "CONTACTOR_SET_STATE_CLOSING" 1 "CONTACTOR_SET_STATE_OPEN" 0 "CONTACTOR_SET_STATE_SNA" ;
VAL_ 522 HVP_fcContNegativeState 7 "CONTACTOR_STATE_WELDED" 6 "CONTACTOR_STATE_ECONOMIZED" 5 "CONTACTOR_STATE_OPENING" 4 "CONTACTOR_STATE_PULLED_IN" 3 "CONTACTOR_STATE_BLOCKED" 2 "CONTACTOR_STATE_PRECHARGE" 1 "CONTACTOR_STATE_OPEN" 0 "CONTACTOR_STATE_SNA" ;
VAL_ 522 HVP_fcContPositiveState 7 "CONTACTOR_STATE_WELDED" 6 "CONTACTOR_STATE_ECONOMIZED" 5 "CONTACTOR_STATE_OPENING" 4 "CONTACTOR_STATE_PULLED_IN" 3 "CONTACTOR_STATE_BLOCKED" 2 "CONTACTOR_STATE_PRECHARGE" 1 "CONTACTOR_STATE_OPEN" 0 "CONTACTOR_STATE_SNA" ;
VAL_ 522 HVP_fcContactorSetState 9 "CONTACTOR_SET_STATE_NEGATIVE_CLOSED" 8 "CONTACTOR_SET_STATE_POSITIVE_CLOSED" 7 "CONTACTOR_SET_STATE_WELDED" 6 "CONTACTOR_SET_STATE_PARTIAL_WELD" 5 "CONTACTOR_SET_STATE_CLOSED" 4 "CONTACTOR_SET_STATE_OPENING" 3 "CONTACTOR_SET_STATE_BLOCKED" 2 "CONTACTOR_SET_STATE_CLOSING" 1 "CONTACTOR_SET_STATE_OPEN" 0 "CONTACTOR_SET_STATE_SNA" ;
VAL_ 522 HVP_fcCtrsRequestStatus 2 "REQUEST_COMPLETED" 1 "REQUEST_ACTIVE" 0 "REQUEST_NOT_ACTIVE" ;
VAL_ 522 HVP_packCtrsRequestStatus 2 "REQUEST_COMPLETED" 1 "REQUEST_ACTIVE" 0 "REQUEST_NOT_ACTIVE" ;
VAL_ 522 HVP_hvilDiag 14 "SNA" 13 "PM_OPEN_FAULT" 12 "DI_OPEN_FAULT" 11 "PM_STATUS_MISSING_FAULT" 10 "DI_STATUS_MISSING_FAULT" 9 "VEHICLE_OR_PENTHOUSE_LID_OPEN_FAULT" 8 "NO_12V_SUPPLY" 7 "VEHICLE_NODE_FAULT" 6 "UNKNOWN_LOCATION_OPEN_FAULT" 5 "PENTHOUSE_LID_OPEN_FAULT" 4 "VEHICLE_OPEN_FAULT" 3 "INTERNAL_OPEN_FAULT" 2 "CURRENT_SOURCE_OR_GROUND_LEAK_FAULT" 1 "OK" 0 "UNKNOWN" ;
VAL_ 522 HVP_fcLinkAllowedToEnergize 2 "FC_LINK_ENERGY_DC" 1 "FC_LINK_ENERGY_AC" 0 "FC_LINK_ENERGY_NONE" ;
VAL_ 1962 HVP_debugMessageMultiplexer 12 "Mux12" 11 "Mux11" 10 "Mux10" 9 "Mux9" 8 "Mux8" 7 "Mux7" 6 "Mux6" 5 "Mux5" 4 "Mux4" 3 "Mux3" 2 "Mux2" 1 "Mux1" 0 "Mux0" ;
VAL_ 1962 HVP_ecuLogUploadRequest 3 "REQUEST_PRIORITY_3" 2 "REQUEST_PRIORITY_2" 1 "REQUEST_PRIORITY_1" 0 "REQUEST_PRIORITY_NONE" ;
VAL_ 2025 ICR_occupancy1LRaw 3 "SBRStatus_SEAT_SNA" 2 "SBRStatus_SEAT_FAULTED" 1 "SBRStatus_SEAT_OCCUPIED" 0 "SBRStatus_SEAT_UNOCCUPIED" ;
VAL_ 2025 ICR_occupancy1RRaw 3 "SBRStatus_SEAT_SNA" 2 "SBRStatus_SEAT_FAULTED" 1 "SBRStatus_SEAT_OCCUPIED" 0 "SBRStatus_SEAT_UNOCCUPIED" ;
VAL_ 2025 ICR_userPresenceFilt 3 "SBRStatus_SEAT_SNA" 2 "SBRStatus_SEAT_FAULTED" 1 "SBRStatus_SEAT_OCCUPIED" 0 "SBRStatus_SEAT_UNOCCUPIED" ;
VAL_ 2025 ICR_userPresenceRaw 3 "SBRStatus_SEAT_SNA" 2 "SBRStatus_SEAT_FAULTED" 1 "SBRStatus_SEAT_OCCUPIED" 0 "SBRStatus_SEAT_UNOCCUPIED" ;
VAL_ 2025 ICR_occupancy1LFilt 3 "SBRStatus_SEAT_SNA" 2 "SBRStatus_SEAT_FAULTED" 1 "SBRStatus_SEAT_OCCUPIED" 0 "SBRStatus_SEAT_UNOCCUPIED" ;
VAL_ 2025 ICR_occupancy1RFilt 3 "SBRStatus_SEAT_SNA" 2 "SBRStatus_SEAT_FAULTED" 1 "SBRStatus_SEAT_OCCUPIED" 0 "SBRStatus_SEAT_UNOCCUPIED" ;
VAL_ 2025 ICR_occupancy2LFilt 3 "SBRStatus_SEAT_SNA" 2 "SBRStatus_SEAT_FAULTED" 1 "SBRStatus_SEAT_OCCUPIED" 0 "SBRStatus_SEAT_UNOCCUPIED" ;
VAL_ 2025 ICR_occupancy2CFilt 3 "SBRStatus_SEAT_SNA" 2 "SBRStatus_SEAT_FAULTED" 1 "SBRStatus_SEAT_OCCUPIED" 0 "SBRStatus_SEAT_UNOCCUPIED" ;
VAL_ 2025 ICR_occupancy2RFilt 3 "SBRStatus_SEAT_SNA" 2 "SBRStatus_SEAT_FAULTED" 1 "SBRStatus_SEAT_OCCUPIED" 0 "SBRStatus_SEAT_UNOCCUPIED" ;
VAL_ 2025 ICR_classification1LFilt 4 "OCCUPANT_CLASSIFICATION_OCCUPIED_ALLOW" 3 "OCCUPANT_CLASSIFICATION_OCCUPIED_INHIBIT" 2 "OCCUPANT_CLASSIFICATION_EMPTY" 1 "OCCUPANT_CLASSIFICATION_INIT" 0 "OCCUPANT_CLASSIFICATION_SNA" ;
VAL_ 2025 ICR_classification1RqF 1 "OCCUPANT_CLASSIFICATION_NOT_FAULTED" 0 "OCCUPANT_CLASSIFICATION_FAULTED" ;
VAL_ 2025 ICR_occupancy1RFiltExp 3 "SBRStatus_SEAT_SNA" 2 "SBRStatus_SEAT_FAULTED" 1 "SBRStatus_SEAT_OCCUPIED" 0 "SBRStatus_SEAT_UNOCCUPIED" ;
VAL_ 670 ICR_userPresenceMLOutput 255 "SNA" ;
VAL_ 670 ICR_classification1RFilt 4 "OCCUPANT_CLASSIFICATION_OCCUPIED_ALLOW" 3 "OCCUPANT_CLASSIFICATION_OCCUPIED_INHIBIT" 2 "OCCUPANT_CLASSIFICATION_EMPTY" 1 "OCCUPANT_CLASSIFICATION_INIT" 0 "OCCUPANT_CLASSIFICATION_SNA" ;
VAL_ 670 ICR_classification1LRaw 4 "OCCUPANT_CLASSIFICATION_OCCUPIED_ALLOW" 3 "OCCUPANT_CLASSIFICATION_OCCUPIED_INHIBIT" 2 "OCCUPANT_CLASSIFICATION_EMPTY" 1 "OCCUPANT_CLASSIFICATION_INIT" 0 "OCCUPANT_CLASSIFICATION_SNA" ;
VAL_ 670 ICR_classification1RRaw 4 "OCCUPANT_CLASSIFICATION_OCCUPIED_ALLOW" 3 "OCCUPANT_CLASSIFICATION_OCCUPIED_INHIBIT" 2 "OCCUPANT_CLASSIFICATION_EMPTY" 1 "OCCUPANT_CLASSIFICATION_INIT" 0 "OCCUPANT_CLASSIFICATION_SNA" ;
VAL_ 670 ICR_classification1LMLOutput 255 "SNA" ;
VAL_ 670 ICR_classification1RMLOutput 255 "SNA" ;
VAL_ 2023 ICR_sensorMode 15 "ICR_SENSOR_INTERFACE_MODE_ERROR" 7 "ICR_SENSOR_INTERFACE_MODE_LPM_TEST" 6 "ICR_SENSOR_INTERFACE_MODE_OCCUPANCY_DETECTION" 5 "ICR_SENSOR_INTERFACE_MODE_HPM_TEST" 4 "ICR_SENSOR_INTERFACE_MODE_CALIBRATION" 3 "ICR_SENSOR_INTERFACE_MODE_CW" 2 "ICR_SENSOR_MODE_END_OF_LINE_TEST" 1 "ICR_SENSOR_MODE_INTRUSTION" 0 "ICR_SENSOR_MODE_SENSOR_STOPPED" ;
VAL_ 2023 ICR_blocked 2 "ICR_BLOCKED_TRUE" 1 "ICR_BLOCKED_FALSE" 0 "ICR_BLOCKED_SNA" ;
VAL_ 2023 ICR_algoVersion 37 "ICR_ALGO_VERSION_FUTURE_RELEASE_37" 36 "ICR_ALGO_VERSION_v06112025" 35 "ICR_ALGO_VERSION_v04232025" 34 "ICR_ALGO_VERSION_v03192025" 33 "ICR_ALGO_VERSION_v02142025" 32 "ICR_ALGO_VERSION_v01222025" 31 "ICR_ALGO_VERSION_v10072024" 30 "ICR_ALGO_VERSION_v08282024" 29 "ICR_ALGO_VERSION_v07172024" 28 "ICR_ALGO_VERSION_v06122024" 27 "ICR_ALGO_VERSION_v04242024" 26 "ICR_ALGO_VERSION_v03142024" 25 "ICR_ALGO_VERSION_v01312024" 24 "ICR_ALGO_VERSION_v12192023" 23 "ICR_ALGO_VERSION_v10252023" 22 "ICR_ALGO_VERSION_v10112023" 21 "ICR_ALGO_VERSION_v09222023" 20 "ICR_ALGO_VERSION_V08302023" 19 "ICR_ALGO_VERSION_V07172023" 18 "ICR_ALGO_VERSION_V06152023" 17 "ICR_ALGO_VERSION_V06072023" 16 "ICR_ALGO_VERSION_V05192023" 15 "ICR_ALGO_VERSION_V04262023" 14 "ICR_ALGO_VERSION_V1222" 13 "ICR_ALGO_VERSION_V1125" 12 "ICR_ALGO_VERSION_V1118" 11 "ICR_ALGO_VERSION_V1103" 10 "ICR_ALGO_VERSION_V1013" 9 "ICR_ALGO_VERSION_V1006" 8 "ICR_ALGO_VERSION_V927" 7 "ICR_ALGO_VERSION_V902" 6 "ICR_ALGO_VERSION_V826" 5 "ICR_ALGO_VERSION_V803" 4 "ICR_ALGO_VERSION_V715" 3 "ICR_ALGO_VERSION_V711" 2 "ICR_ALGO_VERSION_V204" 1 "ICR_ALGO_VERSION_EXPERIMENTAL" 0 "ICR_ALGO_VERSION_NONE" ;
VAL_ 2023 ICR_intrusionStatus 2 "INSTRUSION_STATUS_INTRUSION_DETECTED" 1 "INSTRUSION_STATUS_NONE" 0 "INSTRUSION_STATUS_UNKNOWN" ;
VAL_ 828 IDB_infoIndex 255 "END" 31 "SUBCOMPONENT_GITHASH" 30 "PACKAGE_SN_8_14" 29 "PACKAGE_SN_1_7" 27 "PACKAGE_PN_15_20" 26 "PACKAGE_PN_8_14" 25 "PACKAGE_PN_1_7" 23 "SUBCOMPONENT2" 22 "VARIANTCRC" 20 "UDS_PROTOCOL_BOOTCRC" 19 "VERSION_DEPRECATED" 18 "BOOTLOADER_GITHASH" 17 "APP_GITHASH" 16 "SUBCOMPONENT" 15 "BOOTLOADER_CRC" 14 "BOOTLOADER_SVN" 13 "APP_CRC" 11 "PCBAID_ASSYID_USAGEID" 10 "BUILD_HWID_COMPONENTID" 9 "DEPRECATED_9" 8 "DEPRECATED_8" 7 "DEPRECATED_7" 6 "DEPRECATED_6" 5 "DEPRECATED_5" 4 "DEPRECATED_4" 3 "DEPRECATED_3" 2 "DEPRECATED_2" 1 "DEPRECATED_1" 0 "DEPRECATED_0" ;
VAL_ 516 PCS_chgMainState 9 "PCS_CHG_STATE_CLEAR_FAULTS" 8 "PCS_CHG_STATE_FAULTED" 7 "PCS_CHG_STATE_SHUTDOWN" 6 "PCS_CHG_STATE_ENABLE" 5 "PCS_CHG_STATE_SYSTEM_CONFIG" 4 "PCS_CHG_STATE_QUALIFY_LINE_CONFIG" 3 "PCS_CHG_STATE_WAIT_FOR_LINE_VOLTAGE" 2 "PCS_CHG_STATE_STARTUP" 1 "PCS_CHG_STATE_IDLE" 0 "PCS_CHG_STATE_INIT" ;
VAL_ 516 PCS_gridConfig 3 "GRID_CONFIG_THREE_PHASE_DELTA" 2 "GRID_CONFIG_THREE_PHASE" 1 "GRID_CONFIG_SINGLE_PHASE" 0 "GRID_CONFIG_SNA" ;
VAL_ 516 PCS_chgMaxAcPowerAvailable 255 "SNA" ;
VAL_ 516 PCS_hwVariantType 3 "PCS_HW_VARIANT_TYPE_SNA" 2 "PCS_THREE_PHASES_VARIANT" 1 "PCS_32A_SINGLE_PHASE_VARIANT" 0 "PCS_48A_SINGLE_PHASE_VARIANT" ;
VAL_ 548 PCS_dcdcPrechargeStatus 3 "PCS_DCDC_PRECHARGE_IMPEDANCE_CHECK" 2 "PCS_DCDC_PRECHARGE_FAULTED" 1 "PCS_DCDC_PRECHARGE_ACTIVE" 0 "PCS_DCDC_PRECHARGE_IDLE" ;
VAL_ 548 PCS_dcdcLvSupportStatus 2 "PCS_DCDC_LV_SUPPORT_FAULTED" 1 "PCS_DCDC_LV_SUPPORT_ACTIVE" 0 "PCS_DCDC_LV_SUPPORT_IDLE" ;
VAL_ 548 PCS_dcdcHvBusDischargeStatus 2 "PCS_DCDC_DIS_HVBUS_FAULTED" 1 "PCS_DCDC_DIS_HVBUS_ACTIVE" 0 "PCS_DCDC_DIS_HVBUS_IDLE" ;
VAL_ 548 PCS_dcdcSubState 18 "DCDC_SUBSTATE_NUM" 17 "DCDC_SUBSTATE_FAULTED" 16 "DCDC_SUBSTATE_CLEAR_FAULTS" 15 "DCDC_SUBSTATE_PCHG_FAULTED" 14 "DCDC_SUBSTATE_DIS_HVBUS_FAULTED" 13 "DCDC_SUBSTATE_LV_SUPPORT_FAULTED" 12 "DCDC_SUBSTATE_SHUTDOWN" 11 "DCDC_SUBSTATE_PCHG_FLT_FAST_DIS_HVBUS" 10 "DCDC_SUBSTATE_PCHG_ACTIVE" 9 "DCDC_SUBSTATE_PCHG_DI_RECOVERY_WAIT" 8 "DCDC_SUBSTATE_PCHG_DWELL_WAIT" 7 "DCDC_SUBSTATE_PCHG_DWELL_CHARGE" 6 "DCDC_SUBSTATE_PCHG_SLOW_DIS_HVBUS" 5 "DCDC_SUBSTATE_PCHG_FAST_DIS_HVBUS" 4 "DCDC_SUBSTATE_SLOW_DIS_HVBUS" 3 "DCDC_SUBSTATE_FAST_DIS_HVBUS" 2 "DCDC_SUBSTATE_LV_SUPPORT_ACTIVE" 1 "DCDC_SUBSTATE_STANDBY" 0 "DCDC_SUBSTATE_PWR_UP_INIT" ;
VAL_ 548 PCS_ecuLogUploadRequest 3 "REQUEST_PRIORITY_3" 2 "REQUEST_PRIORITY_2" 1 "REQUEST_PRIORITY_1" 0 "REQUEST_PRIORITY_NONE" ;
VAL_ 548 PCS_dcdcInitialPrechargeSubState 18 "DCDC_SUBSTATE_NUM" 17 "DCDC_SUBSTATE_FAULTED" 16 "DCDC_SUBSTATE_CLEAR_FAULTS" 15 "DCDC_SUBSTATE_PCHG_FAULTED" 14 "DCDC_SUBSTATE_DIS_HVBUS_FAULTED" 13 "DCDC_SUBSTATE_LV_SUPPORT_FAULTED" 12 "DCDC_SUBSTATE_SHUTDOWN" 11 "DCDC_SUBSTATE_PCHG_FLT_FAST_DIS_HVBUS" 10 "DCDC_SUBSTATE_PCHG_ACTIVE" 9 "DCDC_SUBSTATE_PCHG_DI_RECOVERY_WAIT" 8 "DCDC_SUBSTATE_PCHG_DWELL_WAIT" 7 "DCDC_SUBSTATE_PCHG_DWELL_CHARGE" 6 "DCDC_SUBSTATE_PCHG_SLOW_DIS_HVBUS" 5 "DCDC_SUBSTATE_PCHG_FAST_DIS_HVBUS" 4 "DCDC_SUBSTATE_SLOW_DIS_HVBUS" 3 "DCDC_SUBSTATE_FAST_DIS_HVBUS" 2 "DCDC_SUBSTATE_LV_SUPPORT_ACTIVE" 1 "DCDC_SUBSTATE_STANDBY" 0 "DCDC_SUBSTATE_PWR_UP_INIT" ;
VAL_ 708 PCS_logMessageSelect 27 "NUM_MSGS" 26 "PROCESSOR_DIE_ID" 25 "DCDC_IMPEDANCE_EST" 24 "DCDC_HVBUS_PCHG_DATA" 23 "CHG_MACHINEMODEL" 22 "DCDC_STATISTICS" 21 "CHG_LINE_OFFSET" 20 "CHG_NO_FLOW" 19 "DCDC_5" 18 "DCDC_4" 17 "DLOG_4" 16 "DLOG_3" 15 "DLOG_2" 14 "DLOG_1" 13 "CHG_4" 12 "PHC_2" 11 "PHB_2" 10 "PHA_2" 9 "SYSTEM_1" 8 "DCDC_3" 7 "DCDC_2" 6 "DCDC_1" 5 "CHG_3" 4 "CHG_2" 3 "CHG_1" 2 "PHC_1" 1 "PHB_1" 0 "PHA_1" ;
VAL_ 708 PCS_chgPhAInputCurrentLimitReaso 5 "PCS_IAC_LIMITED_BY_PHASE_MACHINE_MODEL" 4 "PCS_IAC_LIMITED_BY_PHASE_THERMAL_LIMIT" 3 "PCS_IAC_LIMITED_BY_INPUT_POWER" 2 "PCS_IAC_LIMITED_BY_OUTPUT_POWER" 1 "PCS_IAC_LIMITED_BY_RIPPLE_RELAXED" 0 "PCS_IAC_LIMITED_BY_NONE" ;
VAL_ 708 PCS_chgPhBInputCurrentLimitReaso 5 "PCS_IAC_LIMITED_BY_PHASE_MACHINE_MODEL" 4 "PCS_IAC_LIMITED_BY_PHASE_THERMAL_LIMIT" 3 "PCS_IAC_LIMITED_BY_INPUT_POWER" 2 "PCS_IAC_LIMITED_BY_OUTPUT_POWER" 1 "PCS_IAC_LIMITED_BY_RIPPLE_RELAXED" 0 "PCS_IAC_LIMITED_BY_NONE" ;
VAL_ 708 PCS_chgPhCInputCurrentLimitReaso 5 "PCS_IAC_LIMITED_BY_PHASE_MACHINE_MODEL" 4 "PCS_IAC_LIMITED_BY_PHASE_THERMAL_LIMIT" 3 "PCS_IAC_LIMITED_BY_INPUT_POWER" 2 "PCS_IAC_LIMITED_BY_OUTPUT_POWER" 1 "PCS_IAC_LIMITED_BY_RIPPLE_RELAXED" 0 "PCS_IAC_LIMITED_BY_NONE" ;
VAL_ 708 PCS_chgInputFrequencyL1N 0 "FREQUENCY_UNKNOWN" ;
VAL_ 708 PCS_chgInputFrequencyL2N 0 "FREQUENCY_UNKNOWN" ;
VAL_ 708 PCS_chgInputFrequencyL3N 0 "FREQUENCY_UNKNOWN" ;
VAL_ 708 PCS_chgInternalPhaseConfig 9 "PHASE_CONFIG_TOTAL_NUM" 8 "PHASE_CONFIG_SINGLE_PHASE_EVSE_PARALLEL" 7 "PHASE_CONFIG_SINGLE_PHASE_BRIDGED_HARNESS" 6 "PHASE_CONFIG_MFG_TEST_CONFIG_2" 5 "PHASE_CONFIG_MFG_TEST_CONFIG_1" 4 "PHASE_CONFIG_SINGLE_PHASE_IEC_GB" 3 "PHASE_CONFIG_THREE_PHASE_DELTA" 2 "PHASE_CONFIG_THREE_PHASE" 1 "PHASE_CONFIG_SINGLE_PHASE" 0 "PHASE_CONFIG_SNA" ;
VAL_ 708 PCS_chgPhasesPriority 36 "PHASES_PRIORITY_ABC" 33 "PHASES_PRIORITY_BAC" 24 "PHASES_PRIORITY_ACB" 18 "PHASES_PRIORITY_CAB" 9 "PHASES_PRIORITY_BCA" 6 "PHASES_PRIORITY_CBA" 0 "UNDEFINED_PHASES_PRIORITY" ;
VAL_ 708 PCS_chgPhAState 6 "PCS_PH_STATE_SHUTTING_DOWN" 5 "PCS_PH_STATE_CLEAR_FAULTS" 4 "PCS_PH_STATE_FAULT" 3 "PCS_PH_STATE_ENABLE" 2 "PCS_PH_STATE_PRECHARGE" 1 "PCS_PH_STATE_IDLE" 0 "PCS_PH_STATE_INIT" ;
VAL_ 708 PCS_chgPhBState 6 "PCS_PH_STATE_SHUTTING_DOWN" 5 "PCS_PH_STATE_CLEAR_FAULTS" 4 "PCS_PH_STATE_FAULT" 3 "PCS_PH_STATE_ENABLE" 2 "PCS_PH_STATE_PRECHARGE" 1 "PCS_PH_STATE_IDLE" 0 "PCS_PH_STATE_INIT" ;
VAL_ 708 PCS_chgPhCState 6 "PCS_PH_STATE_SHUTTING_DOWN" 5 "PCS_PH_STATE_CLEAR_FAULTS" 4 "PCS_PH_STATE_FAULT" 3 "PCS_PH_STATE_ENABLE" 2 "PCS_PH_STATE_PRECHARGE" 1 "PCS_PH_STATE_IDLE" 0 "PCS_PH_STATE_INIT" ;
VAL_ 708 PCS_chgPhALastShutdownReason 17 "PCS_PH_SHUTDOWN_LINE_TRANSIENT_FAULT" 16 "PCS_PH_SHUTDOWN_FREQ_OUT_OF_RANGE" 15 "PCS_PH_SHUTDOWN_SENSOR_IRRATIONAL" 14 "PCS_PH_SHUTDOWN_TEMP_IRRATIONAL" 13 "PCS_PH_SHUTDOWN_OVER_TEMPERATURE" 12 "PCS_PH_SHUTDOWN_CONTROL_REGULATION_FAULT" 11 "PCS_PH_SHUTDOWN_INT_BUS_UV" 10 "PCS_PH_SHUTDOWN_PRECHARGE_TIMEOUT" 9 "PCS_PH_SHUTDOWN_OUTPUT_OV" 8 "PCS_PH_SHUTDOWN_OUTPUT_UV" 7 "PCS_PH_SHUTDOWN_INPUT_OV" 6 "PCS_PH_SHUTDOWN_INPUT_UV" 5 "PCS_PH_SHUTDOWN_PLL_NOT_LOCKED" 4 "PCS_PH_SHUTDOWN_HW_FAULT" 3 "PCS_PH_SHUTDOWN_SW_FAULT" 2 "PCS_PH_SHUTDOWN_HW_ENABLE" 1 "PCS_PH_SHUTDOWN_SW_ENABLE" 0 "PCS_PH_SHUTDOWN_REASON_NONE" ;
VAL_ 708 PCS_chgPhBLastShutdownReason 17 "PCS_PH_SHUTDOWN_LINE_TRANSIENT_FAULT" 16 "PCS_PH_SHUTDOWN_FREQ_OUT_OF_RANGE" 15 "PCS_PH_SHUTDOWN_SENSOR_IRRATIONAL" 14 "PCS_PH_SHUTDOWN_TEMP_IRRATIONAL" 13 "PCS_PH_SHUTDOWN_OVER_TEMPERATURE" 12 "PCS_PH_SHUTDOWN_CONTROL_REGULATION_FAULT" 11 "PCS_PH_SHUTDOWN_INT_BUS_UV" 10 "PCS_PH_SHUTDOWN_PRECHARGE_TIMEOUT" 9 "PCS_PH_SHUTDOWN_OUTPUT_OV" 8 "PCS_PH_SHUTDOWN_OUTPUT_UV" 7 "PCS_PH_SHUTDOWN_INPUT_OV" 6 "PCS_PH_SHUTDOWN_INPUT_UV" 5 "PCS_PH_SHUTDOWN_PLL_NOT_LOCKED" 4 "PCS_PH_SHUTDOWN_HW_FAULT" 3 "PCS_PH_SHUTDOWN_SW_FAULT" 2 "PCS_PH_SHUTDOWN_HW_ENABLE" 1 "PCS_PH_SHUTDOWN_SW_ENABLE" 0 "PCS_PH_SHUTDOWN_REASON_NONE" ;
VAL_ 708 PCS_chgPhCLastShutdownReason 17 "PCS_PH_SHUTDOWN_LINE_TRANSIENT_FAULT" 16 "PCS_PH_SHUTDOWN_FREQ_OUT_OF_RANGE" 15 "PCS_PH_SHUTDOWN_SENSOR_IRRATIONAL" 14 "PCS_PH_SHUTDOWN_TEMP_IRRATIONAL" 13 "PCS_PH_SHUTDOWN_OVER_TEMPERATURE" 12 "PCS_PH_SHUTDOWN_CONTROL_REGULATION_FAULT" 11 "PCS_PH_SHUTDOWN_INT_BUS_UV" 10 "PCS_PH_SHUTDOWN_PRECHARGE_TIMEOUT" 9 "PCS_PH_SHUTDOWN_OUTPUT_OV" 8 "PCS_PH_SHUTDOWN_OUTPUT_UV" 7 "PCS_PH_SHUTDOWN_INPUT_OV" 6 "PCS_PH_SHUTDOWN_INPUT_UV" 5 "PCS_PH_SHUTDOWN_PLL_NOT_LOCKED" 4 "PCS_PH_SHUTDOWN_HW_FAULT" 3 "PCS_PH_SHUTDOWN_SW_FAULT" 2 "PCS_PH_SHUTDOWN_HW_ENABLE" 1 "PCS_PH_SHUTDOWN_SW_ENABLE" 0 "PCS_PH_SHUTDOWN_REASON_NONE" ;
VAL_ 708 PCS_dcdcTankVoltage -1024 "TANK_VOLTAGE_SNA" ;
VAL_ 708 PCS_cpu2BootState 3 "CPU2_STATE_ERROR" 2 "CPU2_STATE_APPLICATION" 1 "CPU2_STATE_BOOTLOADER" 0 "CPU2_STATE_BOOTROM" ;
VAL_ 708 PCS_acChargeSelfTestState 1 "PCS_SELF_TEST_STARTED" 0 "PCS_SELF_TEST_IDLE" ;
VAL_ 708 PCS_chgAcpwHeartbeatState 4 "PCS_ACPW_HEARTBEAT_STATE_NUM" 3 "PCS_ACPW_HEARTBEAT_STATE_DETECTED_ONGRID" 2 "PCS_ACPW_HEARTBEAT_STATE_DETECTED_OFFGRID" 1 "PCS_ACPW_HEARTBEAT_STATE_NOT_DETECTED" 0 "PCS_ACPW_HEARTBEAT_STATE_UNKNOWN" ;
VAL_ 463 PM_hvilSystemStatus 3 "SNA" 2 "CLOSED" 1 "OPEN" 0 "DISABLED" ;
VAL_ 1409 TCU_logMux 15 "mdmBusyActive" 14 "mdmSIMStatus" 13 "mdmIMSStatus" 12 "mdmServiceState" 11 "mdmUplinkAvgRage" 10 "mdmUplinkAllowedRate" 9 "mdmSINR" 8 "mdmRSRP" 7 "mdmUplinkQueueSize" 6 "totalResumes" 5 "pwmcap" 4 "pwm" 3 "availableMemory" 2 "mdmCoreTemperature" 1 "cpuUsage" 0 "cpuTemp" ;
VAL_ 1409 TCU_mdmBusyActive 4294967295 "SNA" ;
VAL_ 1056 UIS_logMux 354 "activeAppView" 353 "amdSocPkgPower" 352 "audioA2BRediscoveryCount" 351 "audioMediaBrowsing" 350 "audioMediaPlaying" 349 "audioPWSGain" 348 "audioSource" 347 "audioState" 346 "audioType" 345 "audioVolumeLevel" 344 "backlightUserRequest" 343 "bifrostCPUUsage" 342 "bifrostMemUsage" 341 "bifrostOdinEngineRequests" 340 "bifrostOdinEngineUp" 339 "bluetoothAutoConnectionState" 338 "bluetoothCPUUsage" 337 "bluetoothConnectionState" 336 "bluetoothMemUsage" 335 "bluetoothPairResult" 334 "bluetoothStackRearState" 333 "bluetoothStackState" 332 "boardTemperature" 331 "bootCount" 330 "camBackupDecodeAvgFrametime" 329 "camBackupDecodeFramecount" 328 "camBackupDecodeMaxFrametime" 327 "camBackupDecodeMinFrametime" 326 "cameraBackupFramerate" 325 "cameraBackupLateFrames" 324 "cameraBackupMaxFrametime" 323 "cameraBackupPipeline" 322 "cameraBackupPopup" 321 "cameraBackupStream" 320 "cameraBackupStreamMissing" 319 "cameraBackupStreamQuality" 318 "cameraFrontPipeline" 317 "cameraFrontPopup" 316 "cameraFrontStream" 315 "cameraFrontStreamMissing" 314 "cameraLRepeaterFramerate" 313 "cameraLRepeaterLateFrames" 312 "cameraLRepeaterMaxFrametime" 311 "cameraLRepeaterPipeline" 310 "cameraLRepeaterPopup" 309 "cameraLRepeaterStream" 308 "cameraLRepeaterStreamMissing" 307 "cameraRRepeaterFramerate" 306 "cameraRRepeaterLateFrames" 305 "cameraRRepeaterMaxFrametime" 304 "cameraRRepeaterPipeline" 303 "cameraRRepeaterPopup" 302 "cameraRRepeaterStream" 301 "cameraRRepeaterStreamMissing" 300 "carAssistErrorCode" 299 "carAssistSessionCount" 298 "carAssistState" 297 "cellularLinkManagerState" 296 "centerDispAsilA_lsb" 295 "centerDispAsilA_msb" 294 "centerDispAsilB_lsb" 293 "centerDispAsilB_msb" 292 "centerDisplayEvent" 291 "centerDisplayState" 290 "ceruleanx8664CPUUsage" 289 "ceruleanx8664MemUsage" 288 "chargeOnSolarNoChargeReason" 287 "chromiumadapterCPUUsage" 286 "chromiumadapterMemUsage" 285 "clusterCPUUsage" 284 "clusterDisplayState" 283 "clusterFramesOver100Ms" 282 "clusterFramesOver200Ms" 281 "clusterMaxFrametime" 280 "clusterMeanFPS" 279 "clusterMemUsage" 278 "cobaltlinuxCPUUsage" 277 "cobaltlinuxMemUsage" 276 "compositorFrameMonitorState" 275 "compositorRenderAvgRenderTime" 274 "compositorRenderFrameCount" 273 "compositorRenderFrameRate" 272 "compositorRenderGpuPercentage" 271 "compositorRenderMaxFrameTime" 270 "compositorRenderMaxRenderTime" 269 "compositorRenderMinFrameTime" 268 "compositorRenderMinRenderTime" 267 "cpuTemperature" 266 "dashcamOnboardAvailableMB" 265 "dashcamOnboardMB" 264 "dashcamOnboardSavePressCount" 263 "dashcamOnboardTransferCount" 262 "dashcamSavedToOnboardCount" 261 "dashcamSavedToSavedCount" 260 "dashcamSavedToSentryCount" 259 "dashcamState" 258 "dashcamStorageAvailableMB" 257 "dashcamStorageRecentMB" 256 "dashcamStorageSavedMB" 255 "dashcamStorageSentryMB" 254 "dashcamStorageState" 253 "dashcamTransferCount" 252 "dashcamTransferFileCount" 251 "dashcamTransferRateMBps" 250 "dashcamTransferSizeMB" 249 "dashcamTransferTimeMs" 248 "dashcamviewerCPUUsage" 247 "dashcamviewerMemUsage" 246 "developerMode" 245 "dgpuTemperature" 244 "dmCenterAsilFirmwareStatus" 243 "dmCenterAsilOpenFlag" 242 "dmCenterAsilResumeFlag" 241 "dmCenterAsilShortFlag" 240 "dmCenterBacklightDevExists" 239 "dmCenterBacklightDutyCycle" 238 "dmCenterBacklightFault" 237 "dmCenterBacklightNits" 236 "dmCenterBacklightPowerLevel" 235 "dmCenterConnected" 234 "dmCenterEnabled" 233 "dmCenterLinkCheckOk" 232 "dmCenterMOsdExactCrcCheck" 231 "dmCenterMOsdVideoCrcData" 230 "dmCenterModeSettingStatus" 229 "dmCenterOsdDayNightState" 228 "dmCenterOsdDisplayedState" 227 "dmCenterPowerState" 226 "dmCenterSOsdExactCrcCheck" 225 "dmCenterSOsdVideoCrcData" 224 "dmCenterTouchDeviceExists" 223 "dmCenterTouchIrqCount" 222 "dmGatewayLinkWedged" 221 "dmIcuAsilFirmwareStatus" 220 "dmIcuAsilOpenFlag" 219 "dmIcuAsilResumeFlag" 218 "dmIcuAsilShortFlag" 217 "dmIcuBacklightDevExists" 216 "dmIcuBacklightDutyCycle" 215 "dmIcuBacklightFault" 214 "dmIcuBacklightNits" 213 "dmIcuBacklightPowerLevel" 212 "dmIcuConnected" 211 "dmIcuEnabled" 210 "dmIcuLinkCheckOk" 209 "dmIcuPowerState" 208 "dmIcuTouchIrqCount" 207 "dmRearAsilStatusLsb" 206 "dmRearAsilStatusMsb" 205 "dmRearBacklightDevExists" 204 "dmRearBacklightDutyCycle" 203 "dmRearBacklightFault" 202 "dmRearBacklightNits" 201 "dmRearBacklightPowerLevel" 200 "dmRearConnected" 199 "dmRearEnabled" 198 "dmRearLinkCheckOk" 197 "dmRearPowerState" 196 "dmRearTouchDeviceExists" 195 "dumTclipClipCount" 194 "dumTclipSuccessfulUploadCount" 193 "dumTclipTransferCount" 192 "dumTclipUploadActive" 191 "dumTclipUploadState" 190 "embeddedGameName" 189 "embeddedGameState" 188 "estimatedOccupancyCount" 187 "featureSuperchargingEnabled" 186 "firmwareReleaseScope" 185 "godotCPUUsage" 184 "godotMemUsage" 183 "godot_MEMORY_DYNAMIC" 182 "godot_MEMORY_STATIC" 181 "godot_TIME_FPS" 180 "godot_TIME_PROCESS" 179 "gpsmanagerCPUUsage" 178 "gpsmanagerMemUsage" 177 "gtwSocUartRxStatBadChecksum" 176 "gtwSocUartRxStatBadTooBig" 175 "gtwSocUartRxStatBadTooSmall" 174 "gtwSocUartRxStatHandleErr" 173 "gtwSocUartRxStatHeartbeats" 172 "gtwSocUartRxStatMsgErr" 171 "gtwSocUartRxStatUnhandled" 170 "gtwSocUartRxStatValidPackets" 169 "gtwSocUartTxStatAnsMismatch" 168 "gtwSocUartTxStatBadTooBig" 167 "gtwSocUartTxStatNacks" 166 "gtwSocUartTxStatPackets" 165 "gtwSocUartTxStatTimeouts" 164 "headsetConnectionState" 163 "headsetPairResult" 162 "hermesclientCPUUsage" 161 "hermesclientMemUsage" 160 "hermesdynamicCPUUsage" 159 "hermesdynamicMemUsage" 158 "homelinkState" 157 "igpuTemperature" 156 "inSuperchargerGeofence" 155 "limex8664CPUUsage" 154 "limex8664MemUsage" 153 "mediaImageCacheCost" 152 "mediaImageCacheSize" 151 "mediaNeedAuthToken" 150 "mediaPlaybackStatus" 149 "mediaserveCPUUsage" 148 "mediaserveMemUsage" 147 "mirrorGeofenceActive" 146 "modemBusyActive" 145 "modemECallppAvail" 144 "mounterdDashcamCapacityGB" 143 "mounterdDeviceCount" 142 "mounterdEncryptionCapacityGB" 141 "mounterdFilesystemCountExfat" 140 "mounterdFilesystemCountExt3" 139 "mounterdFilesystemCountExt4" 138 "mounterdFilesystemCountFat32" 137 "mounterdFrontHubConnected" 136 "mounterdFrontHubDisconnected" 135 "mounterdMountCountTotal" 134 "mounterdState" 133 "muteNavVolume" 132 "navAudioVolume" 131 "nuanceserverCPUUsage" 130 "nuanceserverMemUsage" 129 "numCorrMemErrorsECC" 128 "numUncorrMemErrorsECC" 127 "nvmeDataUnitsWritten100mb" 126 "nvmePercentLifetimeUsed" 125 "nvmeTemperature" 124 "odinAuthCount" 123 "odinAuthFailCount" 122 "odinCPUUsage" 121 "odinEcuLogForceTriggerUploadState" 120 "odinEcuLogUploadState" 119 "odinFileSystemState" 118 "odinGatewayConnectionState" 117 "odinHermesConnectionState" 116 "odinHrlLogUploadState" 115 "odinHrlUploadLimits" 114 "odinListTasksCmdDurationMs" 113 "odinListTasksCmdResult" 112 "odinMemUsage" 111 "odinNetworkFailCount" 110 "odinNetworkStartCount" 109 "odinOrchestratorFailCount" 108 "odinOrchestratorStartCount" 107 "odinProcessState" 106 "odinStatusCmdDurationMs" 105 "odinStatusCmdResult" 104 "odincefCPUUsage" 103 "odincefMemUsage" 102 "polytopiax8664CPUUsage" 101 "polytopiax8664MemUsage" 100 "powerManagerState" 99 "psiCpuSome" 98 "psiIOFull" 97 "psiIOSome" 96 "psiMemFull" 95 "psiMemSome" 94 "qtcarCPUUsage" 93 "qtcarMemUsage" 92 "radioserveCPUUsage" 91 "radioserveMemUsage" 90 "rearDisplayState" 89 "rearDisplayUserPresent" 88 "releasenotesCPUUsage" 87 "releasenotesMemUsage" 86 "remoteRequestType" 85 "scheduleChargeEndTime" 84 "scheduleChargeStartTime" 83 "scheduledChargingMode" 82 "sentryIncidentCount" 81 "sentryNeedsNap" 80 "sentryState" 79 "serverCPUUsage" 78 "serverMemUsage" 77 "serviceMode" 76 "serviceModePlus" 75 "settingsAutoTurnSignal" 74 "slackerLoginResult" 73 "sleepCount" 72 "sleepState" 71 "sleepTime" 70 "sleepType" 69 "solitaireCPUUsage" 68 "solitaireMemUsage" 67 "speechrecoCPUUsage" 66 "speechrecoMemUsage" 65 "spotifyserverCPUUsage" 64 "spotifyserverMemUsage" 63 "sudokuCPUUsage" 62 "sudokuMemUsage" 61 "superchargePaymentNeeded" 60 "suspensionGeofence" 59 "systemMemSwapUsage" 58 "systemUptime" 57 "systemWakeTime" 56 "tegraModemManState" 55 "teslaMediaCacheCost" 54 "teslaMediaCacheSize" 53 "teslacefgpuCPUUsage" 52 "teslacefgpuMemUsage" 51 "teslacefzygotCPUUsage" 50 "teslacefzygotMemUsage" 49 "teslachromiumCPUUsage" 48 "teslachromiumMemUsage" 47 "testDriveMode" 46 "tmserverCPUUsage" 45 "tmserverMemUsage" 44 "touchEventsAggCount" 43 "tunerCurrentAntenna1" 42 "tunerCurrentAntenna2" 41 "tunerTemperatureCelsius" 40 "tunerTemperatureFahrenheit" 39 "tunerVoltage1V8" 38 "tunerVoltage3V3" 37 "tunerVoltageAntenna1" 36 "tunerVoltageAntenna2" 35 "tunerVoltageMQS" 34 "tunerVoltageOperation" 33 "tunerVoltageUBatt" 32 "uiFramesOver100Ms" 31 "uiFramesOver200Ms" 30 "uiMaxFrametime" 29 "uiMeanFPS" 28 "uiQtCarSwapUsage" 27 "uiQtCarUptime" 26 "valetMode" 25 "valhallaserverCPUUsage" 24 "valhallaserverMemUsage" 23 "vehicleCPUUsage" 22 "vehicleMemUsage" 21 "videodCPUUsage" 20 "videodMemUsage" 19 "vmtouchCPUUsage" 18 "vmtouchMemUsage" 17 "webbrowserCPUUsage" 16 "webbrowserMemUsage" 15 "wifiAutoJoinLowRSSI" 14 "wifiBars" 13 "wifiStackReady" 12 "wifiStackState" 11 "wifiTemperature" 10 "zramCompressedSize" 9 "zramCompressionRatio" 8 "zramFailedReads" 7 "zramFailedWrites" 6 "zramInvalidIO" 5 "zramNotifyFree" 4 "zramOriginalSize" 3 "zramReadIO" 2 "zramReadTicks" 1 "zramWriteIO" 0 "zramWriteTicks" ;
VAL_ 1056 UIS_wifiStackState 17 "WL_RESET_CONNMAN" 16 "WL_RUNNING_LOCAL" 15 "WL_CAPTIVE" 14 "WL_DISCONNECTING" 13 "WL_RUNNING" 12 "WL_WAITING_ONLINE" 11 "WL_CHECKING" 10 "WL_CONFIGURING" 9 "WL_CONNECTING" 8 "WL_SELECTING_NETWORK" 7 "WL_WAITING_AUTOCONNECT" 6 "WL_SEARCHING" 5 "WL_POWERING_ON" 4 "WL_DISABLED_WAIT" 3 "WL_POWERING_OFF" 2 "WL_WAITING_TECHNOLOGY" 1 "WL_RESETTING" 0 "DEFAULT" ;
VAL_ 1056 UIS_wifiAutoJoinLowRSSI 1 "TRUE" 0 "FALSE" ;
VAL_ 1056 UIS_valetMode 1 "TRUE" 0 "FALSE" ;
VAL_ 1056 UIS_tegraModemManState 20 "INVALID" 19 "CHECKINGMODEM" 18 "CHECKINGPORTS" 17 "STOPPINGLINK" 16 "UNCONFIGURINGLINK" 15 "RUNNINGSTATUS" 14 "RUNNING" 13 "CHECKINGLINK" 12 "CONFIGURINGLINK" 11 "RETRYINGLINK" 10 "STARTINLINK" 9 "PRECONDITIONINGLINK" 8 "INITIALIZING2" 7 "CHECKINGANTENNA" 6 "ENABLINGSIM" 5 "INITIALIZING1" 4 "RECOVERING" 3 "WAKING" 2 "SLEEPING" 1 "RESTARTING" 0 "ABORTINGLINK" ;
VAL_ 1056 UIS_suspensionGeofence 1 "REQUESTED" 0 "REMOVED" ;
VAL_ 1056 UIS_sleepType 4 "Unknown" 3 "ModernStandby" 2 "S2Idle" 1 "S3" 0 "Shallow" ;
VAL_ 1056 UIS_sleepState 3 "Wake" 2 "Sleep" 1 "Run" 0 "Boot" ;
VAL_ 1056 UIS_slackerLoginResult 5000 "SLACKER_LOGIN_CREDENTIALS_MISSING" 444 "SLACKER_LOGIN_USER_BUMPED" 412 "SLACKER_LOGIN_TOKEN_INVALID_TIMESTAMP" 409 "SLACKER_LOGIN_TOKEN_REVOKED_KEY" 403 "SLACKER_LOGIN_CAPTCHA_REQUIRED" 401 "SLACKER_LOGIN_INCORRECT_CREDENTIALS" 400 "SLACKER_LOGIN_TOKEN_INVALID_SIGNATURE" 6 "SLACKER_LOGIN_BAD_ACCOUNT_LEVEL" 5 "SLACKER_LOGIN_OTHER_ERROR" 4 "SLACKER_LOGIN_NET_ERROR" 3 "SLACKER_LOGIN_TOKEN_UNKNOWN_ERROR" 2 "SLACKER_LOGIN_SUCCESS" 1 "SLACKER_LOGIN_SERVERTIME_FAILED" ;
VAL_ 1056 UIS_sentryState 5 "QUIET" 4 "PANIC" 3 "AWARE" 2 "ARMED" 1 "IDLE" 0 "OFF" ;
VAL_ 1056 UIS_scheduledChargingMode 3 "TIME_WINDOW" 2 "END_BY" 1 "START_AT" 0 "OFF" ;
VAL_ 1056 UIS_remoteRequestType 106 "NAV_GPS_DESTINATION_REQUEST" 105 "TESLA_AUTH_RESPONSE" 104 "GET_MESSAGE" 103 "SET_LIGHTBAR_DITCH" 102 "SET_LIGHTBAR_MIDDLE" 101 "SET_LIGHTBAR_BRIGHTNESS" 100 "REMOVE_PRECONDITION_SCHEDULE" 99 "ADD_PRECONDITION_SCHEDULE" 98 "REMOVE_CHARGE_SCHEDULE" 97 "ADD_CHARGE_SCHEDULE" 96 "SET_REAR_ZONE_LIGHT_REQUEST" 95 "SET_FRONT_ZONE_LIGHT_REQUEST" 94 "SET_TENT_MODE_REQUEST" 93 "SET_POWERSHARE_REQUEST" 92 "SET_POWERSHARE_DISCHARGE_LIMIT" 91 "SET_POWERSHARE_FEATURE" 90 "NAVIGATION_WAYPOINTS_REQUEST" 89 "VEHICLE_CONTROL_RESET_PIN_TO_DRIVE_ADMIN" 88 "SET_TRUCK_BED_LIGHT_BRIGHTNESS" 87 "SET_TRUCK_BED_LIGHT_AUTO_STATE" 86 "SET_TRAILER_LIGHT_TEST_START_STOP" 85 "SET_POWER_FEED_SOC_LIMIT" 84 "SET_POWER_FEED_TIMER" 83 "SET_POWER_FEED_ON_OFF" 82 "SET_OUTLET_SOC_LIMIT" 81 "SET_OUTLET_TIMER" 80 "SET_OUTLETS_ON_OFF" 79 "DRIVING_CLEAR_SPEED_LIMIT_PIN_ADMIN" 78 "VEHICLE_CONTROL_RESET_PIN_TO_DRIVE" 77 "VEHICLE_CONTROL_SET_PIN_TO_DRIVE" 76 "RESERVED_SEVENTY_SIX" 75 "GET_CHARGE_ON_SOLAR_FEATURE" 74 "UPDATE_CHARGE_ON_SOLAR_FEATURE" 73 "GET_MANAGED_CHARGING_SITES" 72 "ERASE_USER_DATA" 71 "STW_HEAT_LEVEL" 70 "AUTO_STW_HEAT" 69 "NAVIGATION_ROUTE" 68 "REMOVE_MANAGED_CHARGING_SITE" 67 "ADD_MANAGED_CHARGING_SITE" 66 "SET_COP_TEMP" 65 "GUEST_MODE" 64 "BOOMBOX" 63 "BLUETOOTH_CLASSIC_PAIRING_REQUEST" 62 "CHARGE_PORT_DOOR_OPEN" 61 "CHARGE_PORT_DOOR_CLOSE" 60 "RESERVED_SIXTY" 59 "RESERVED_FIFTY_NINE" 58 "TAKE_DRIVENOTE" 57 "VIDEO_REQUEST" 56 "GET_RATE_TARIFF" 55 "RESERVED_FIFTY_FIVE" 54 "SET_VEHICLE_NAME" 53 "NAVIGATION_GPS_REQUEST" 52 "PSEUDONYM_SYNC_REQUEST" 51 "PII_KEY_REQUEST" 50 "SET_CABIN_OVERHEAT_PROTECTION" 49 "HVAC_SEAT_COOLER_ACTIONS" 48 "AUTO_SEAT_CLIMATE" 47 "DASHCAM_SAVE_CLIP" 46 "PING" 45 "HVAC_RECIRCULATION" 44 "HVAC_CLIMATE_KEEPER" 43 "SET_CHARGING_AMPS" 42 "SCHEDULED_DEPARTURE" 41 "SCHEDULED_CHARGING" 40 "VITALS_ACK" 39 "VITALS_SUBSCRIPTION" 38 "VEHICLE_DATA_ACK" 37 "VEHICLE_DATA_SUBSCRIPTION" 36 "HVAC_SEAT_HEATER_ACTIONS" 35 "HVAC_BIO_WEAPON_MODE" 34 "VEHICLE_CONTROL_WINDOW" 33 "VEHICLE_CONTROL_TRIGGER_HOMELINK" 32 "VEHICLE_CONTROL_SUNROOF_OPEN_CLOSE" 31 "VEHICLE_CONTROL_SET_VALET_MODE" 30 "VEHICLE_CONTROL_SET_SENTRY_MODE" 29 "VEHICLE_CONTROL_SCHEDULE_SOFTWARE_UPDATE" 28 "VEHICLE_CONTROL_RESET_VALET_PIN" 27 "VEHICLE_CONTROL_HONK_HORN" 26 "VEHICLE_CONTROL_FLASH_LIGHTS" 25 "VEHICLE_CONTROL_CANCEL_SOFTWARE_UPDATE" 24 "UI_SET_UPCOMING_CALENDAR_ENTRIES" 23 "GET_NEARBY_CHARGING_SITES" 22 "NAVIGATION_SUPERCHARGER_REQUEST" 21 "NAVIGATION_REQUEST" 20 "MEDIA_PREVIOUS_TRACK" 19 "MEDIA_NEXT_TRACK" 18 "MEDIA_PREVIOUS_FAVORITE" 17 "MEDIA_NEXT_FAVORITE" 16 "MEDIA_UPDATE_VOLUME" 15 "MEDIA_PLAY" 14 "HVAC_TEMPERATURE_ADJUSTMENT" 13 "HVAC_STEERING_WHEEL_HEATER" 12 "HVAC_SET_PRECONDITIONING_MAX" 11 "RESERVED_ELEVEN" 10 "HVAC_AUTO" 9 "DRIVING_SPEED_LIMIT" 8 "DRIVING_SET_SPEED_LIMIT" 7 "DRIVING_CLEAR_SPEED_LIMIT_PIN" 6 "CHARGING_START_STOP" 5 "CHARGING_SET_LIMIT" 4 "STREAM_MESSAGE" 3 "CREATE_STREAM_SESSION" 2 "REMOTE_START_DRIVE" 1 "GET_VEHICLE_DATA" 0 "UNKNOWN" ;
VAL_ 1056 UIS_rearDisplayUserPresent 1 "TRUE" 0 "FALSE" ;
VAL_ 1056 UIS_rearDisplayState 9 "ENTERTAINMENT" 8 "DOG" 7 "SENTRY" 6 "LOCK" 5 "CHARGING" 4 "DRIVING" 3 "ON" 2 "ACCESSORY" 1 "DIM" 0 "OFF" ;
VAL_ 1056 UIS_powerManagerState 31 "PMS_ENTERINGROBOTAXILOADSHED" 30 "PMS_ROBOTAXILOADSHEDDING" 29 "PMS_UPLOADDATA" 28 "PMS_EXTREMELOADSHEDDING" 27 "PMS_ENTERINGEXTREMELOADSHED" 26 "PMS_PREPARINGSLEEP" 25 "PMS_ENTERINGLOADSHED" 24 "PMS_SENTRYACTIVE" 23 "PMS_EXITINGLOADSHED" 22 "PMS_LOADSHEDDING" 21 "PMS_EXITINGSENTRY" 20 "PMS_SENTRYARMED" 19 "PMS_ENTERINGSENTRY" 18 "PMS_UNKNOWN_SNA" 17 "PMS_EXITINGSLEEP" 16 "PMS_READYFORSLEEP" 15 "PMS_WAITINGONRAILS" 14 "PMS_PERFORMANCE" 13 "PMS_HIGHPOWERSTARTED" 12 "PMS_HIGHPOWERSTOPPING" 11 "PMS_HIGHPOWERSTARTING" 10 "PMS_REBOOT" 9 "PMS_ENTERINGSLEEP" 8 "PMS_ALLTUCKEDIN" 7 "PMS_CHARGING" 6 "PMS_AUDIOSTOPPED" 5 "PMS_AUDIOSTOPPING" 4 "PMS_POWERBROWNOUT" 3 "PMS_AUDIOSTARTING" 2 "PMS_ACCDELAY" 1 "PMS_FULLPOWER" 0 "PMS_CHECKING" ;
VAL_ 1056 UIS_modemECallppAvail 1 "ENABLED" 0 "DISABLED" ;
VAL_ 1056 UIS_modemBusyActive 1 "RUNNING" 0 "OFF" ;
VAL_ 1056 UIS_mirrorGeofenceActive 1 "TRUE" 0 "FALSE" ;
VAL_ 1056 UIS_mediaPlaybackStatus 2 "PAUSED" 1 "PLAYING" 0 "STOPPED" ;
VAL_ 1056 UIS_mediaNeedAuthToken 1 "TRUE" 0 "FALSE" ;
VAL_ 1056 UIS_inSuperchargerGeofence 1 "TRUE" 0 "FALSE" ;
VAL_ 1056 UIS_homelinkState 23 "HW_ERROR" 22 "UNIVERSAL_RECEIVER_ERROR" 21 "UNIVERSAL_RECEIVER_SUCCESS" 20 "UNIVERSAL_RECEIVER_WAIT" 19 "DEFAULT_FAIL" 18 "DEFAULT_SUCCESS" 17 "DEFAULT_WAIT" 16 "STANDARD_FAIL" 15 "STANDARD_SUCCESS" 14 "STANDARD_WAIT" 13 "CLEAR_FAIL" 12 "CLEAR_SUCCESS" 11 "CLEAR_WAIT" 10 "TIMEOUT" 9 "LEARN_FAIL" 8 "LEARN_CANCLE" 7 "LEARN_SUCCESS_NOT_ROLLING" 6 "LEARN_SUCCESS_ROLLING" 5 "LEARN_TEST" 4 "LEARN_SUCCESS" 3 "LEARN_WAIT" 2 "PROGRAM_WAIT" 1 "TRANSMITTING" 0 "IDLE" ;
VAL_ 1056 UIS_headsetPairResult 23 "HID_PAIRED" 22 "HID_MAX_NR_OF_CONNS" 21 "HID_PAGE_TIMEOUT" 20 "HID_OETC_USER" 19 "HID_REJ_BY_REMOTE_NO_RES" 18 "HID_LMP_RESPONSE_TIMEOUT" 17 "HID_AUTH_FAILURE" 16 "HID_KEY_MISSING" 15 "HID_NO_RESPONSE" 14 "HID_ALREADY_REQUESTED_BY_REMOTE" 13 "HID_UNKNOWN" 12 "HID_UNPAIRED" 11 "PAIRED" 10 "MAX_NR_OF_CONNS" 9 "PAGE_TIMEOUT" 8 "OETC_USER" 7 "REJ_BY_REMOTE_NO_RES" 6 "LMP_RESPONSE_TIMEOUT" 5 "AUTH_FAILURE" 4 "KEY_MISSING" 3 "NO_RESPONSE" 2 "ALREADY_REQUESTED_BY_REMOTE" 1 "UNKNOWN" 0 "UNPAIRED" ;
VAL_ 1056 UIS_headsetConnectionState 77 "HID_ERROR_UNKNOWN" 76 "HID_ERROR_ANTENNA_DISCONNECTED" 75 "HID_CONNECTED" 74 "HID_CONNECT_CANCELLED" 73 "HID_CONNECT_PROFILE_UNAVAILABLE" 72 "HID_CONNECT_INVALID_ARGUMENT" 71 "HID_CONNECT_ADAPTER_OFF" 70 "HID_CONNECT_NOT_SUPPORTED" 69 "HID_CONNECT_ALREADY_CONN" 68 "HID_CONNECT_DEVICE_NOT_FOUND_NO_RESOURCES" 67 "HID_CONNECT_DEVICE_NOT_FOUND_PAGE_TIMEOUT" 66 "HID_CONNECT_DEVICE_NOT_FOUND" 65 "HID_CONNECT_FAILED_REMOTE_TERMINATED" 64 "HID_CONNECT_FAILED_NO_RESOURCES" 63 "HID_CONNECT_FAILED_CONNECTION_TIMEOUT" 62 "HID_CONNECT_FAILED" 61 "HID_CONNECT_SDP_FAILURE" 60 "HID_CONNECT_PIN_MISSING" 59 "HID_CONNECT_PAGE_TIMEOUT" 58 "HID_CONNECT_REJ_BY_REMOTE_NO_RES" 57 "HID_CONNECT_MAX_NR_OF_CONNS" 56 "HID_CONNECT_CONTROLLER_BUSY" 55 "HID_CONNECT_CONN_TIMEOUT" 54 "HID_CONNECT_MAX_NR_OF_ACL" 53 "HID_CONNECT_LMP_RESPONSE_TIMEOUT" 52 "HID_CONNECT_HOST_TIMEOUT" 51 "HID_CONNECT_UNKNOWN_FAILURE" 50 "HID_DISCONNECT_UNKNOWN" 49 "HID_DISCONNECT_OETC_POWERING_OFF" 48 "HID_DISCONNECT_OETC_LOW_RESOURCE" 47 "HID_DISCONNECT_REJ_BY_REMOTE_SEC" 46 "HID_DISCONNECT_AUTH_FAIL" 45 "HID_DISCONNECT_LMP_RESPONSE_TIMEOUT" 44 "HID_DISCONNECT_OETC_USER" 43 "HID_DISCONNECT_CONN_TIMEOUT" 42 "HID_DISCONNECT_CONN_TERM_LOCAL_HOST" 41 "HID_DISCONNECT_LINKLOSS" 40 "HID_DISCONNECT_FROM_REMOTE" 39 "HID_DISCONNECTED" 38 "ERROR_UNKNOWN" 37 "ERROR_ANTENNA_DISCONNECTED" 36 "CONNECTED" 35 "CONNECT_CANCELLED" 34 "CONNECT_PROFILE_UNAVAILABLE" 33 "CONNECT_INVALID_ARGUMENT" 32 "CONNECT_ADAPTER_OFF" 31 "CONNECT_NOT_SUPPORTED" 30 "CONNECT_ALREADY_CONN" 29 "CONNECT_DEVICE_NOT_FOUND_NO_RESOURCES" 28 "CONNECT_DEVICE_NOT_FOUND_PAGE_TIMEOUT" 27 "CONNECT_DEVICE_NOT_FOUND" 26 "CONNECT_FAILED_REMOTE_TERMINATED" 25 "CONNECT_FAILED_NO_RESOURCES" 24 "CONNECT_FAILED_CONNECTION_TIMEOUT" 23 "CONNECT_FAILED" 22 "CONNECT_SDP_FAILURE" 21 "CONNECT_PIN_MISSING" 20 "CONNECT_PAGE_TIMEOUT" 19 "CONNECT_REJ_BY_REMOTE_NO_RES" 18 "CONNECT_MAX_NR_OF_CONNS" 17 "CONNECT_CONTROLLER_BUSY" 16 "CONNECT_CONN_TIMEOUT" 15 "CONNECT_MAX_NR_OF_ACL" 14 "CONNECT_LMP_RESPONSE_TIMEOUT" 13 "CONNECT_HOST_TIMEOUT" 12 "CONNECT_UNKNOWN_FAILURE" 11 "DISCONNECT_UNKNOWN" 10 "DISCONNECT_OETC_POWERING_OFF" 9 "DISCONNECT_OETC_LOW_RESOURCE" 8 "DISCONNECT_REJ_BY_REMOTE_SEC" 7 "DISCONNECT_AUTH_FAIL" 6 "DISCONNECT_LMP_RESPONSE_TIMEOUT" 5 "DISCONNECT_OETC_USER" 4 "DISCONNECT_CONN_TIMEOUT" 3 "DISCONNECT_CONN_TERM_LOCAL_HOST" 2 "DISCONNECT_LINKLOSS" 1 "DISCONNECT_FROM_REMOTE" 0 "DISCONNECTED" ;
VAL_ 1056 UIS_dmRearPowerState 1 "ON" 0 "OFF" ;
VAL_ 1056 UIS_dmRearLinkCheckOk 1 "PASSED" 0 "FAILED" ;
VAL_ 1056 UIS_dmRearBacklightDevExists 1 "PASSED" 0 "FAILED" ;
VAL_ 1056 UIS_dmIcuPowerState 1 "ON" 0 "OFF" ;
VAL_ 1056 UIS_dmIcuLinkCheckOk 1 "PASSED" 0 "FAILED" ;
VAL_ 1056 UIS_dmIcuBacklightDevExists 1 "PASSED" 0 "FAILED" ;
VAL_ 1056 UIS_dmCenterPowerState 1 "ON" 0 "OFF" ;
VAL_ 1056 UIS_dmCenterOsdDisplayedState 1 "SHOWING" 0 "HIDDEN" ;
VAL_ 1056 UIS_dmCenterLinkCheckOk 1 "PASSED" 0 "FAILED" ;
VAL_ 1056 UIS_dmCenterBacklightPowerLevel 2 "HIGH_POWER" 1 "LOW_POWER" 0 "OFF" ;
VAL_ 1056 UIS_dmCenterBacklightDevExists 1 "PASSED" 0 "FAILED" ;
VAL_ 1056 UIS_dashcamStorageState 8 "RECENT_BUFFER_DURATION_REDUCED" 7 "SLOW" 6 "READ_ONLY" 5 "FULL" 4 "GETTING_FULL" 3 "ERROR" 2 "READY" 1 "REMOVED" 0 "INVALID" ;
VAL_ 1056 UIS_dashcamState 7 "STREAMING" 6 "SAVING" 5 "PAUSED" 4 "RECORDING" 3 "STOPPED" 2 "ERROR" 1 "TERMINATED" 0 "INVALID" ;
VAL_ 1056 UIS_clusterDisplayState 9 "ENTERTAINMENT" 8 "DOG" 7 "SENTRY" 6 "LOCK" 5 "CHARGING" 4 "DRIVING" 3 "ON" 2 "ACCESSORY" 1 "DIM" 0 "OFF" ;
VAL_ 1056 UIS_chargeOnSolarNoChargeReason 3 "ALTERNATIVE_VEHICLE_CHARGE_PRIORITY" 2 "GRID_EXPORT_PRIORITY" 1 "POWERWALL_CHRAGE_PRIORITY" 0 "INSUFFICIENT_SOLAR" ;
VAL_ 1056 UIS_centerDisplayState 9 "ENTERTAINMENT" 8 "DOG" 7 "SENTRY" 6 "LOCK" 5 "CHARGING" 4 "DRIVING" 3 "ON" 2 "ACCESSORY" 1 "DIM" 0 "OFF" ;
VAL_ 1056 UIS_centerDisplayEvent 21 "CPD_TRIGGERED" 20 "CAR_LOCKED" 19 "ENTERTAINMENT_OFF" 18 "ALL_STATES_EXCEPT_ENTERTAINMENT_TURNED_ON" 17 "IC_HAZARDS_OFF_DOOR_CLOSED_NO_OCCUPANTS" 16 "IC_HAZARDS_ON" 15 "ALL_DOORS_CLOSED_NO_OCCUPANTS_CHARGE_ACTIVE" 14 "TIMEOUT" 13 "DOOR_HANDLE_PULLED" 12 "ALL_STATES_EXCEPT_SENTRY" 11 "SENTRY_PANIC_ENDED" 10 "POWER_OFF_REQUEST" 9 "DRIVE_RAIL_OFF_NO_DRIVER_PRESENT" 8 "DRIVE_RAIL_OFF_DOOR_OPEN" 7 "DRIVE_RAIL_OFF_DRIVE_PRESENT" 6 "POWER_ON_REQUEST" 5 "DOOR_OPENED" 4 "ALL_STATES_EXCEPT_ENTERTAINMENT_DRIVE_RAIL_TURNED_ON" 3 "ALL_DOORS_CLOSED_NO_OCCUPANTS" 2 "PASSED_SPEED_THRESHOLD" 1 "SHIFTED_P_TO_N" 0 "OTHER" ;
VAL_ 1056 UIS_cellularLinkManagerState 16 "INVALID" 15 "RUNNING" 14 "DISCONNECTING" 13 "ROAMINGDISALLOWED" 12 "ENTERINGAIRPLANEMODE" 11 "CHECKING" 10 "RETRYING" 9 "CONFIGURING" 8 "CONNECTING" 7 "OFONOMODEMRELOADING" 6 "SEARCHING" 5 "CONFIGURINGAPN" 4 "QUERYDIAGNOSTIC" 3 "STARTING" 2 "UPDATING" 1 "RESETTING" 0 "RECOVERING" ;
VAL_ 1056 UIS_carAssistState 5 "GROK" 4 "DICTATION" 3 "COMMAND" 2 "ERROR" 1 "IDLE" 0 "DISABLED" ;
VAL_ 1056 UIS_carAssistErrorCode 17 "CLIENT_LOGGED_OUT_TOKEN_EXPIRED" 16 "CLIENT_PROVIDER_RATE_LIMTED" 15 "CLIENT_PROVIDER_AT_CAPACITY" 14 "CLIENT_ANON_USAGE_LIMITED" 13 "CLIENT_PREM_CONN" 12 "CLIENT_SPEECH" 11 "CLIENT_REMOTE" 10 "CLIENT_DBUS" 9 "CLIENT_DISCONNECTED" 8 "CLIENT_CONNECTIVITY" 7 "CLIENT_AUDIO" 6 "CLIENT_ERROR" 5 "COMMAND_NOT_IMPLEMENTED" 4 "COMMAND_NOT_AVAILABLE" 3 "COMMAND_NOT_UNDERSTOOD" 2 "REMOTE_ERROR" 1 "REMOTE_UNKNOWN" 0 "NONE" ;
VAL_ 1056 UIS_cameraRRepeaterStreamMissing 1 "MISSING" 0 "ACTIVE" ;
VAL_ 1056 UIS_cameraRRepeaterPopup 1 "OPEN" 0 "CLOSED" ;
VAL_ 1056 UIS_cameraRRepeaterPipeline 4 "PLAYING" 3 "PAUSED" 2 "READY" 1 "NULL" 0 "SLEEP" ;
VAL_ 1056 UIS_cameraLRepeaterStreamMissing 1 "MISSING" 0 "ACTIVE" ;
VAL_ 1056 UIS_cameraLRepeaterPopup 1 "OPEN" 0 "CLOSED" ;
VAL_ 1056 UIS_cameraLRepeaterPipeline 4 "PLAYING" 3 "PAUSED" 2 "READY" 1 "NULL" 0 "SLEEP" ;
VAL_ 1056 UIS_cameraBackupStreamMissing 1 "MISSING" 0 "ACTIVE" ;
VAL_ 1056 UIS_cameraBackupPopup 1 "OPEN" 0 "CLOSED" ;
VAL_ 1056 UIS_cameraBackupPipeline 4 "PLAYING" 3 "PAUSED" 2 "READY" 1 "NULL" 0 "SLEEP" ;
VAL_ 1056 UIS_bluetoothStackState 4 "ON_BLUEZ" 3 "ON_SYNERGY" 2 "ON_LGIT" 1 "ON" 0 "OFF" ;
VAL_ 1056 UIS_bluetoothStackRearState 4 "ON_BLUEZ" 3 "ON_SYNERGY" 2 "ON_LGIT" 1 "ON" 0 "OFF" ;
VAL_ 1056 UIS_bluetoothPairResult 23 "HID_PAIRED" 22 "HID_MAX_NR_OF_CONNS" 21 "HID_PAGE_TIMEOUT" 20 "HID_OETC_USER" 19 "HID_REJ_BY_REMOTE_NO_RES" 18 "HID_LMP_RESPONSE_TIMEOUT" 17 "HID_AUTH_FAILURE" 16 "HID_KEY_MISSING" 15 "HID_NO_RESPONSE" 14 "HID_ALREADY_REQUESTED_BY_REMOTE" 13 "HID_UNKNOWN" 12 "HID_UNPAIRED" 11 "PAIRED" 10 "MAX_NR_OF_CONNS" 9 "PAGE_TIMEOUT" 8 "OETC_USER" 7 "REJ_BY_REMOTE_NO_RES" 6 "LMP_RESPONSE_TIMEOUT" 5 "AUTH_FAILURE" 4 "KEY_MISSING" 3 "NO_RESPONSE" 2 "ALREADY_REQUESTED_BY_REMOTE" 1 "UNKNOWN" 0 "UNPAIRED" ;
VAL_ 1056 UIS_bluetoothConnectionState 77 "HID_ERROR_UNKNOWN" 76 "HID_ERROR_ANTENNA_DISCONNECTED" 75 "HID_CONNECTED" 74 "HID_CONNECT_CANCELLED" 73 "HID_CONNECT_PROFILE_UNAVAILABLE" 72 "HID_CONNECT_INVALID_ARGUMENT" 71 "HID_CONNECT_ADAPTER_OFF" 70 "HID_CONNECT_NOT_SUPPORTED" 69 "HID_CONNECT_ALREADY_CONN" 68 "HID_CONNECT_DEVICE_NOT_FOUND_NO_RESOURCES" 67 "HID_CONNECT_DEVICE_NOT_FOUND_PAGE_TIMEOUT" 66 "HID_CONNECT_DEVICE_NOT_FOUND" 65 "HID_CONNECT_FAILED_REMOTE_TERMINATED" 64 "HID_CONNECT_FAILED_NO_RESOURCES" 63 "HID_CONNECT_FAILED_CONNECTION_TIMEOUT" 62 "HID_CONNECT_FAILED" 61 "HID_CONNECT_SDP_FAILURE" 60 "HID_CONNECT_PIN_MISSING" 59 "HID_CONNECT_PAGE_TIMEOUT" 58 "HID_CONNECT_REJ_BY_REMOTE_NO_RES" 57 "HID_CONNECT_MAX_NR_OF_CONNS" 56 "HID_CONNECT_CONTROLLER_BUSY" 55 "HID_CONNECT_CONN_TIMEOUT" 54 "HID_CONNECT_MAX_NR_OF_ACL" 53 "HID_CONNECT_LMP_RESPONSE_TIMEOUT" 52 "HID_CONNECT_HOST_TIMEOUT" 51 "HID_CONNECT_UNKNOWN_FAILURE" 50 "HID_DISCONNECT_UNKNOWN" 49 "HID_DISCONNECT_OETC_POWERING_OFF" 48 "HID_DISCONNECT_OETC_LOW_RESOURCE" 47 "HID_DISCONNECT_REJ_BY_REMOTE_SEC" 46 "HID_DISCONNECT_AUTH_FAIL" 45 "HID_DISCONNECT_LMP_RESPONSE_TIMEOUT" 44 "HID_DISCONNECT_OETC_USER" 43 "HID_DISCONNECT_CONN_TIMEOUT" 42 "HID_DISCONNECT_CONN_TERM_LOCAL_HOST" 41 "HID_DISCONNECT_LINKLOSS" 40 "HID_DISCONNECT_FROM_REMOTE" 39 "HID_DISCONNECTED" 38 "ERROR_UNKNOWN" 37 "ERROR_ANTENNA_DISCONNECTED" 36 "CONNECTED" 35 "CONNECT_CANCELLED" 34 "CONNECT_PROFILE_UNAVAILABLE" 33 "CONNECT_INVALID_ARGUMENT" 32 "CONNECT_ADAPTER_OFF" 31 "CONNECT_NOT_SUPPORTED" 30 "CONNECT_ALREADY_CONN" 29 "CONNECT_DEVICE_NOT_FOUND_NO_RESOURCES" 28 "CONNECT_DEVICE_NOT_FOUND_PAGE_TIMEOUT" 27 "CONNECT_DEVICE_NOT_FOUND" 26 "CONNECT_FAILED_REMOTE_TERMINATED" 25 "CONNECT_FAILED_NO_RESOURCES" 24 "CONNECT_FAILED_CONNECTION_TIMEOUT" 23 "CONNECT_FAILED" 22 "CONNECT_SDP_FAILURE" 21 "CONNECT_PIN_MISSING" 20 "CONNECT_PAGE_TIMEOUT" 19 "CONNECT_REJ_BY_REMOTE_NO_RES" 18 "CONNECT_MAX_NR_OF_CONNS" 17 "CONNECT_CONTROLLER_BUSY" 16 "CONNECT_CONN_TIMEOUT" 15 "CONNECT_MAX_NR_OF_ACL" 14 "CONNECT_LMP_RESPONSE_TIMEOUT" 13 "CONNECT_HOST_TIMEOUT" 12 "CONNECT_UNKNOWN_FAILURE" 11 "DISCONNECT_UNKNOWN" 10 "DISCONNECT_OETC_POWERING_OFF" 9 "DISCONNECT_OETC_LOW_RESOURCE" 8 "DISCONNECT_REJ_BY_REMOTE_SEC" 7 "DISCONNECT_AUTH_FAIL" 6 "DISCONNECT_LMP_RESPONSE_TIMEOUT" 5 "DISCONNECT_OETC_USER" 4 "DISCONNECT_CONN_TIMEOUT" 3 "DISCONNECT_CONN_TERM_LOCAL_HOST" 2 "DISCONNECT_LINKLOSS" 1 "DISCONNECT_FROM_REMOTE" 0 "DISCONNECTED" ;
VAL_ 1056 UIS_bluetoothAutoConnectionState 3 "MANUAL_CONNECT_REQUESTED" 2 "GAVE_UP" 1 "CONNECTED" 0 "IDLE" ;
VAL_ 1056 UIS_audioType 4 "BASE_WITH_PREMIUM200" 3 "PREMIUM" 2 "BASE" 1 "NO_A2B" 0 "INVALID" ;
VAL_ 1056 UIS_audioState 7 "SLEEPING" 6 "AUDIO_NOT_PUMPING" 5 "A2B_REDISCOVERY" 4 "HFP_PUMPING" 3 "AUDIO_PUMPING" 2 "UNINITIALIZING" 1 "INITIALIZING" 0 "TERMINATED" ;
VAL_ 1056 UIS_audioSource 5 "NONE" 4 "PHONE_RX" 3 "BLUETOOTH" 2 "MICROPHONE" 1 "TUNER" 0 "MEDIA" ;
VAL_ 1056 UIS_audioMediaPlaying 39 "SODA_MUSIC" 38 "CARAOKE" 37 "KUGOU" 36 "YOUTUBE_MUSIC" 35 "YUNTING" 34 "AMAZON_MUSIC" 33 "AUDIBLE" 32 "APPLE_PODCASTS" 31 "APPLE_MUSIC" 30 "MINI_PROGRAMS" 29 "SEARCH" 28 "HOME_APPS" 27 "RECENTS_FAVORITES" 26 "TOYBOX" 25 "TUTORIAL" 24 "THEATER" 23 "BROWSER" 22 "GAME" 21 "NET_EASE_MUSIC" 20 "ONLINE_RADIO" 19 "XIMALAYA" 18 "QQ_MUSIC2" 17 "QQ_MUSIC1" 16 "TIDAL" 15 "SIRIUS_XM" 14 "STINGRAY" 13 "TUNE_IN" 12 "EU_RADIO" 11 "US_RADIO" 10 "SPOTIFY" 9 "SLACKER" 8 "BLUETOOTH" 7 "USB" 6 "DAB" 5 "XM" 4 "FM" 3 "AM" 2 "UNKNOWN" 1 "DEPRECATED" 0 "NONE" ;
VAL_ 1056 UIS_audioMediaBrowsing 39 "SODA_MUSIC" 38 "CARAOKE" 37 "KUGOU" 36 "YOUTUBE_MUSIC" 35 "YUNTING" 34 "AMAZON_MUSIC" 33 "AUDIBLE" 32 "APPLE_PODCASTS" 31 "APPLE_MUSIC" 30 "MINI_PROGRAMS" 29 "SEARCH" 28 "HOME_APPS" 27 "RECENTS_FAVORITES" 26 "TOYBOX" 25 "TUTORIAL" 24 "THEATER" 23 "BROWSER" 22 "GAME" 21 "NET_EASE_MUSIC" 20 "ONLINE_RADIO" 19 "XIMALAYA" 18 "QQ_MUSIC2" 17 "QQ_MUSIC1" 16 "TIDAL" 15 "SIRIUS_XM" 14 "STINGRAY" 13 "TUNE_IN" 12 "EU_RADIO" 11 "US_RADIO" 10 "SPOTIFY" 9 "SLACKER" 8 "BLUETOOTH" 7 "USB" 6 "DAB" 5 "XM" 4 "FM" 3 "AM" 2 "UNKNOWN" 1 "DEPRECATED" 0 "NONE" ;
VAL_ 1056 UIS_activeAppView 67 "SODA_MUSIC" 66 "HICAR" 65 "CARAOKE_WEB" 64 "KUGOU" 63 "YOUTUBE_MUSIC" 62 "YUNTING" 61 "ONLINE_RADIO" 60 "AMAZON_MUSIC" 59 "AUDIBLE" 58 "APPLE_PODCASTS" 57 "ONBOARDING_MANUAL" 56 "APPLE_MUSIC" 55 "ZOOM" 54 "MINI_PROGRAMS" 53 "CADMIUM" 52 "MESSAGES" 51 "NAV_MEDIA" 50 "BACKGAMMON" 49 "SKETCH_PAD" 48 "ARCADE" 47 "XIMALAYA" 46 "BLUETOOTH" 45 "CHESS" 44 "NETEASE" 43 "OWNERS_MANUAL" 42 "QQMUSIC" 41 "RELEASE_NOTES" 40 "SONIC" 39 "USB" 38 "THEATER" 37 "TIDAL" 36 "TUNEIN" 35 "CARAOKE" 34 "STREAMING" 33 "RADIO" 32 "SPOTIFY" 31 "CAMERA" 30 "CHARGE" 29 "MEDIA" 28 "ENTERTAINMENT" 27 "WEB" 26 "CALENDAR" 25 "TOYBOX" 24 "PHONE" 23 "ENERGY" 22 "TUTORIAL" 21 "CERULEAN" 20 "TOPAZ" 19 "DASHCAM" 18 "CARBONADO" 17 "THEATERVIEW" 16 "MAMBU" 15 "COBALT" 14 "TESLATARI" 13 "SERVICE_APPS" 12 "LIME" 11 "TEARDROP" 10 "NAV" 9 "PURPLE" 8 "CALICO" 7 "CARWASH" 6 "2048" 5 "CONTROLS" 4 "COLORIZER" 3 "XM" 2 "DEVELOPMENT" 1 "NONE" 0 "UNKNOWN" ;
VAL_ 979 UI_airbagCutoffSwState 2 "SNA" 1 "PASSENGER_AIRBAG_OFF" 0 "PASSENGER_AIRBAG_ON" ;
VAL_ 1657 UI_rgbEnableState 2 "AUTO" 1 "ON" 0 "OFF" ;
VAL_ 1657 UI_rgbEffectType 20 "RAMP_5000MS" 19 "RAMP_4750MS" 18 "RAMP_4500MS" 17 "RAMP_4250MS" 16 "RAMP_4000MS" 15 "RAMP_3750MS" 14 "RAMP_3500MS" 13 "RAMP_3250MS" 12 "RAMP_3000MS" 11 "RAMP_2750MS" 10 "RAMP_2500MS" 9 "RAMP_2250MS" 8 "RAMP_2000MS" 7 "RAMP_1750MS" 6 "RAMP_1500MS" 5 "RAMP_1250MS" 4 "RAMP_1000MS" 3 "RAMP_750MS" 2 "RAMP_500MS" 1 "RAMP_250MS" 0 "RAMP_INSTANT" ;
VAL_ 1657 UI_rgbBrightnessLevel 127 "SNA" ;
VAL_ 1021 UI_autopilotControlIndex 7 "7" 6 "6" 5 "5" 4 "4" 3 "3" 2 "2" 1 "1" 0 "0" ;
VAL_ 1021 UI_hovEnabled 1 "HOV_ON" 0 "HOV_OFF" ;
VAL_ 1021 UI_smartSetSpeedOffsetType 1 "PERCENTAGE_OFFSET" 0 "FIXED_OFFSET" ;
VAL_ 1021 UI_autosteerActivation 1 "DOUBLE_CLICK" 0 "SINGLE_CLICK" ;
VAL_ 1021 UI_autopilotDrivingProfile 3 "MAD_MAX" 2 "ASSERTIVE" 1 "NORMAL" 0 "CHILL" ;
VAL_ 1021 UI_fsdBetaRequest 1 "FSD_REQUEST_ACTIVE" 0 "FSD_REQUEST_NOT_ACTIVE" ;
VAL_ 1021 UI_selectableCameraRequest 15 "SNA" 13 "REPEATERS_BACKUP" 12 "FASCIA" 11 "GRID_VIEW" 10 "OCTA" 9 "BACKUP" 8 "RIGHT_REPEATER" 7 "RIGHT_PILLAR" 6 "LEFT_REPEATER" 5 "LEFT_PILLAR" 4 "FRONT_NARROW" 3 "FRONT_FISHEYE" 2 "FRONT_MAIN" 1 "SELFIE" 0 "NONE" ;
VAL_ 1021 UI_autoTurnSignalMode 1 "UI_AUTO_TURN_SIGNAL_MODE_AUTO_CANCEL" 0 "UI_AUTO_TURN_SIGNAL_MODE_OFF" ;
VAL_ 819 UI_acChargeCurrentLimit 127 "SNA" ;
VAL_ 819 UI_chargePortLatchRequest 2 "UI_LATCH_REQUEST_DISENGAGE" 1 "UI_LATCH_REQUEST_ENGAGE" 0 "UI_LATCH_REQUEST_NONE" ;
VAL_ 819 UI_cpInletHeaterRequest 2 "HEATER_MANUAL_OVERRIDE" 1 "HEATER_AUTO" 0 "HEATER_OFF" ;
VAL_ 531 UI_cruiseSpeedCommand 6 "CRUISE_SPEED_SNAP_SPEEDO" 5 "CRUISE_SPEED_SNAP" 4 "CRUISE_SPEED_DEC_LONG" 3 "CRUISE_SPEED_DEC_SHORT" 2 "CRUISE_SPEED_INC_LONG" 1 "CRUISE_SPEED_INC_SHORT" 0 "CRUISE_SPEED_IDLE" ;
VAL_ 645 UI_driverProfileRecallIndex 5 "5" 4 "4" 3 "3" 2 "2" 1 "1" 0 "SNA" ;
VAL_ 645 UI_modifyMirrorDipRequest 2 "MODIFY_MIRROR_DIP_REQUEST_DIPPED" 1 "MODIFY_MIRROR_DIP_REQUEST_UNDIPPED" 0 "MODIFY_MIRROR_DIP_REQUEST_NONE" ;
VAL_ 1279 UI_energyConsumptionInfoIndex 21 "21" 20 "20" 19 "19" 18 "18" 17 "17" 16 "16" 15 "15" 14 "14" 13 "13" 12 "12" 11 "11" 10 "10" 9 "9" 8 "8" 7 "7" 6 "6" 5 "5" 4 "4" 3 "3" 2 "2" 1 "1" 0 "0" ;
VAL_ 1139 UI_nmKeepAwakeReason 31 "UI_KEEPAWAKE_REASON_AUTO_CONDITIONING_START" 30 "UI_KEEPAWAKE_REASON_WINDOW_CONTROL" 29 "UI_KEEPAWAKE_REASON_GET_VEHICLE_CONFIGURATION" 28 "UI_KEEPAWAKE_REASON_MOTHERSHIP_SMS_OWNER_WAKE_UP" 27 "UI_KEEPAWAKE_REASON_MOTHERSHIP_SMS_GARAGE_WAKE_UP" 26 "UI_KEEPAWAKE_REASON_MOTHERSHIP_SMS_VEHICLE_TASK" 25 "UI_KEEPAWAKE_REASON_MOTHERSHIP_SMS_YOUVE_GOT_MAIL" 24 "UI_KEEPAWAKE_REASON_WAKE_UP" 23 "UI_KEEPAWAKE_REASON_FIRMWARE_HANDSHAKE" 22 "UI_KEEPAWAKE_REASON_VEHICLE_DATA" 21 "UI_KEEPAWAKE_REASON_DIAG_VITALS" 20 "UI_KEEPAWAKE_REASON_URGENT_UPLOAD" 19 "UI_KEEPAWAKE_REASON_UI_REQUEST_AP_KEEPALIVE" 18 "UI_KEEPAWAKE_REASON_STEAM" 17 "UI_KEEPAWAKE_REASON_CHARGING" 16 "UI_KEEPAWAKE_REASON_UI_HVAC_REQUEST" 15 "UI_KEEPAWAKE_REASON_USER_NOTIFICATION_TIMER" 14 "UI_KEEPAWAKE_REASON_ODIN" 13 "UI_KEEPAWAKE_REASON_MEDIA_DOWNLOAD" 12 "UI_KEEPAWAKE_REASON_SENTRY_MODE" 11 "UI_KEEPAWAKE_REASON_SELFTEST" 10 "UI_KEEPAWAKE_REASON_ECALL_ACTIVE" 9 "UI_KEEPAWAKE_REASON_UPDATE_COUNTDOWN" 8 "UI_KEEPAWAKE_REASON_AUTOFUSER" 7 "UI_KEEPAWAKE_REASON_HERMES" 6 "UI_KEEPAWAKE_REASON_UPDATER" 5 "UI_KEEPAWAKE_REASON_MODEM_RESET" 4 "UI_KEEPAWAKE_REASON_UNKNOWN_REMOTE_REQUEST" 3 "UI_KEEPAWAKE_REASON_PM_CHECKING" 2 "UI_KEEPAWAKE_REASON_GUI_NEVER_SLEEP_SET" 1 "UI_KEEPAWAKE_REASON_KEEPALIVEACTIVE" 0 "UI_KEEPAWAKE_REASON_NONE_SNA" ;
VAL_ 820 UI_pedalMap 2 "PERFORMANCE" 1 "SPORT" 0 "CHILL" ;
VAL_ 820 UI_limitMode 3 "LIMIT_SERVICE" 2 "LIMIT_FACTORY" 1 "LIMIT_VALET" 0 "LIMIT_NORMAL" ;
VAL_ 820 UI_motorOnMode 2 "MOTORONMODE_REAR_ONLY" 1 "MOTORONMODE_FRONT_ONLY" 0 "MOTORONMODE_NORMAL" ;
VAL_ 820 UI_stoppingMode 2 "HOLD" 1 "CREEP" 0 "STANDARD" ;
VAL_ 820 UI_speedLimit 511 "SNA" ;
VAL_ 820 UI_enableSmartShift 2 "ENABLED_P_R_D" 1 "ENABLED_P" 0 "OFF" ;
VAL_ 820 UI_navVehParallelToRdCanContinue 2 "TRUE" 1 "FALSE" 0 "SNA" ;
VAL_ 563 UI_gearRequest 4 "GEAR_REQUEST_DRIVE" 3 "GEAR_REQUEST_NEUTRAL" 2 "GEAR_REQUEST_REVERSE" 1 "GEAR_REQUEST_PARK" 0 "GEAR_REQUEST_IDLE_SNA" ;
VAL_ 991 UI_userActivity 1 "USER_ACTIVE" 0 "USER_IDLE" ;
VAL_ 991 UI_linkState 2 "LINK_STATE_WIFI" 1 "LINK_STATE_CELL" 0 "LINK_STATE_NONE" ;
VAL_ 991 UI_mobileAppConnected 1 "CONNECTED" 0 "NOT_CONNECTED" ;
VAL_ 991 UI_autoshiftDRState 6 "AUTOSHIFT_DR_STATE_BRAKE_GEAR_SHIFT_CONFIRMED_D" 5 "AUTOSHIFT_DR_STATE_BRAKE_GEAR_SHIFT_CONFIRMED_R" 4 "AUTOSHIFT_DR_STATE_BRAKE_STEERING_AND_BRAKE_CONFIRMED" 3 "AUTOSHIFT_DR_STATE_ONLY_STEERING_CONFIRMED" 2 "AUTOSHIFT_DR_STATE_ONLY_BRAKE_CONFIRMED" 1 "AUTOSHIFT_DR_STATE_PROMPT_SHOWING_UNCONFIRMED" 0 "AUTOSHIFT_DR_STATE_INACTIVE" ;
VAL_ 991 UI_wifiBtModuleType 4 "ELEKTRA" 3 "TCU4G" 2 "BCM4359" 1 "QCA6595" 0 "UNKNOWN" ;
VAL_ 991 UI_selfParkState 255 "SNA" 52 "SELF_PARK_USER_PAUSED" 51 "SELF_PARK_REMOTE_PRE_ABORT" 50 "SELF_PARK_RESUME" 49 "SELF_PARK_PAUSE" 48 "SELF_PARK_DV_MISMATCH" 47 "SELF_PARK_DI_PANIC" 46 "SELF_PARK_POST_ACTIVE_FAILURE" 45 "SELF_PARK_POST_ACTIVE_SUCCESS" 44 "SELF_PARK_CANCEL_AUTO_SUMMON" 43 "SELF_PARK_REMOTE_ABORT" 42 "SELF_PARK_OBSTACLE_NOT_CLEARED" 41 "SELF_PARK_OBSTACLE_CLEARED" 40 "SELF_PARK_OPEN_GATE" 39 "SELF_PARK_ACTIVE" 38 "SELF_PARK_STARTED_REVERSE" 37 "SELF_PARK_STARTED_FORWARD" 36 "SELF_PARK_NOT_STARTED_TIMEOUT" 35 "SELF_PARK_PRIMED" 34 "SELF_PARK_PREPRIMED" 33 "SELF_PARK_TURN_ON_DRIVE_RAIL" 32 "SELF_PARK_DETECT_KEY_FOB" 31 "SELF_PARK_WAKE_UP_BUSES" 30 "SELF_PARK_CONNECTING_BLUETOOTH" 29 "SELF_PARK_UNAVAILABLE_CAR_WASH_MODE" 28 "SELF_PARK_UNAVAILABLE_CAR_ALARM" 27 "SELF_PARK_UNAVAILABLE_CRASH_STATE" 26 "SELF_PARK_UNAVAILABLE_DRAG_STRIP_MODE" 25 "SELF_PARK_UNAVAILABLE_TRACK_MODE" 24 "SELF_PARK_UNAVAILABLE_SERVICE_MODE" 23 "SELF_PARK_UNAVAILABLE_DOG_MODE" 22 "SELF_PARK_UNAVAILABLE_GAME_MODE" 21 "SELF_PARK_UNAVAILABLE_BLUETOOTH_CONNECT_TIMEOUT" 20 "SELF_PARK_UNAVAILABLE_WAKEUP_TIMEOUT" 19 "SELF_PARK_UNAVAILABLE_NO_BLUETOOTH_DEVICES_PAIRED" 18 "SELF_PARK_UNAVAILABLE_BRAKE_PRESSED" 17 "SELF_PARK_UNAVAILABLE_ROAD_GRADE" 16 "SELF_PARK_UNAVAILABLE_TRAILER_MODE" 15 "SELF_PARK_UNAVAILABLE_KEY_FOB_BATTERY_LOW" 14 "SELF_PARK_UNAVAILABLE_KEY_FOB_NOT_DETECTED" 13 "SELF_PARK_UNAVAILABLE_PARK_SENSOR_ISSUE" 12 "SELF_PARK_UNAVAILABLE_AUTOSTEER_NOT_ENABLED" 11 "SELF_PARK_UNAVAILABLE_LV_BUS_SUPPORT_ISSUE" 10 "SELF_PARK_UNAVAILABLE_ON_PUBLIC_ROAD" 9 "SELF_PARK_UNAVAILABLE_PARKED_TOO_LONG" 8 "SELF_PARK_UNAVAILABLE_DOOR_OPEN" 7 "SELF_PARK_UNAVAILABLE_TRUNK_OPEN" 6 "SELF_PARK_UNAVAILABLE_FRUNK_OPEN" 5 "SELF_PARK_UNAVAILABLE_PLUGGED_IN" 4 "SELF_PARK_UNAVAILABLE_NOT_PARKED" 3 "SELF_PARK_UNAVAILABLE" 2 "SELF_PARK_IDLE" 1 "SELF_PARK_DRIVING" 0 "SELF_PARK_DISABLED" ;
VAL_ 991 UI_summonDeviceIndex 3 "UNKNOWN" 2 "DEVICE_2" 1 "DEVICE_1" 0 "DEVICE_0" ;
VAL_ 661 UI_systemMonitorIndex 1 "1" 0 "0" ;
VAL_ 787 UI_trackModeRequest 2 "TRACK_MODE_REQUEST_OFF" 1 "TRACK_MODE_REQUEST_ON" 0 "TRACK_MODE_REQUEST_IDLE" ;
VAL_ 787 UI_trackDrivePowerAvailability 2 "TRACK_MODE_POWER_MAX" 1 "TRACK_MODE_POWER_MIDDLE" 0 "TRACK_MODE_POWER_ENDURANCE" ;
VAL_ 130 UI_navFastchargerType 4 "V4" 3 "V3" 2 "V2" 1 "LOW_POWER" 0 "NONE" ;
VAL_ 130 UI_battPreconditionOnNavState 3 "ACTIVE_COOL" 2 "PASSIVE_COOL" 1 "ACTIVE_HEAT" 0 "PASSIVE_HEAT" ;
VAL_ 130 UI_battPreconditionOnNavPowerReq 127 "SNA" 126 "MAX" -126 "MIN" ;
VAL_ 130 UI_battPreconditionOnNavTargetT 255 "SNA" 254 "MAX" 0 "MIN" ;
VAL_ 130 UI_energyAtDestination -32767 "TRIP_TOO_LONG" -32768 "SNA" ;
VAL_ 139 UI_maxSpeedToReachDestination 65535 "SNA" 65534 "UNREACHABLE" 65533 "MAXVAL" ;
VAL_ 139 UI_timeToDestination 65535 "SNA" 65534 "MAXVAL" ;
VAL_ 1173 UI_predictedEnergy -32767 "TRIP_TOO_LONG" -32768 "SNA" ;
VAL_ 1173 UI_hindsightEnergy -32767 "TRIP_TOO_LONG" -32768 "SNA" ;
VAL_ 947 UI_lightSwitch 4 "LIGHT_SWITCH_SNA" 3 "LIGHT_SWITCH_OFF" 2 "LIGHT_SWITCH_PARKING" 1 "LIGHT_SWITCH_ON" 0 "LIGHT_SWITCH_AUTO" ;
VAL_ 947 UI_autopilotPowerStateRequest 2 "AUTOPILOT_SUSPEND" 1 "AUTOPILOT_SENTRY" 0 "AUTOPILOT_NOMINAL" ;
VAL_ 947 UI_frontLeftSeatFanReq 3 "FAN_REQUEST_LEVEL3" 2 "FAN_REQUEST_LEVEL2" 1 "FAN_REQUEST_LEVEL1" 0 "FAN_REQUEST_OFF" ;
VAL_ 947 UI_frontRightSeatFanReq 3 "FAN_REQUEST_LEVEL3" 2 "FAN_REQUEST_LEVEL2" 1 "FAN_REQUEST_LEVEL1" 0 "FAN_REQUEST_OFF" ;
